VERSION "v1.6"

NS_ :

BS_:

BU_: INVCON0 VCU INVCON1 INVCON2 INVCON3 INVCON4 INVCON5

BO_ 292 VCU_INV5_06: 4 VCU
 SG_ SurgeDamperTreshold5 : 12|10@1+ (1,0) [0|1021] "Nm"  INVCON5
 SG_ SurgeDamperState5 : 0|2@1+ (1,0) [0|3] "-"  INVCON5
 SG_ SurgeDamperMaxTorque5 : 2|10@1+ (1,0) [0|1021] "Nm"  INVCON5
 SG_ SurgeDamperFactor5 : 24|8@1+ (0.03125,0) [0|7.96875] "-"  INVCON5

BO_ 291 VCU_INV4_06: 4 VCU
 SG_ SurgeDamperTreshold4 : 12|10@1+ (1,0) [0|1021] "Nm"  INVCON4
 SG_ SurgeDamperState4 : 0|2@1+ (1,0) [0|3] "-"  INVCON4
 SG_ SurgeDamperMaxTorque4 : 2|10@1+ (1,0) [0|1021] "Nm"  INVCON4
 SG_ SurgeDamperFactor4 : 24|8@1+ (0.03125,0) [0|7.96875] "-"  INVCON4

BO_ 290 VCU_INV3_06: 4 VCU
 SG_ SurgeDamperTreshold3 : 12|10@1+ (1,0) [0|1021] "Nm"  INVCON3
 SG_ SurgeDamperState3 : 0|2@1+ (1,0) [0|3] "-"  INVCON3
 SG_ SurgeDamperMaxTorque3 : 2|10@1+ (1,0) [0|1021] "Nm"  INVCON3
 SG_ SurgeDamperFactor3 : 24|8@1+ (0.03125,0) [0|7.96875] "-"  INVCON3

BO_ 289 VCU_INV2_06: 4 VCU
 SG_ SurgeDamperTreshold2 : 12|10@1+ (1,0) [0|1021] "Nm"  INVCON2
 SG_ SurgeDamperState2 : 0|2@1+ (1,0) [0|3] "-"  INVCON2
 SG_ SurgeDamperMaxTorque2 : 2|10@1+ (1,0) [0|1021] "Nm"  INVCON2
 SG_ SurgeDamperFactor2 : 24|8@1+ (0.03125,0) [0|7.96875] "-"  INVCON2

BO_ 288 VCU_INV1_06: 4 VCU
 SG_ SurgeDamperTreshold1 : 12|10@1+ (1,0) [0|1021] "Nm"  INVCON1
 SG_ SurgeDamperState1 : 0|2@1+ (1,0) [0|3] "-"  INVCON1
 SG_ SurgeDamperMaxTorque1 : 2|10@1+ (1,0) [0|1021] "Nm"  INVCON1
 SG_ SurgeDamperFactor1 : 24|8@1+ (0.03125,0) [0|7.96875] "-"  INVCON1

BO_ 1663 INV0_VCU_07: 8 INVCON0
 SG_ INV0_FailCode4 : 48|16@1+ (1,0) [0|65535] "-"  VCU
 SG_ INV0_FailCode3 : 32|16@1+ (1,0) [0|65535] "-"  VCU
 SG_ INV0_FailCode2 : 16|16@1+ (1,0) [0|65535] "-"  VCU
 SG_ INV0_FailCode1 : 0|16@1+ (1,0) [0|65535] "-"  VCU

BO_ 1668 INV5_VCU_07: 8 INVCON5
 SG_ INV5_FailCode4 : 48|16@1+ (1,0) [0|65535] "-"  VCU
 SG_ INV5_FailCode3 : 32|16@1+ (1,0) [0|65535] "-"  VCU
 SG_ INV5_FailCode2 : 16|16@1+ (1,0) [0|65535] "-"  VCU
 SG_ INV5_FailCode1 : 0|16@1+ (1,0) [0|65535] "-"  VCU

BO_ 1667 INV4_VCU_07: 8 INVCON4
 SG_ INV4_FailCode4 : 48|16@1+ (1,0) [0|65535] "-"  VCU
 SG_ INV4_FailCode3 : 32|16@1+ (1,0) [0|65535] "-"  VCU
 SG_ INV4_FailCode2 : 16|16@1+ (1,0) [0|65535] "-"  VCU
 SG_ INV4_FailCode1 : 0|16@1+ (1,0) [0|65535] "-"  VCU

BO_ 1666 INV3_VCU_07: 8 INVCON3
 SG_ INV3_FailCode4 : 48|16@1+ (1,0) [0|65535] "-"  VCU
 SG_ INV3_FailCode3 : 32|16@1+ (1,0) [0|65535] "-"  VCU
 SG_ INV3_FailCode2 : 16|16@1+ (1,0) [0|65535] "-"  VCU
 SG_ INV3_FailCode1 : 0|16@1+ (1,0) [0|65535] "-"  VCU

BO_ 1665 INV2_VCU_07: 8 INVCON2
 SG_ INV2_FailCode4 : 48|16@1+ (1,0) [0|65535] "-"  VCU
 SG_ INV2_FailCode3 : 32|16@1+ (1,0) [0|65535] "-"  VCU
 SG_ INV2_FailCode2 : 16|16@1+ (1,0) [0|65535] "-"  VCU
 SG_ INV2_FailCode1 : 0|16@1+ (1,0) [0|65535] "-"  VCU

BO_ 1664 INV1_VCU_07: 8 INVCON1
 SG_ INV1_FailCode4 : 48|16@1+ (1,0) [0|65535] "-"  VCU
 SG_ INV1_FailCode3 : 32|16@1+ (1,0) [0|65535] "-"  VCU
 SG_ INV1_FailCode2 : 16|16@1+ (1,0) [0|65535] "-"  VCU
 SG_ INV1_FailCode1 : 0|16@1+ (1,0) [0|65535] "-"  VCU

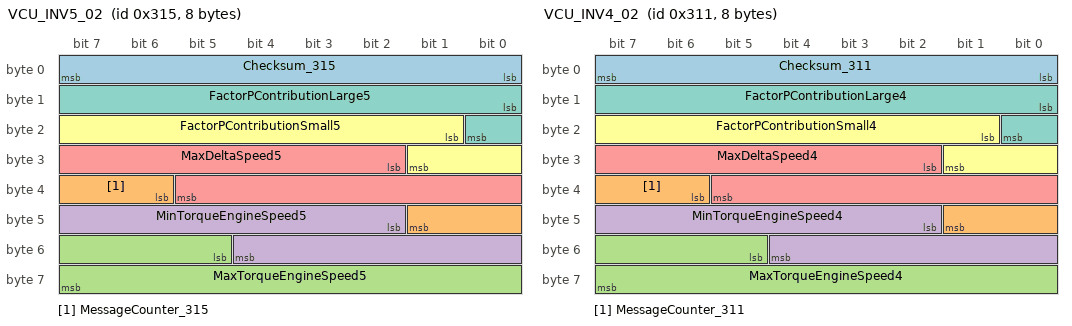
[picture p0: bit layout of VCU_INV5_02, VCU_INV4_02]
BO_ 789 VCU_INV5_02: 8 VCU
 SG_ Checksum_315 : 0|8@1+ (1,0) [0|255] "-"  INVCON5
 SG_ MessageCounter_315 : 38|4@1+ (1,0) [0|15] "-"  INVCON5
 SG_ MaxTorqueEngineSpeed5 : 53|11@1+ (1,-1023) [-1023|1022] "Nm"  INVCON5
 SG_ MinTorqueEngineSpeed5 : 42|11@1+ (1,-1023) [-1023|1022] "Nm"  INVCON5
 SG_ MaxDeltaSpeed5 : 26|12@1+ (8,-16380) [-16380|16364] "1/min"  INVCON5
 SG_ FactorPContributionSmall5 : 17|9@1+ (0.0009765625,0) [0|0.4990234375] "-"  INVCON5
 SG_ FactorPContributionLarge5 : 8|9@1+ (0.0009765625,0) [0|0.4990234375] "-"  INVCON5

BO_ 785 VCU_INV4_02: 8 VCU
 SG_ Checksum_311 : 0|8@1+ (1,0) [0|255] "-"  INVCON4
 SG_ MessageCounter_311 : 38|4@1+ (1,0) [0|15] "-"  INVCON4
 SG_ MaxTorqueEngineSpeed4 : 53|11@1+ (1,-1023) [-1023|1022] "Nm"  INVCON4
 SG_ MinTorqueEngineSpeed4 : 42|11@1+ (1,-1023) [-1023|1022] "Nm"  INVCON4
 SG_ MaxDeltaSpeed4 : 26|12@1+ (8,-16380) [-16380|16364] "1/min"  INVCON4
 SG_ FactorPContributionSmall4 : 17|9@1+ (0.0009765625,0) [0|0.4990234375] "-"  INVCON4
 SG_ FactorPContributionLarge4 : 8|9@1+ (0.0009765625,0) [0|0.4990234375] "-"  INVCON4

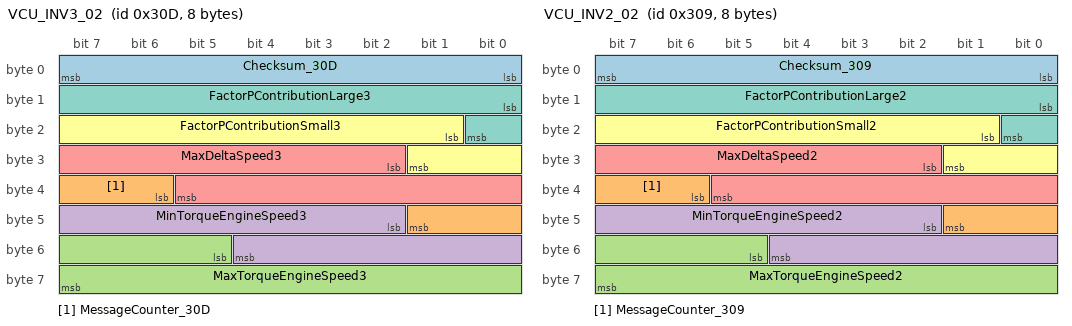
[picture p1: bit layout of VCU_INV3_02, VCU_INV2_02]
BO_ 781 VCU_INV3_02: 8 VCU
 SG_ Checksum_30D : 0|8@1+ (1,0) [0|255] "-"  INVCON3
 SG_ MessageCounter_30D : 38|4@1+ (1,0) [0|15] "-"  INVCON3
 SG_ MaxTorqueEngineSpeed3 : 53|11@1+ (1,-1023) [-1023|1022] "Nm"  INVCON3
 SG_ MinTorqueEngineSpeed3 : 42|11@1+ (1,-1023) [-1023|1022] "Nm"  INVCON3
 SG_ MaxDeltaSpeed3 : 26|12@1+ (8,-16380) [-16380|16364] "1/min"  INVCON3
 SG_ FactorPContributionSmall3 : 17|9@1+ (0.0009765625,0) [0|0.4990234375] "-"  INVCON3
 SG_ FactorPContributionLarge3 : 8|9@1+ (0.0009765625,0) [0|0.4990234375] "-"  INVCON3

BO_ 777 VCU_INV2_02: 8 VCU
 SG_ Checksum_309 : 0|8@1+ (1,0) [0|255] "-"  INVCON2
 SG_ MessageCounter_309 : 38|4@1+ (1,0) [0|15] "-"  INVCON2
 SG_ MaxTorqueEngineSpeed2 : 53|11@1+ (1,-1023) [-1023|1022] "Nm"  INVCON2
 SG_ MinTorqueEngineSpeed2 : 42|11@1+ (1,-1023) [-1023|1022] "Nm"  INVCON2
 SG_ MaxDeltaSpeed2 : 26|12@1+ (8,-16380) [-16380|16364] "1/min"  INVCON2
 SG_ FactorPContributionSmall2 : 17|9@1+ (0.0009765625,0) [0|0.4990234375] "-"  INVCON2
 SG_ FactorPContributionLarge2 : 8|9@1+ (0.0009765625,0) [0|0.4990234375] "-"  INVCON2

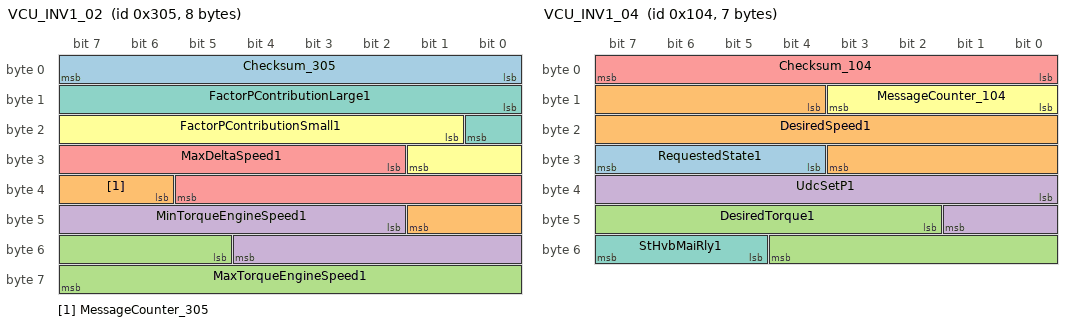
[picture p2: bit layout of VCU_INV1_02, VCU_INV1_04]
BO_ 773 VCU_INV1_02: 8 VCU
 SG_ Checksum_305 : 0|8@1+ (1,0) [0|255] "-"  INVCON1
 SG_ MessageCounter_305 : 38|4@1+ (1,0) [0|15] "-"  INVCON1
 SG_ MaxTorqueEngineSpeed1 : 53|11@1+ (1,-1023) [-1023|1022] "Nm"  INVCON1
 SG_ MinTorqueEngineSpeed1 : 42|11@1+ (1,-1023) [-1023|1022] "Nm"  INVCON1
 SG_ MaxDeltaSpeed1 : 26|12@1+ (8,-16380) [-16380|16364] "1/min"  INVCON1
 SG_ FactorPContributionSmall1 : 17|9@1+ (0.0009765625,0) [0|0.4990234375] "-"  INVCON1
 SG_ FactorPContributionLarge1 : 8|9@1+ (0.0009765625,0) [0|0.4990234375] "-"  INVCON1

BO_ 260 VCU_INV1_04: 7 VCU
 SG_ RequestedState1 : 28|4@1+ (1,0) [0|15] "-"  INVCON1
 SG_ DesiredSpeed1 : 12|16@1+ (1,-32767) [-32767|32766] "1/min"  INVCON1
 SG_ DesiredTorque1 : 42|11@1+ (1,-1023) [-1023|1022] "Nm"  INVCON1
 SG_ UdcSetP1 : 32|10@1+ (1,0) [0|1021] "V"  INVCON1
 SG_ Checksum_104 : 0|8@1+ (1,0) [0|255] "-"  INVCON1
 SG_ MessageCounter_104 : 8|4@1+ (1,0) [0|15] "-"  INVCON1
 SG_ StHvbMaiRly1 : 53|3@1+ (1,0) [0|7] "-"  INVCON1

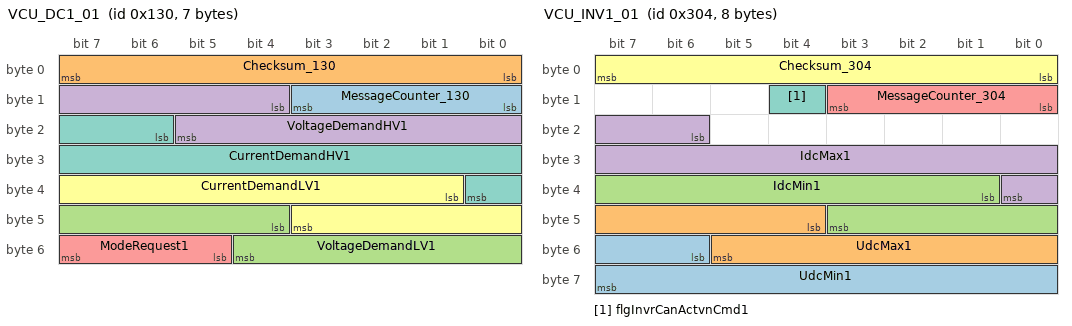
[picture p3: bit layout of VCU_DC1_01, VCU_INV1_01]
BO_ 304 VCU_DC1_01: 7 VCU
 SG_ MessageCounter_130 : 8|4@1+ (1,0) [0|15] "-"  INVCON1
 SG_ Checksum_130 : 0|8@1+ (1,0) [0|255] "-"  INVCON1
 SG_ VoltageDemandLV1 : 44|9@1+ (0.125,0) [0|63.875] "V"  INVCON1
 SG_ VoltageDemandHV1 : 12|10@1+ (1,0) [0|1021] "V"  INVCON1
 SG_ ModeRequest1 : 53|3@1+ (1,0) [0|7] "-"  INVCON1
 SG_ CurrentDemandLV1 : 33|11@1+ (1,-1023) [-1023|1022] "A"  INVCON1
 SG_ CurrentDemandHV1 : 22|11@1+ (0.0625,-64) [-64|63.8125] "A"  INVCON1

BO_ 772 VCU_INV1_01: 8 VCU
 SG_ UdcMin1 : 54|10@1+ (1,0) [0|1021] "V"  INVCON1
 SG_ UdcMax1 : 44|10@1+ (1,0) [0|1021] "V"  INVCON1
 SG_ IdcMin1 : 33|11@1+ (1,-1023) [-1023|1022] "A"  INVCON1
 SG_ IdcMax1 : 22|11@1+ (1,-1023) [-1023|1022] "A"  INVCON1
 SG_ MessageCounter_304 : 8|4@1+ (1,0) [0|15] "-"  INVCON1
 SG_ Checksum_304 : 0|8@1+ (1,0) [0|255] "-"  INVCON1
 SG_ flgInvrCanActvnCmd1 : 12|1@1+ (1,0) [0|1] "-"  INVCON1

BO_ 774 VCU_INV1_03: 8 VCU
 SG_ KI_Faktor1 : 49|15@1+ (0.0009765625,0) [0|31.9990234375] "-"  INVCON1
 SG_ MessageCounter_306 : 8|4@1+ (1,0) [0|15] "-"  INVCON1
 SG_ Checksum_306 : 0|8@1+ (1,0) [0|255] "-"  INVCON1
 SG_ MinTorqueLimit1 : 12|11@1+ (1,-1023) [-1023|1022] "Nm"  INVCON1
 SG_ MaxTorqueLimit1 : 38|11@1+ (1,-1023) [-1023|1022] "Nm"  INVCON1
 SG_ MaxTorqueGradient1 : 23|15@1+ (32,0) [0|1048480] "Nm/s"  INVCON1

BO_ 516 INV1_VCU_01: 7 INVCON1
 SG_ CurrentHV1 : 32|11@1+ (1,-1023) [-1023|1024] "A"  VCU
 SG_ OutputTorque1 : 43|11@1+ (1,-1023) [-1023|1024] "Nm"  VCU
 SG_ State1 : 12|4@1+ (1,0) [0|15] "-"  VCU
 SG_ Speed1 : 16|16@1+ (1,-32767) [-32767|32766] "1/min"  VCU
 SG_ Checksum_204 : 0|8@1+ (1,0) [0|255] "-"  VCU
 SG_ MessageCounter_204 : 8|4@1+ (1,0) [0|15] "-"  VCU

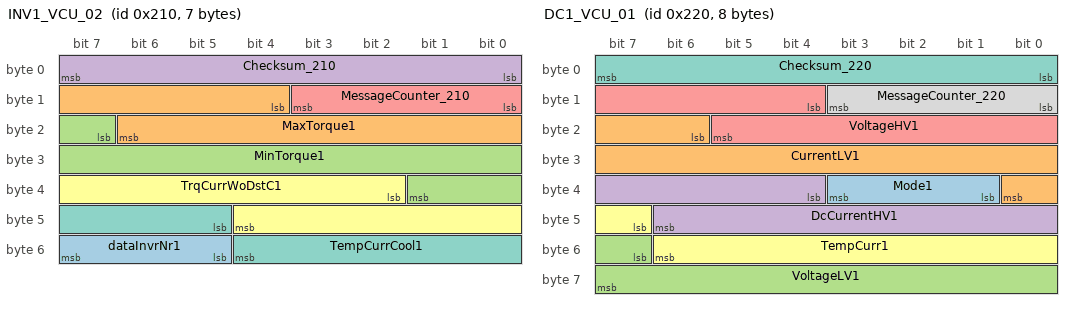
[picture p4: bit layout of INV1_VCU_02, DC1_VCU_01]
BO_ 528 INV1_VCU_02: 7 INVCON1
 SG_ dataInvrNr1 : 53|3@1+ (1,0) [0|5] ""  VCU
 SG_ MaxTorque1 : 12|11@1+ (1,-1023) [-1023|1024] "Nm"  VCU
 SG_ MinTorque1 : 23|11@1+ (1,-1023) [-1023|1024] "Nm"  VCU
 SG_ Checksum_210 : 0|8@1+ (1,0) [0|255] "-"  VCU
 SG_ MessageCounter_210 : 8|4@1+ (1,0) [0|15] "-"  VCU
 SG_ TrqCurrWoDstC1 : 34|11@1+ (1,-1023) [-1023|1024] "Nm"  VCU
 SG_ TempCurrCool1 : 45|8@1+ (1,-40) [-40|213] "°C"  VCU

BO_ 544 DC1_VCU_01: 8 INVCON1
 SG_ Mode1 : 33|3@1+ (1,0) [0|7] "-"  VCU
 SG_ CurrentLV1 : 22|11@1+ (1,-1023) [-1023|1024] "A"  VCU
 SG_ VoltageLV1 : 55|9@1+ (0.125,0) [0|63.875] "V"  VCU
 SG_ DcCurrentHV1 : 36|11@1+ (0.0625,-64) [-64|63.9375] "A"  VCU
 SG_ VoltageHV1 : 12|10@1+ (1,0) [0|1023] "V"  VCU
 SG_ TempCurr1 : 47|8@1+ (1,-40) [-40|213] "°C"  VCU
 SG_ Checksum_220 : 0|8@1+ (1,0) [0|255] "-"  VCU
 SG_ MessageCounter_220 : 8|4@1+ (1,0) [0|15] "-"  VCU

BO_ 1568 INV1_VCU_04: 6 INVCON1
 SG_ ElectricMachineTemperature1 : 16|8@1+ (1,-40) [-40|213] "°C"  VCU
 SG_ InverterTemperature1 : 24|8@1+ (1,-40) [-40|213] "°C"  VCU
 SG_ UT30Curr1 : 32|6@1+ (0.5,0) [0|31.5] "V"  VCU
 SG_ TempCurrRotor1 : 38|8@1+ (1,-40) [-40|213] "°C"  VCU
 SG_ Checksum_620 : 0|8@1+ (1,0) [0|255] "-"  VCU
 SG_ MessageCounter_620 : 8|4@1+ (1,0) [0|15] "-"  VCU

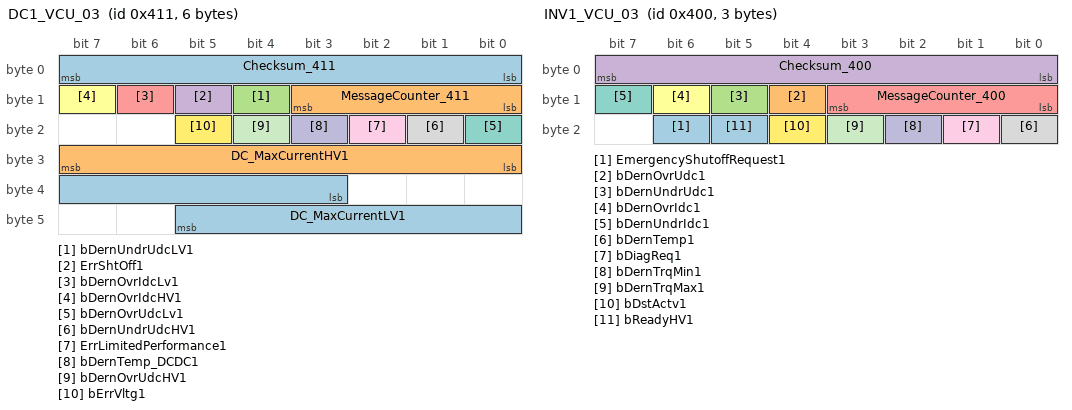
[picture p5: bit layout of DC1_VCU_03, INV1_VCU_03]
BO_ 1041 DC1_VCU_03: 6 INVCON1
 SG_ DC_MaxCurrentLV1 : 35|11@1+ (1,-1023) [-1023|1024] "A"  VCU
 SG_ DC_MaxCurrentHV1 : 24|8@1+ (0.25,0) [0|63.75] "A"  VCU
 SG_ bDernUndrUdcLV1 : 12|1@1+ (1,0) [0|1] "-"  VCU
 SG_ ErrShtOff1 : 13|1@1+ (1,0) [0|1] "-"  VCU
 SG_ bDernOvrIdcLv1 : 14|1@1+ (1,0) [0|1] "-"  VCU
 SG_ bDernOvrIdcHV1 : 15|1@1+ (1,0) [0|1] "-"  VCU
 SG_ bDernOvrUdcLv1 : 16|1@1+ (1,0) [0|1] "-"  VCU
 SG_ bDernUndrUdcHV1 : 17|1@1+ (1,0) [0|1] "-"  VCU
 SG_ ErrLimitedPerformance1 : 18|1@1+ (1,0) [0|1] "-"  VCU
 SG_ bDernTemp_DCDC1 : 19|1@1+ (1,0) [0|1] "-"  VCU
 SG_ bDernOvrUdcHV1 : 20|1@1+ (1,0) [0|1] "-"  VCU
 SG_ bErrVltg1 : 21|1@1+ (1,0) [0|1] "-"  VCU
 SG_ Checksum_411 : 0|8@1+ (1,0) [0|255] "-"  VCU
 SG_ MessageCounter_411 : 8|4@1+ (1,0) [0|15] "-"  VCU

BO_ 1024 INV1_VCU_03: 3 INVCON1
 SG_ EmergencyShutoffRequest1 : 22|1@1+ (1,0) [0|1] "-"  VCU
 SG_ bDernOvrUdc1 : 12|1@1+ (1,0) [0|1] "-"  VCU
 SG_ bDernUndrUdc1 : 13|1@1+ (1,0) [0|1] "-"  VCU
 SG_ Checksum_400 : 0|8@1+ (1,0) [0|255] "-"  VCU
 SG_ MessageCounter_400 : 8|4@1+ (1,0) [0|15] "-"  VCU
 SG_ bDernOvrIdc1 : 14|1@1+ (1,0) [0|1] "-"  VCU
 SG_ bDernUndrIdc1 : 15|1@1+ (1,0) [0|1] "-"  VCU
 SG_ bDernTemp1 : 16|1@1+ (1,0) [0|1] "-"  VCU
 SG_ bDiagReq1 : 17|1@1+ (1,0) [0|1] "-"  VCU
 SG_ bDernTrqMin1 : 18|1@1+ (1,0) [0|1] "-"  VCU
 SG_ bDernTrqMax1 : 19|1@1+ (1,0) [0|1] "-"  VCU
 SG_ bDstActv1 : 20|1@1+ (1,0) [0|1] "-"  VCU
 SG_ bReadyHV1 : 21|1@1+ (1,0) [0|1] "-"  VCU

BO_ 110 BMS_VCU_INV_01: 7 VCU
 SG_ bErrEmergencyDischargeReq : 36|1@1+ (1,0) [0|1] ""  INVCON1,INVCON2,INVCON3,INVCON5,INVCON4
 SG_ MessageCounter_6E : 8|4@1+ (1,0) [0|15] "-"  INVCON1,INVCON2,INVCON3,INVCON4,INVCON5
 SG_ Checksum_6E : 0|8@1+ (1,0) [0|255] "-"  INVCON1,INVCON2,INVCON3,INVCON4,INVCON5
 SG_ ContactorState : 48|4@1+ (1,0) [0|7] "-"  INVCON1,INVCON2,INVCON3,INVCON4,INVCON5
 SG_ Current : 12|12@1+ (0.25,-511) [-511|512.25] "A"  INVCON1,INVCON2,INVCON3,INVCON4,INVCON5
 SG_ Voltage : 24|12@1+ (0.25,0) [0|1023.25] "V"  INVCON1,INVCON2,INVCON3,INVCON4,INVCON5

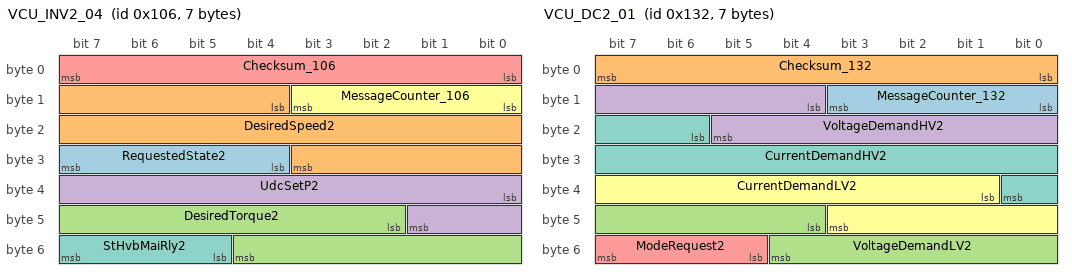
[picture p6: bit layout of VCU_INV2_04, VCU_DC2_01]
BO_ 262 VCU_INV2_04: 7 VCU
 SG_ RequestedState2 : 28|4@1+ (1,0) [0|15] "-"  INVCON2
 SG_ DesiredSpeed2 : 12|16@1+ (1,-32767) [-32767|32766] "1/min"  INVCON2
 SG_ DesiredTorque2 : 42|11@1+ (1,-1023) [-1023|1022] "Nm"  INVCON2
 SG_ UdcSetP2 : 32|10@1+ (1,0) [0|1021] "V"  INVCON2
 SG_ Checksum_106 : 0|8@1+ (1,0) [0|255] "-"  INVCON2
 SG_ MessageCounter_106 : 8|4@1+ (1,0) [0|15] "-"  INVCON2
 SG_ StHvbMaiRly2 : 53|3@1+ (1,0) [0|7] "-"  INVCON2

BO_ 306 VCU_DC2_01: 7 VCU
 SG_ MessageCounter_132 : 8|4@1+ (1,0) [0|15] "-"  INVCON2
 SG_ Checksum_132 : 0|8@1+ (1,0) [0|255] "-"  INVCON2
 SG_ VoltageDemandLV2 : 44|9@1+ (0.125,0) [0|63.875] "V"  INVCON2
 SG_ VoltageDemandHV2 : 12|10@1+ (1,0) [0|1021] "V"  INVCON2
 SG_ ModeRequest2 : 53|3@1+ (1,0) [0|7] "-"  INVCON2
 SG_ CurrentDemandLV2 : 33|11@1+ (1,-1023) [-1023|1022] "A"  INVCON2
 SG_ CurrentDemandHV2 : 22|11@1+ (0.0625,-64) [-64|63.8125] "A"  INVCON2

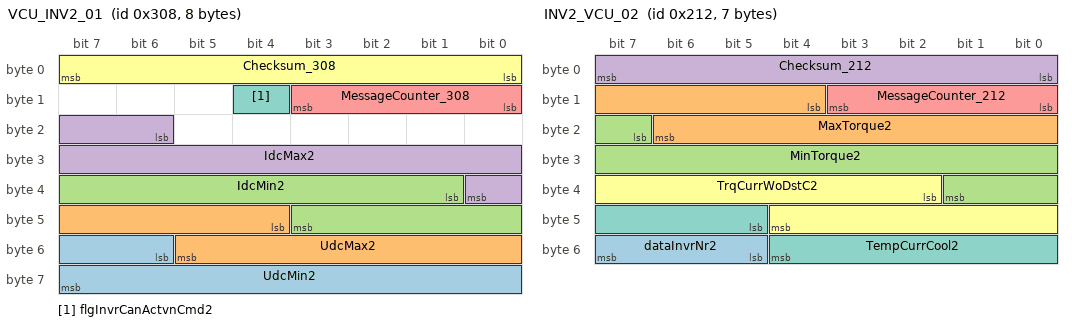
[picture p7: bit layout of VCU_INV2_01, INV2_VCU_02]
BO_ 776 VCU_INV2_01: 8 VCU
 SG_ UdcMin2 : 54|10@1+ (1,0) [0|1021] "V"  INVCON2
 SG_ UdcMax2 : 44|10@1+ (1,0) [0|1021] "V"  INVCON2
 SG_ IdcMin2 : 33|11@1+ (1,-1023) [-1023|1022] "A"  INVCON2
 SG_ IdcMax2 : 22|11@1+ (1,-1023) [-1023|1022] "A"  INVCON2
 SG_ MessageCounter_308 : 8|4@1+ (1,0) [0|15] "-"  INVCON2
 SG_ Checksum_308 : 0|8@1+ (1,0) [0|255] "-"  INVCON2
 SG_ flgInvrCanActvnCmd2 : 12|1@1+ (1,0) [0|1] "-"  INVCON2

BO_ 778 VCU_INV2_03: 8 VCU
 SG_ KI_Faktor2 : 49|15@1+ (0.0009765625,0) [0|31.9990234375] "-"  INVCON2
 SG_ MessageCounter_30A : 8|4@1+ (1,0) [0|15] "-"  INVCON2
 SG_ Checksum_30A : 0|8@1+ (1,0) [0|255] "-"  INVCON2
 SG_ MinTorqueLimit2 : 12|11@1+ (1,-1023) [-1023|1022] "Nm"  INVCON2
 SG_ MaxTorqueLimit2 : 38|11@1+ (1,-1023) [-1023|1022] "Nm"  INVCON2
 SG_ MaxTorqueGradient2 : 23|15@1+ (32,0) [0|1048480] "Nm/s"  INVCON2

BO_ 518 INV2_VCU_01: 7 INVCON2
 SG_ CurrentHV2 : 32|11@1+ (1,-1023) [-1023|1024] "A"  VCU
 SG_ OutputTorque2 : 43|11@1+ (1,-1023) [-1023|1024] "Nm"  VCU
 SG_ State2 : 12|4@1+ (1,0) [0|15] "-"  VCU
 SG_ Speed2 : 16|16@1+ (1,-32767) [-32767|32766] "1/min"  VCU
 SG_ Checksum_206 : 0|8@1+ (1,0) [0|255] "-"  VCU
 SG_ MessageCounter_206 : 8|4@1+ (1,0) [0|15] "-"  VCU

BO_ 530 INV2_VCU_02: 7 INVCON2
 SG_ dataInvrNr2 : 53|3@1+ (1,0) [0|5] ""  VCU
 SG_ MaxTorque2 : 12|11@1+ (1,-1023) [-1023|1024] "Nm"  VCU
 SG_ MinTorque2 : 23|11@1+ (1,-1023) [-1023|1024] "Nm"  VCU
 SG_ Checksum_212 : 0|8@1+ (1,0) [0|255] "-"  VCU
 SG_ MessageCounter_212 : 8|4@1+ (1,0) [0|15] "-"  VCU
 SG_ TrqCurrWoDstC2 : 34|11@1+ (1,-1023) [-1023|1024] "Nm"  VCU
 SG_ TempCurrCool2 : 45|8@1+ (1,-40) [-40|213] "°C"  VCU

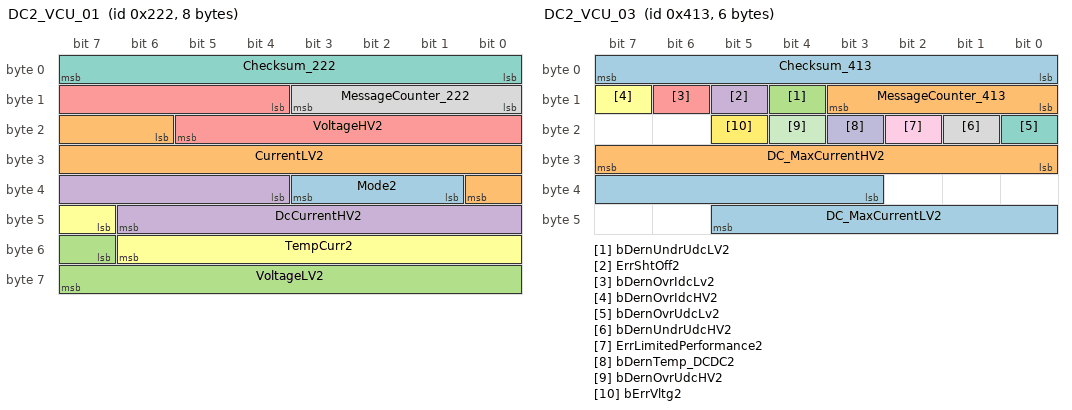
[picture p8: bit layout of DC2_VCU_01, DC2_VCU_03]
BO_ 546 DC2_VCU_01: 8 INVCON2
 SG_ Mode2 : 33|3@1+ (1,0) [0|7] "-"  VCU
 SG_ CurrentLV2 : 22|11@1+ (1,-1023) [-1023|1024] "A"  VCU
 SG_ VoltageLV2 : 55|9@1+ (0.125,0) [0|63.875] "V"  VCU
 SG_ DcCurrentHV2 : 36|11@1+ (0.0625,-64) [-64|63.9375] "A"  VCU
 SG_ VoltageHV2 : 12|10@1+ (1,0) [0|1023] "V"  VCU
 SG_ TempCurr2 : 47|8@1+ (1,-40) [-40|213] "°C"  VCU
 SG_ Checksum_222 : 0|8@1+ (1,0) [0|255] "-"  VCU
 SG_ MessageCounter_222 : 8|4@1+ (1,0) [0|15] "-"  VCU

BO_ 1570 INV2_VCU_04: 6 INVCON2
 SG_ ElectricMachineTemperature2 : 16|8@1+ (1,-40) [-40|213] "°C"  VCU
 SG_ InverterTemperature2 : 24|8@1+ (1,-40) [-40|213] "°C"  VCU
 SG_ UT30Curr2 : 32|6@1+ (0.5,0) [0|31.5] "V"  VCU
 SG_ TempCurrRotor2 : 38|8@1+ (1,-40) [-40|213] "°C"  VCU
 SG_ Checksum_622 : 0|8@1+ (1,0) [0|255] "-"  VCU
 SG_ MessageCounter_622 : 8|4@1+ (1,0) [0|15] "-"  VCU

BO_ 1043 DC2_VCU_03: 6 INVCON2
 SG_ DC_MaxCurrentLV2 : 35|11@1+ (1,-1023) [-1023|1024] "A"  VCU
 SG_ DC_MaxCurrentHV2 : 24|8@1+ (0.25,0) [0|63.75] "A"  VCU
 SG_ bDernUndrUdcLV2 : 12|1@1+ (1,0) [0|1] "-"  VCU
 SG_ ErrShtOff2 : 13|1@1+ (1,0) [0|1] "-"  VCU
 SG_ bDernOvrIdcLv2 : 14|1@1+ (1,0) [0|1] "-"  VCU
 SG_ bDernOvrIdcHV2 : 15|1@1+ (1,0) [0|1] "-"  VCU
 SG_ bDernOvrUdcLv2 : 16|1@1+ (1,0) [0|1] "-"  VCU
 SG_ bDernUndrUdcHV2 : 17|1@1+ (1,0) [0|1] "-"  VCU
 SG_ ErrLimitedPerformance2 : 18|1@1+ (1,0) [0|1] "-"  VCU
 SG_ bDernTemp_DCDC2 : 19|1@1+ (1,0) [0|1] "-"  VCU
 SG_ bDernOvrUdcHV2 : 20|1@1+ (1,0) [0|1] "-"  VCU
 SG_ bErrVltg2 : 21|1@1+ (1,0) [0|1] "-"  VCU
 SG_ Checksum_413 : 0|8@1+ (1,0) [0|255] "-"  VCU
 SG_ MessageCounter_413 : 8|4@1+ (1,0) [0|15] "-"  VCU

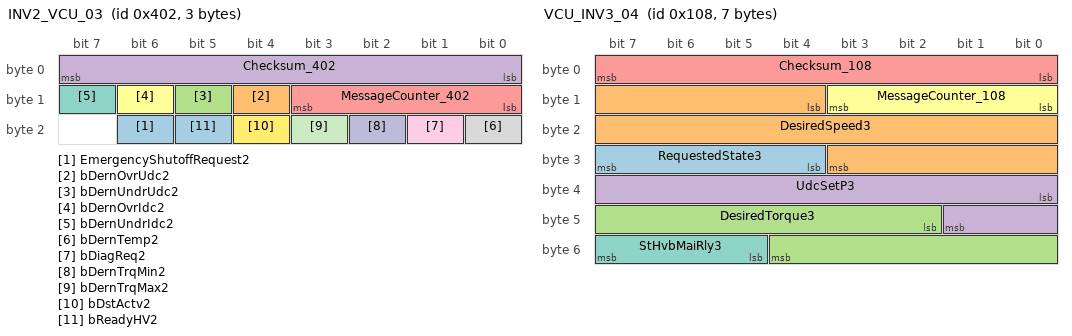
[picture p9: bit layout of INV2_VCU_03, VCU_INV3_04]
BO_ 1026 INV2_VCU_03: 3 INVCON2
 SG_ EmergencyShutoffRequest2 : 22|1@1+ (1,0) [0|1] "-"  VCU
 SG_ bDernOvrUdc2 : 12|1@1+ (1,0) [0|1] "-"  VCU
 SG_ bDernUndrUdc2 : 13|1@1+ (1,0) [0|1] "-"  VCU
 SG_ Checksum_402 : 0|8@1+ (1,0) [0|255] "-"  VCU
 SG_ MessageCounter_402 : 8|4@1+ (1,0) [0|15] "-"  VCU
 SG_ bDernOvrIdc2 : 14|1@1+ (1,0) [0|1] "-"  VCU
 SG_ bDernUndrIdc2 : 15|1@1+ (1,0) [0|1] "-"  VCU
 SG_ bDernTemp2 : 16|1@1+ (1,0) [0|1] "-"  VCU
 SG_ bDiagReq2 : 17|1@1+ (1,0) [0|1] "-"  VCU
 SG_ bDernTrqMin2 : 18|1@1+ (1,0) [0|1] "-"  VCU
 SG_ bDernTrqMax2 : 19|1@1+ (1,0) [0|1] "-"  VCU
 SG_ bDstActv2 : 20|1@1+ (1,0) [0|1] "-"  VCU
 SG_ bReadyHV2 : 21|1@1+ (1,0) [0|1] "-"  VCU

BO_ 264 VCU_INV3_04: 7 VCU
 SG_ RequestedState3 : 28|4@1+ (1,0) [0|15] "-"  INVCON3
 SG_ DesiredSpeed3 : 12|16@1+ (1,-32767) [-32767|32766] "1/min"  INVCON3
 SG_ DesiredTorque3 : 42|11@1+ (1,-1023) [-1023|1022] "Nm"  INVCON3
 SG_ UdcSetP3 : 32|10@1+ (1,0) [0|1021] "V"  INVCON3
 SG_ Checksum_108 : 0|8@1+ (1,0) [0|255] "-"  INVCON3
 SG_ MessageCounter_108 : 8|4@1+ (1,0) [0|15] "-"  INVCON3
 SG_ StHvbMaiRly3 : 53|3@1+ (1,0) [0|7] "-"  INVCON3

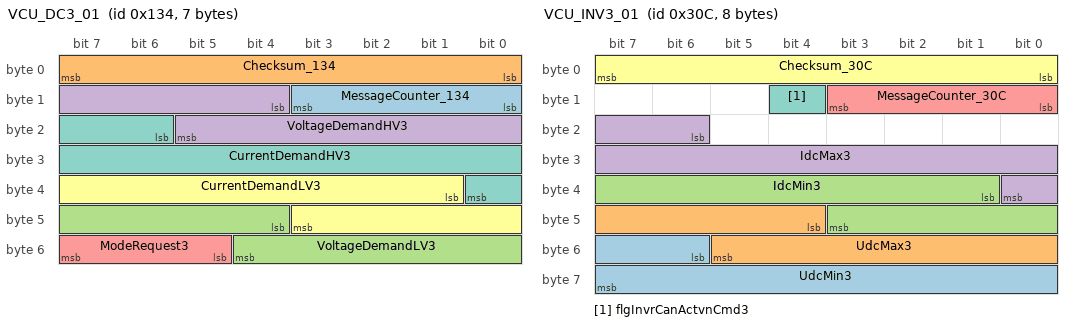
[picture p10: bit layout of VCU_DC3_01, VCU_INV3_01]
BO_ 308 VCU_DC3_01: 7 VCU
 SG_ MessageCounter_134 : 8|4@1+ (1,0) [0|15] "-"  INVCON3
 SG_ Checksum_134 : 0|8@1+ (1,0) [0|255] "-"  INVCON3
 SG_ VoltageDemandLV3 : 44|9@1+ (0.125,0) [0|63.875] "V"  INVCON3
 SG_ VoltageDemandHV3 : 12|10@1+ (1,0) [0|1021] "V"  INVCON3
 SG_ ModeRequest3 : 53|3@1+ (1,0) [0|7] "-"  INVCON3
 SG_ CurrentDemandLV3 : 33|11@1+ (1,-1023) [-1023|1022] "A"  INVCON3
 SG_ CurrentDemandHV3 : 22|11@1+ (0.0625,-64) [-64|63.8125] "A"  INVCON3

BO_ 780 VCU_INV3_01: 8 VCU
 SG_ UdcMin3 : 54|10@1+ (1,0) [0|1021] "V"  INVCON3
 SG_ UdcMax3 : 44|10@1+ (1,0) [0|1021] "V"  INVCON3
 SG_ IdcMin3 : 33|11@1+ (1,-1023) [-1023|1022] "A"  INVCON3
 SG_ IdcMax3 : 22|11@1+ (1,-1023) [-1023|1022] "A"  INVCON3
 SG_ MessageCounter_30C : 8|4@1+ (1,0) [0|15] "-"  INVCON3
 SG_ Checksum_30C : 0|8@1+ (1,0) [0|255] "-"  INVCON3
 SG_ flgInvrCanActvnCmd3 : 12|1@1+ (1,0) [0|1] "-"  INVCON3

BO_ 782 VCU_INV3_03: 8 VCU
 SG_ KI_Faktor3 : 49|15@1+ (0.0009765625,0) [0|31.9990234375] "-"  INVCON3
 SG_ MessageCounter_30E : 8|4@1+ (1,0) [0|15] "-"  INVCON3
 SG_ Checksum_30E : 0|8@1+ (1,0) [0|255] "-"  INVCON3
 SG_ MinTorqueLimit3 : 12|11@1+ (1,-1023) [-1023|1022] "Nm"  INVCON3
 SG_ MaxTorqueLimit3 : 38|11@1+ (1,-1023) [-1023|1022] "Nm"  INVCON3
 SG_ MaxTorqueGradient3 : 23|15@1+ (32,0) [0|1048480] "Nm/s"  INVCON3

BO_ 520 INV3_VCU_01: 7 INVCON3
 SG_ CurrentHV3 : 32|11@1+ (1,-1023) [-1023|1024] "A"  VCU
 SG_ OutputTorque3 : 43|11@1+ (1,-1023) [-1023|1024] "Nm"  VCU
 SG_ State3 : 12|4@1+ (1,0) [0|15] "-"  VCU
 SG_ Speed3 : 16|16@1+ (1,-32767) [-32767|32766] "1/min"  VCU
 SG_ Checksum_208 : 0|8@1+ (1,0) [0|255] "-"  VCU
 SG_ MessageCounter_208 : 8|4@1+ (1,0) [0|15] "-"  VCU

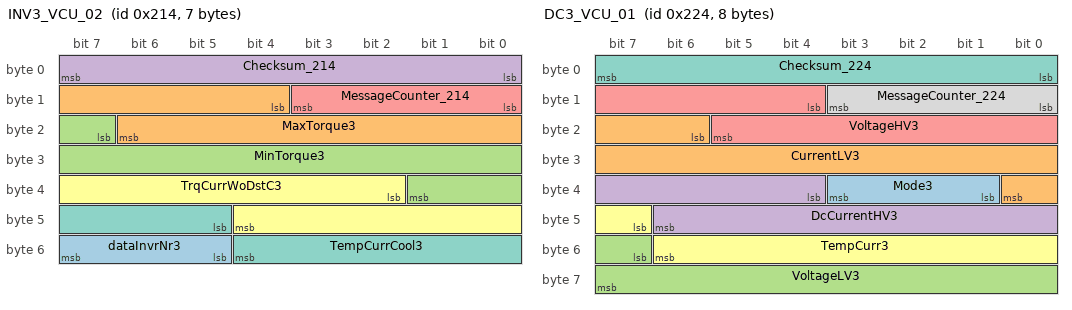
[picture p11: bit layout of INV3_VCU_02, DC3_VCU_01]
BO_ 532 INV3_VCU_02: 7 INVCON3
 SG_ dataInvrNr3 : 53|3@1+ (1,0) [0|5] ""  VCU
 SG_ MaxTorque3 : 12|11@1+ (1,-1023) [-1023|1024] "Nm"  VCU
 SG_ MinTorque3 : 23|11@1+ (1,-1023) [-1023|1024] "Nm"  VCU
 SG_ Checksum_214 : 0|8@1+ (1,0) [0|255] "-"  VCU
 SG_ MessageCounter_214 : 8|4@1+ (1,0) [0|15] "-"  VCU
 SG_ TrqCurrWoDstC3 : 34|11@1+ (1,-1023) [-1023|1024] "Nm"  VCU
 SG_ TempCurrCool3 : 45|8@1+ (1,-40) [-40|213] "°C"  VCU

BO_ 548 DC3_VCU_01: 8 INVCON3
 SG_ Mode3 : 33|3@1+ (1,0) [0|7] "-"  VCU
 SG_ CurrentLV3 : 22|11@1+ (1,-1023) [-1023|1024] "A"  VCU
 SG_ VoltageLV3 : 55|9@1+ (0.125,0) [0|63.875] "V"  VCU
 SG_ DcCurrentHV3 : 36|11@1+ (0.0625,-64) [-64|63.9375] "A"  VCU
 SG_ VoltageHV3 : 12|10@1+ (1,0) [0|1023] "V"  VCU
 SG_ TempCurr3 : 47|8@1+ (1,-40) [-40|213] "°C"  VCU
 SG_ Checksum_224 : 0|8@1+ (1,0) [0|255] "-"  VCU
 SG_ MessageCounter_224 : 8|4@1+ (1,0) [0|15] "-"  VCU

BO_ 1572 INV3_VCU_04: 6 INVCON3
 SG_ ElectricMachineTemperature3 : 16|8@1+ (1,-40) [-40|213] "°C"  VCU
 SG_ InverterTemperature3 : 24|8@1+ (1,-40) [-40|213] "°C"  VCU
 SG_ UT30Curr3 : 32|6@1+ (0.5,0) [0|31.5] "V"  VCU
 SG_ TempCurrRotor3 : 38|8@1+ (1,-40) [-40|213] "°C"  VCU
 SG_ Checksum_624 : 0|8@1+ (1,0) [0|255] "-"  VCU
 SG_ MessageCounter_624 : 8|4@1+ (1,0) [0|15] "-"  VCU

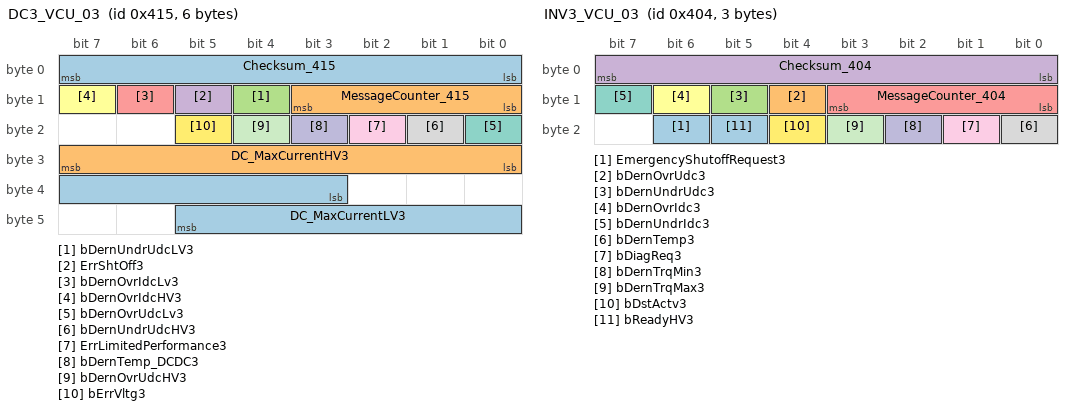
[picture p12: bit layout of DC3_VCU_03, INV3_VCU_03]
BO_ 1045 DC3_VCU_03: 6 INVCON3
 SG_ DC_MaxCurrentLV3 : 35|11@1+ (1,-1023) [-1023|1024] "A"  VCU
 SG_ DC_MaxCurrentHV3 : 24|8@1+ (0.25,0) [0|63.75] "A"  VCU
 SG_ bDernUndrUdcLV3 : 12|1@1+ (1,0) [0|1] "-"  VCU
 SG_ ErrShtOff3 : 13|1@1+ (1,0) [0|1] "-"  VCU
 SG_ bDernOvrIdcLv3 : 14|1@1+ (1,0) [0|1] "-"  VCU
 SG_ bDernOvrIdcHV3 : 15|1@1+ (1,0) [0|1] "-"  VCU
 SG_ bDernOvrUdcLv3 : 16|1@1+ (1,0) [0|1] "-"  VCU
 SG_ bDernUndrUdcHV3 : 17|1@1+ (1,0) [0|1] "-"  VCU
 SG_ ErrLimitedPerformance3 : 18|1@1+ (1,0) [0|1] "-"  VCU
 SG_ bDernTemp_DCDC3 : 19|1@1+ (1,0) [0|1] "-"  VCU
 SG_ bDernOvrUdcHV3 : 20|1@1+ (1,0) [0|1] "-"  VCU
 SG_ bErrVltg3 : 21|1@1+ (1,0) [0|1] "-"  VCU
 SG_ Checksum_415 : 0|8@1+ (1,0) [0|255] "-"  VCU
 SG_ MessageCounter_415 : 8|4@1+ (1,0) [0|15] "-"  VCU

BO_ 1028 INV3_VCU_03: 3 INVCON3
 SG_ EmergencyShutoffRequest3 : 22|1@1+ (1,0) [0|1] "-"  VCU
 SG_ bDernOvrUdc3 : 12|1@1+ (1,0) [0|1] "-"  VCU
 SG_ bDernUndrUdc3 : 13|1@1+ (1,0) [0|1] "-"  VCU
 SG_ Checksum_404 : 0|8@1+ (1,0) [0|255] "-"  VCU
 SG_ MessageCounter_404 : 8|4@1+ (1,0) [0|15] "-"  VCU
 SG_ bDernOvrIdc3 : 14|1@1+ (1,0) [0|1] "-"  VCU
 SG_ bDernUndrIdc3 : 15|1@1+ (1,0) [0|1] "-"  VCU
 SG_ bDernTemp3 : 16|1@1+ (1,0) [0|1] "-"  VCU
 SG_ bDiagReq3 : 17|1@1+ (1,0) [0|1] "-"  VCU
 SG_ bDernTrqMin3 : 18|1@1+ (1,0) [0|1] "-"  VCU
 SG_ bDernTrqMax3 : 19|1@1+ (1,0) [0|1] "-"  VCU
 SG_ bDstActv3 : 20|1@1+ (1,0) [0|1] "-"  VCU
 SG_ bReadyHV3 : 21|1@1+ (1,0) [0|1] "-"  VCU

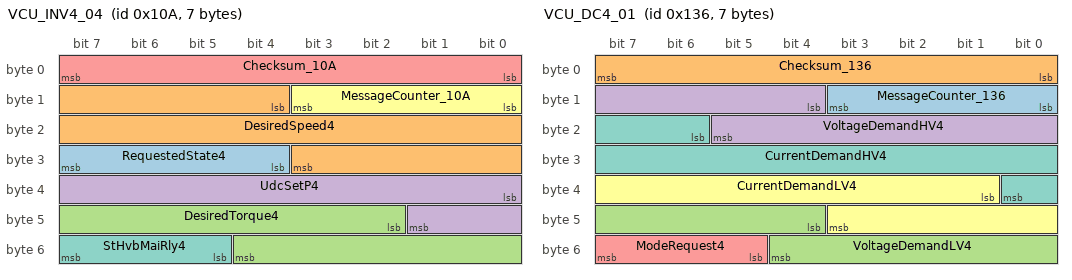
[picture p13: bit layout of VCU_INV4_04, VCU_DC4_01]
BO_ 266 VCU_INV4_04: 7 VCU
 SG_ RequestedState4 : 28|4@1+ (1,0) [0|15] "-"  INVCON4
 SG_ DesiredSpeed4 : 12|16@1+ (1,-32767) [-32767|32766] "1/min"  INVCON4
 SG_ DesiredTorque4 : 42|11@1+ (1,-1023) [-1023|1022] "Nm"  INVCON4
 SG_ UdcSetP4 : 32|10@1+ (1,0) [0|1021] "V"  INVCON4
 SG_ Checksum_10A : 0|8@1+ (1,0) [0|255] "-"  INVCON4
 SG_ MessageCounter_10A : 8|4@1+ (1,0) [0|15] "-"  INVCON4
 SG_ StHvbMaiRly4 : 53|3@1+ (1,0) [0|7] "-"  INVCON4

BO_ 310 VCU_DC4_01: 7 VCU
 SG_ MessageCounter_136 : 8|4@1+ (1,0) [0|15] "-"  INVCON4
 SG_ Checksum_136 : 0|8@1+ (1,0) [0|255] "-"  INVCON4
 SG_ VoltageDemandLV4 : 44|9@1+ (0.125,0) [0|63.875] "V"  INVCON4
 SG_ VoltageDemandHV4 : 12|10@1+ (1,0) [0|1021] "V"  INVCON4
 SG_ ModeRequest4 : 53|3@1+ (1,0) [0|7] "-"  INVCON4
 SG_ CurrentDemandLV4 : 33|11@1+ (1,-1023) [-1023|1022] "A"  INVCON4
 SG_ CurrentDemandHV4 : 22|11@1+ (0.0625,-64) [-64|63.8125] "A"  INVCON4

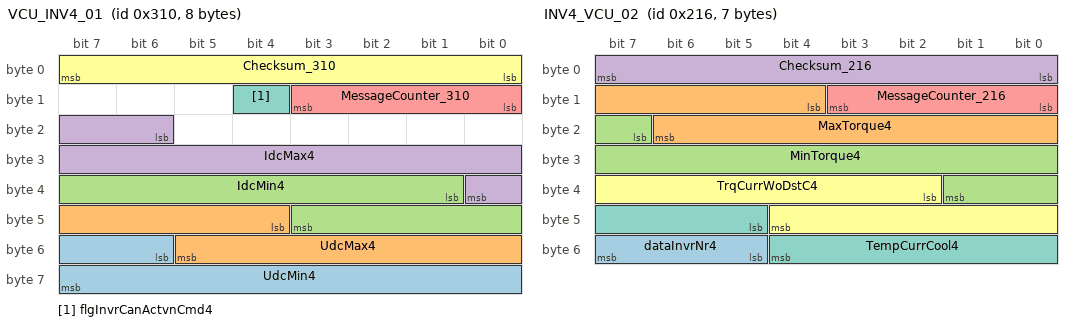
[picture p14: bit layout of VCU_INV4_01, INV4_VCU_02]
BO_ 784 VCU_INV4_01: 8 VCU
 SG_ UdcMin4 : 54|10@1+ (1,0) [0|1021] "V"  INVCON4
 SG_ UdcMax4 : 44|10@1+ (1,0) [0|1021] "V"  INVCON4
 SG_ IdcMin4 : 33|11@1+ (1,-1023) [-1023|1022] "A"  INVCON4
 SG_ IdcMax4 : 22|11@1+ (1,-1023) [-1023|1022] "A"  INVCON4
 SG_ MessageCounter_310 : 8|4@1+ (1,0) [0|15] "-"  INVCON4
 SG_ Checksum_310 : 0|8@1+ (1,0) [0|255] "-"  INVCON4
 SG_ flgInvrCanActvnCmd4 : 12|1@1+ (1,0) [0|1] "-"  INVCON4

BO_ 786 VCU_INV4_03: 8 VCU
 SG_ KI_Faktor4 : 49|15@1+ (0.0009765625,0) [0|31.9990234375] "-"  INVCON4
 SG_ MessageCounter_312 : 8|4@1+ (1,0) [0|15] "-"  INVCON4
 SG_ Checksum_312 : 0|8@1+ (1,0) [0|255] "-"  INVCON4
 SG_ MinTorqueLimit4 : 12|11@1+ (1,-1023) [-1023|1022] "Nm"  INVCON4
 SG_ MaxTorqueLimit4 : 38|11@1+ (1,-1023) [-1023|1022] "Nm"  INVCON4
 SG_ MaxTorqueGradient4 : 23|15@1+ (32,0) [0|1048480] "Nm/s"  INVCON4

BO_ 522 INV4_VCU_01: 7 INVCON4
 SG_ CurrentHV4 : 32|11@1+ (1,-1023) [-1023|1024] "A"  VCU
 SG_ OutputTorque4 : 43|11@1+ (1,-1023) [-1023|1024] "Nm"  VCU
 SG_ State4 : 12|4@1+ (1,0) [0|15] "-"  VCU
 SG_ Speed4 : 16|16@1+ (1,-32767) [-32767|32766] "1/min"  VCU
 SG_ Checksum_20A : 0|8@1+ (1,0) [0|255] "-"  VCU
 SG_ MessageCounter_20A : 8|4@1+ (1,0) [0|15] "-"  VCU

BO_ 534 INV4_VCU_02: 7 INVCON4
 SG_ dataInvrNr4 : 53|3@1+ (1,0) [0|5] ""  VCU
 SG_ MaxTorque4 : 12|11@1+ (1,-1023) [-1023|1024] "Nm"  VCU
 SG_ MinTorque4 : 23|11@1+ (1,-1023) [-1023|1024] "Nm"  VCU
 SG_ Checksum_216 : 0|8@1+ (1,0) [0|255] "-"  VCU
 SG_ MessageCounter_216 : 8|4@1+ (1,0) [0|15] "-"  VCU
 SG_ TrqCurrWoDstC4 : 34|11@1+ (1,-1023) [-1023|1024] "Nm"  VCU
 SG_ TempCurrCool4 : 45|8@1+ (1,-40) [-40|213] "°C"  VCU

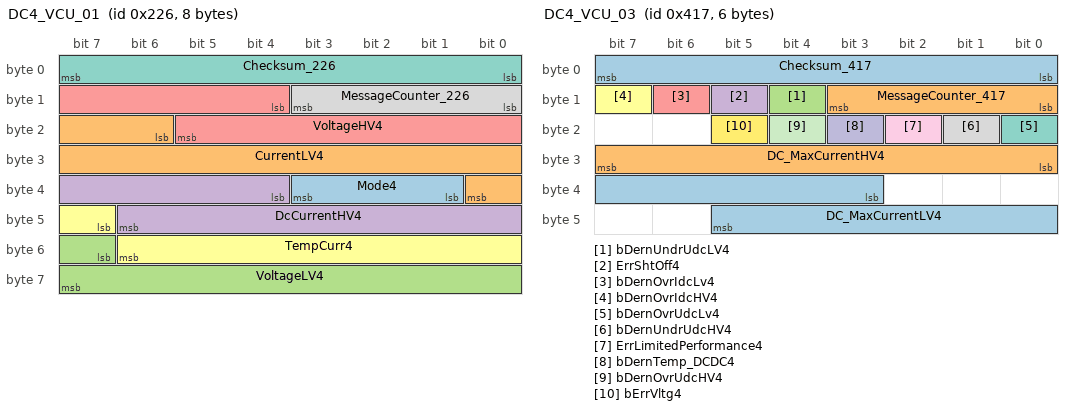
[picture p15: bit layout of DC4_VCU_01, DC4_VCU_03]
BO_ 550 DC4_VCU_01: 8 INVCON4
 SG_ Mode4 : 33|3@1+ (1,0) [0|7] "-"  VCU
 SG_ CurrentLV4 : 22|11@1+ (1,-1023) [-1023|1024] "A"  VCU
 SG_ VoltageLV4 : 55|9@1+ (0.125,0) [0|63.875] "V"  VCU
 SG_ DcCurrentHV4 : 36|11@1+ (0.0625,-64) [-64|63.9375] "A"  VCU
 SG_ VoltageHV4 : 12|10@1+ (1,0) [0|1023] "V"  VCU
 SG_ TempCurr4 : 47|8@1+ (1,-40) [-40|213] "°C"  VCU
 SG_ Checksum_226 : 0|8@1+ (1,0) [0|255] "-"  VCU
 SG_ MessageCounter_226 : 8|4@1+ (1,0) [0|15] "-"  VCU

BO_ 1574 INV4_VCU_04: 6 INVCON4
 SG_ ElectricMachineTemperature4 : 16|8@1+ (1,-40) [-40|213] "°C"  VCU
 SG_ InverterTemperature4 : 24|8@1+ (1,-40) [-40|213] "°C"  VCU
 SG_ UT30Curr4 : 32|6@1+ (0.5,0) [0|31.5] "V"  VCU
 SG_ TempCurrRotor4 : 38|8@1+ (1,-40) [-40|213] "°C"  VCU
 SG_ Checksum_626 : 0|8@1+ (1,0) [0|255] "-"  VCU
 SG_ MessageCounter_626 : 8|4@1+ (1,0) [0|15] "-"  VCU

BO_ 1047 DC4_VCU_03: 6 INVCON4
 SG_ DC_MaxCurrentLV4 : 35|11@1+ (1,-1023) [-1023|1024] "A"  VCU
 SG_ DC_MaxCurrentHV4 : 24|8@1+ (0.25,0) [0|63.75] "A"  VCU
 SG_ bDernUndrUdcLV4 : 12|1@1+ (1,0) [0|1] "-"  VCU
 SG_ ErrShtOff4 : 13|1@1+ (1,0) [0|1] "-"  VCU
 SG_ bDernOvrIdcLv4 : 14|1@1+ (1,0) [0|1] "-"  VCU
 SG_ bDernOvrIdcHV4 : 15|1@1+ (1,0) [0|1] "-"  VCU
 SG_ bDernOvrUdcLv4 : 16|1@1+ (1,0) [0|1] "-"  VCU
 SG_ bDernUndrUdcHV4 : 17|1@1+ (1,0) [0|1] "-"  VCU
 SG_ ErrLimitedPerformance4 : 18|1@1+ (1,0) [0|1] "-"  VCU
 SG_ bDernTemp_DCDC4 : 19|1@1+ (1,0) [0|1] "-"  VCU
 SG_ bDernOvrUdcHV4 : 20|1@1+ (1,0) [0|1] "-"  VCU
 SG_ bErrVltg4 : 21|1@1+ (1,0) [0|1] "-"  VCU
 SG_ Checksum_417 : 0|8@1+ (1,0) [0|255] "-"  VCU
 SG_ MessageCounter_417 : 8|4@1+ (1,0) [0|15] "-"  VCU

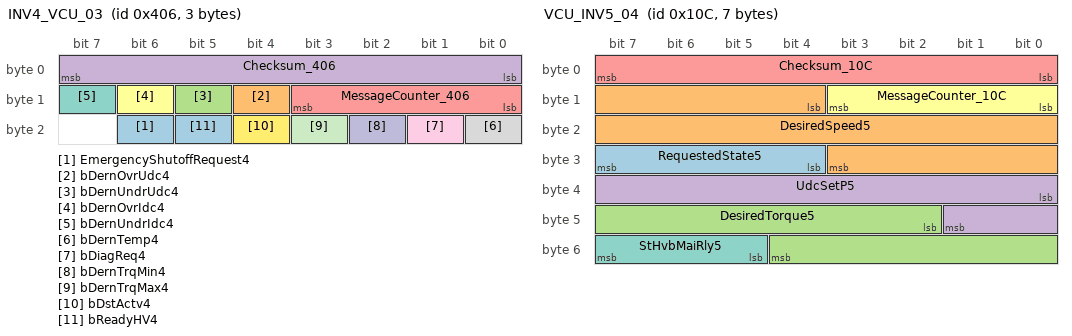
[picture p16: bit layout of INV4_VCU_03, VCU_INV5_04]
BO_ 1030 INV4_VCU_03: 3 INVCON4
 SG_ EmergencyShutoffRequest4 : 22|1@1+ (1,0) [0|1] "-"  VCU
 SG_ bDernOvrUdc4 : 12|1@1+ (1,0) [0|1] "-"  VCU
 SG_ bDernUndrUdc4 : 13|1@1+ (1,0) [0|1] "-"  VCU
 SG_ Checksum_406 : 0|8@1+ (1,0) [0|255] "-"  VCU
 SG_ MessageCounter_406 : 8|4@1+ (1,0) [0|15] "-"  VCU
 SG_ bDernOvrIdc4 : 14|1@1+ (1,0) [0|1] "-"  VCU
 SG_ bDernUndrIdc4 : 15|1@1+ (1,0) [0|1] "-"  VCU
 SG_ bDernTemp4 : 16|1@1+ (1,0) [0|1] "-"  VCU
 SG_ bDiagReq4 : 17|1@1+ (1,0) [0|1] "-"  VCU
 SG_ bDernTrqMin4 : 18|1@1+ (1,0) [0|1] "-"  VCU
 SG_ bDernTrqMax4 : 19|1@1+ (1,0) [0|1] "-"  VCU
 SG_ bDstActv4 : 20|1@1+ (1,0) [0|1] "-"  VCU
 SG_ bReadyHV4 : 21|1@1+ (1,0) [0|1] "-"  VCU

BO_ 268 VCU_INV5_04: 7 VCU
 SG_ RequestedState5 : 28|4@1+ (1,0) [0|15] "-"  INVCON5
 SG_ DesiredSpeed5 : 12|16@1+ (1,-32767) [-32767|32766] "1/min"  INVCON5
 SG_ DesiredTorque5 : 42|11@1+ (1,-1023) [-1023|1022] "Nm"  INVCON5
 SG_ UdcSetP5 : 32|10@1+ (1,0) [0|1021] "V"  INVCON5
 SG_ Checksum_10C : 0|8@1+ (1,0) [0|255] "-"  INVCON5
 SG_ MessageCounter_10C : 8|4@1+ (1,0) [0|15] "-"  INVCON5
 SG_ StHvbMaiRly5 : 53|3@1+ (1,0) [0|7] "-"  INVCON5

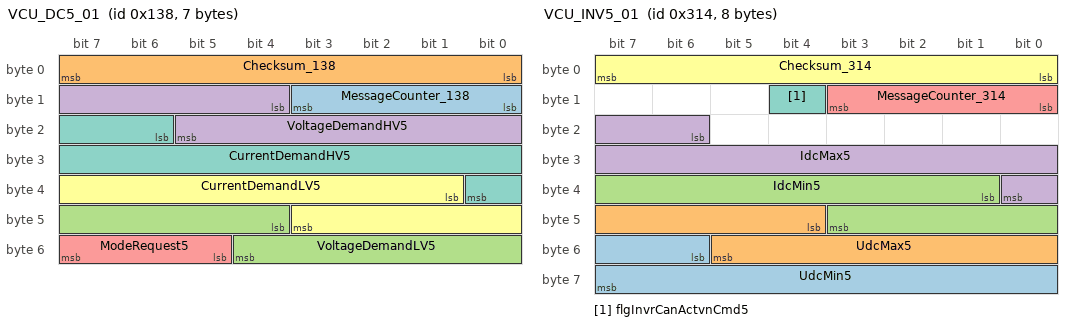
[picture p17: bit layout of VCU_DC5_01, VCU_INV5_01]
BO_ 312 VCU_DC5_01: 7 VCU
 SG_ MessageCounter_138 : 8|4@1+ (1,0) [0|15] "-"  INVCON5
 SG_ Checksum_138 : 0|8@1+ (1,0) [0|255] "-"  INVCON5
 SG_ VoltageDemandLV5 : 44|9@1+ (0.125,0) [0|63.875] "V"  INVCON5
 SG_ VoltageDemandHV5 : 12|10@1+ (1,0) [0|1021] "V"  INVCON5
 SG_ ModeRequest5 : 53|3@1+ (1,0) [0|7] "-"  INVCON5
 SG_ CurrentDemandLV5 : 33|11@1+ (1,-1023) [-1023|1022] "A"  INVCON5
 SG_ CurrentDemandHV5 : 22|11@1+ (0.0625,-64) [-64|63.8125] "A"  INVCON5

BO_ 788 VCU_INV5_01: 8 VCU
 SG_ UdcMin5 : 54|10@1+ (1,0) [0|1021] "V"  INVCON5
 SG_ UdcMax5 : 44|10@1+ (1,0) [0|1021] "V"  INVCON5
 SG_ IdcMin5 : 33|11@1+ (1,-1023) [-1023|1022] "A"  INVCON5
 SG_ IdcMax5 : 22|11@1+ (1,-1023) [-1023|1022] "A"  INVCON5
 SG_ MessageCounter_314 : 8|4@1+ (1,0) [0|15] "-"  INVCON5
 SG_ Checksum_314 : 0|8@1+ (1,0) [0|255] "-"  INVCON5
 SG_ flgInvrCanActvnCmd5 : 12|1@1+ (1,0) [0|1] "-"  INVCON5

BO_ 790 VCU_INV5_03: 8 VCU
 SG_ KI_Faktor5 : 49|15@1+ (0.0009765625,0) [0|31.9990234375] "-"  INVCON5
 SG_ MessageCounter_316 : 8|4@1+ (1,0) [0|15] "-"  INVCON5
 SG_ Checksum_316 : 0|8@1+ (1,0) [0|255] "-"  INVCON5
 SG_ MinTorqueLimit5 : 12|11@1+ (1,-1023) [-1023|1022] "Nm"  INVCON5
 SG_ MaxTorqueLimit5 : 38|11@1+ (1,-1023) [-1023|1022] "Nm"  INVCON5
 SG_ MaxTorqueGradient5 : 23|15@1+ (32,0) [0|1048480] "Nm/s"  INVCON5

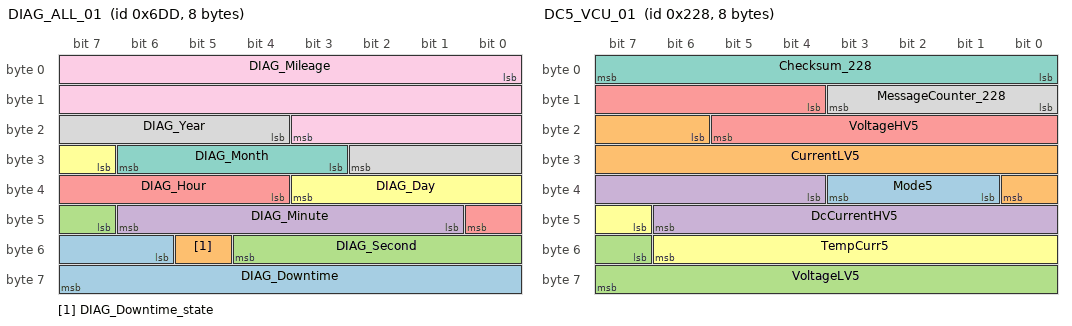
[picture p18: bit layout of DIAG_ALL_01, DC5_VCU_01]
BO_ 1757 DIAG_ALL_01: 8 VCU
 SG_ DIAG_Downtime : 54|10@1+ (32,0) [0|32736] "s"  INVCON0,INVCON1,INVCON2,INVCON3,INVCON4,INVCON5
 SG_ DIAG_Downtime_state : 53|1@1+ (1,0) [0|1] ""  INVCON0,INVCON1,INVCON2,INVCON3,INVCON4,INVCON5
 SG_ DIAG_Second : 47|6@1+ (1,0) [0|59] "s"  INVCON0,INVCON1,INVCON2,INVCON3,INVCON4,INVCON5
 SG_ DIAG_Minute : 41|6@1+ (1,0) [0|59] "min"  INVCON0,INVCON1,INVCON2,INVCON3,INVCON4,INVCON5
 SG_ DIAG_Hour : 36|5@1+ (1,0) [0|23] "h"  INVCON0,INVCON1,INVCON2,INVCON3,INVCON4,INVCON5
 SG_ DIAG_Day : 31|5@1+ (1,0) [1|31] "d"  INVCON0,INVCON1,INVCON2,INVCON3,INVCON4,INVCON5
 SG_ DIAG_Month : 27|4@1+ (1,0) [1|12] "m"  INVCON0,INVCON1,INVCON2,INVCON3,INVCON4,INVCON5
 SG_ DIAG_Year : 20|7@1+ (1,2000) [2000|2127] "y"  INVCON0,INVCON1,INVCON2,INVCON3,INVCON4,INVCON5
 SG_ DIAG_Mileage : 0|20@1+ (1,0) [0|1048575] "km"  INVCON0,INVCON1,INVCON2,INVCON3,INVCON4,INVCON5

BO_ 524 INV5_VCU_01: 7 INVCON5
 SG_ CurrentHV5 : 32|11@1+ (1,-1023) [-1023|1024] "A"  VCU
 SG_ OutputTorque5 : 43|11@1+ (1,-1023) [-1023|1024] "Nm"  VCU
 SG_ State5 : 12|4@1+ (1,0) [0|15] "-"  VCU
 SG_ Speed5 : 16|16@1+ (1,-32767) [-32767|32766] "1/min"  VCU
 SG_ Checksum_20C : 0|8@1+ (1,0) [0|255] "-"  VCU
 SG_ MessageCounter_20C : 8|4@1+ (1,0) [0|15] "-"  VCU

BO_ 536 INV5_VCU_02: 7 INVCON5
 SG_ dataInvrNr5 : 53|3@1+ (1,0) [0|5] ""  VCU
 SG_ MaxTorque5 : 12|11@1+ (1,-1023) [-1023|1024] "Nm"  VCU
 SG_ MinTorque5 : 23|11@1+ (1,-1023) [-1023|1024] "Nm"  VCU
 SG_ Checksum_218 : 0|8@1+ (1,0) [0|255] "-"  VCU
 SG_ MessageCounter_218 : 8|4@1+ (1,0) [0|15] "-"  VCU
 SG_ TrqCurrWoDstC5 : 34|11@1+ (1,-1023) [-1023|1024] "Nm"  VCU
 SG_ TempCurrCool5 : 45|8@1+ (1,-40) [-40|213] "°C"  VCU

BO_ 552 DC5_VCU_01: 8 INVCON5
 SG_ Mode5 : 33|3@1+ (1,0) [0|7] "-"  VCU
 SG_ CurrentLV5 : 22|11@1+ (1,-1023) [-1023|1024] "A"  VCU
 SG_ VoltageLV5 : 55|9@1+ (0.125,0) [0|63.875] "V"  VCU
 SG_ DcCurrentHV5 : 36|11@1+ (0.0625,-64) [-64|63.9375] "A"  VCU
 SG_ VoltageHV5 : 12|10@1+ (1,0) [0|1023] "V"  VCU
 SG_ TempCurr5 : 47|8@1+ (1,-40) [-40|213] "°C"  VCU
 SG_ Checksum_228 : 0|8@1+ (1,0) [0|255] "-"  VCU
 SG_ MessageCounter_228 : 8|4@1+ (1,0) [0|15] "-"  VCU

BO_ 1576 INV5_VCU_04: 6 INVCON5
 SG_ ElectricMachineTemperature5 : 16|8@1+ (1,-40) [-40|213] "°C"  VCU
 SG_ InverterTemperature5 : 24|8@1+ (1,-40) [-40|213] "°C"  VCU
 SG_ UT30Curr5 : 32|6@1+ (0.5,0) [0|31.5] "V"  VCU
 SG_ TempCurrRotor5 : 38|8@1+ (1,-40) [-40|213] "°C"  VCU
 SG_ Checksum_628 : 0|8@1+ (1,0) [0|255] "-"  VCU
 SG_ MessageCounter_628 : 8|4@1+ (1,0) [0|15] "-"  VCU

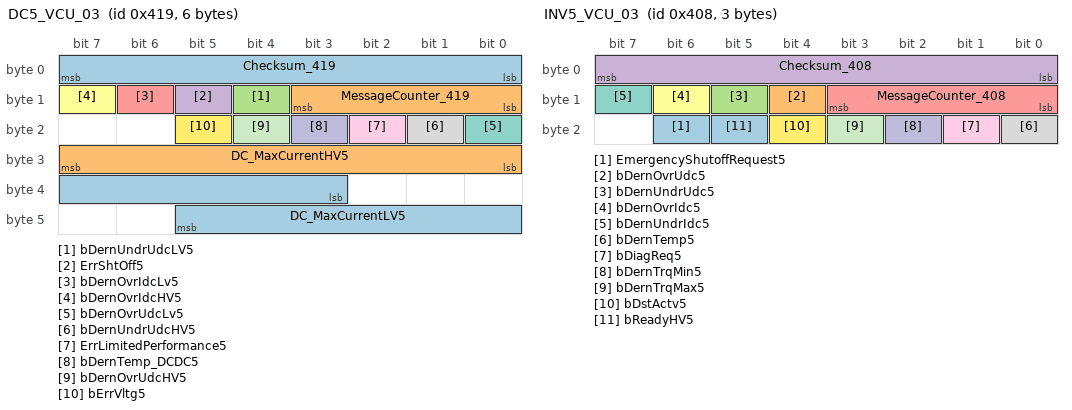
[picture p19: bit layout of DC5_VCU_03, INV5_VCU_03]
BO_ 1049 DC5_VCU_03: 6 INVCON5
 SG_ DC_MaxCurrentLV5 : 35|11@1+ (1,-1023) [-1023|1024] "A"  VCU
 SG_ DC_MaxCurrentHV5 : 24|8@1+ (0.25,0) [0|63.75] "A"  VCU
 SG_ bDernUndrUdcLV5 : 12|1@1+ (1,0) [0|1] "-"  VCU
 SG_ ErrShtOff5 : 13|1@1+ (1,0) [0|1] "-"  VCU
 SG_ bDernOvrIdcLv5 : 14|1@1+ (1,0) [0|1] "-"  VCU
 SG_ bDernOvrIdcHV5 : 15|1@1+ (1,0) [0|1] "-"  VCU
 SG_ bDernOvrUdcLv5 : 16|1@1+ (1,0) [0|1] "-"  VCU
 SG_ bDernUndrUdcHV5 : 17|1@1+ (1,0) [0|1] "-"  VCU
 SG_ ErrLimitedPerformance5 : 18|1@1+ (1,0) [0|1] "-"  VCU
 SG_ bDernTemp_DCDC5 : 19|1@1+ (1,0) [0|1] "-"  VCU
 SG_ bDernOvrUdcHV5 : 20|1@1+ (1,0) [0|1] "-"  VCU
 SG_ bErrVltg5 : 21|1@1+ (1,0) [0|1] "-"  VCU
 SG_ Checksum_419 : 0|8@1+ (1,0) [0|255] "-"  VCU
 SG_ MessageCounter_419 : 8|4@1+ (1,0) [0|15] "-"  VCU

BO_ 1032 INV5_VCU_03: 3 INVCON5
 SG_ EmergencyShutoffRequest5 : 22|1@1+ (1,0) [0|1] "-"  VCU
 SG_ bDernOvrUdc5 : 12|1@1+ (1,0) [0|1] "-"  VCU
 SG_ bDernUndrUdc5 : 13|1@1+ (1,0) [0|1] "-"  VCU
 SG_ Checksum_408 : 0|8@1+ (1,0) [0|255] "-"  VCU
 SG_ MessageCounter_408 : 8|4@1+ (1,0) [0|15] "-"  VCU
 SG_ bDernOvrIdc5 : 14|1@1+ (1,0) [0|1] "-"  VCU
 SG_ bDernUndrIdc5 : 15|1@1+ (1,0) [0|1] "-"  VCU
 SG_ bDernTemp5 : 16|1@1+ (1,0) [0|1] "-"  VCU
 SG_ bDiagReq5 : 17|1@1+ (1,0) [0|1] "-"  VCU
 SG_ bDernTrqMin5 : 18|1@1+ (1,0) [0|1] "-"  VCU
 SG_ bDernTrqMax5 : 19|1@1+ (1,0) [0|1] "-"  VCU
 SG_ bDstActv5 : 20|1@1+ (1,0) [0|1] "-"  VCU
 SG_ bReadyHV5 : 21|1@1+ (1,0) [0|1] "-"  VCU

CM_ SG_ 292 SurgeDamperTreshold5 "Threshold torque for damping control";
CM_ SG_ 292 SurgeDamperState5 "Requested surge damper state";
CM_ SG_ 292 SurgeDamperMaxTorque5 "Maximum torque active damping control";
CM_ SG_ 292 SurgeDamperFactor5 "Calculation factor for surge damper";
CM_ SG_ 291 SurgeDamperTreshold4 "Threshold torque for damping control";
CM_ SG_ 291 SurgeDamperState4 "Requested surge damper state";
CM_ SG_ 291 SurgeDamperMaxTorque4 "Maximum torque active damping control";
CM_ SG_ 291 SurgeDamperFactor4 "Calculation factor for surge damper";
CM_ SG_ 290 SurgeDamperTreshold3 "Threshold torque for damping control";
CM_ SG_ 290 SurgeDamperState3 "Requested surge damper state";
CM_ SG_ 290 SurgeDamperMaxTorque3 "Maximum torque active damping control";
CM_ SG_ 290 SurgeDamperFactor3 "Calculation factor for surge damper";
CM_ SG_ 289 SurgeDamperTreshold2 "Threshold torque for damping control";
CM_ SG_ 289 SurgeDamperState2 "Requested surge damper state";
CM_ SG_ 289 SurgeDamperMaxTorque2 "Maximum torque active damping control";
CM_ SG_ 289 SurgeDamperFactor2 "Calculation factor for surge damper";
CM_ SG_ 288 SurgeDamperTreshold1 "Threshold torque for damping control";
CM_ SG_ 288 SurgeDamperState1 "Requested surge damper state";
CM_ SG_ 288 SurgeDamperMaxTorque1 "Maximum torque active damping control";
CM_ SG_ 288 SurgeDamperFactor1 "Calculation factor for surge damper";
CM_ SG_ 1663 INV0_FailCode4 "# bit0,1:
00 => fault since last clear
01 => fault active
10, 11 => not used at the moment
# bit2-13: FaultCode-ID, as by DFES_DTCM
# bit14,15:
00 => fault-id contains a DTC
01 => fault-id contains DFC-id
10,11 => not used at the moment";
CM_ SG_ 1663 INV0_FailCode3 "# bit0,1:
00 => fault since last clear
01 => fault active
10, 11 => not used at the moment
# bit2-13: FaultCode-ID, as by DFES_DTCM
# bit14,15:
00 => fault-id contains a DTC
01 => fault-id contains DFC-id
10,11 => not used at the moment";
CM_ SG_ 1663 INV0_FailCode2 "# bit0,1:
00 => fault since last clear
01 => fault active
10, 11 => not used at the moment
# bit2-13: FaultCode-ID, as by DFES_DTCM
# bit14,15:
00 => fault-id contains a DTC
01 => fault-id contains DFC-id
10,11 => not used at the moment";
CM_ SG_ 1663 INV0_FailCode1 "# bit0,1:
00 => fault since last clear
01 => fault active
10, 11 => not used at the moment
# bit2-13: FaultCode-ID, as by DFES_DTCM
# bit14,15:
00 => fault-id contains a DTC
01 => fault-id contains DFC-id
10,11 => not used at the moment";
CM_ SG_ 1668 INV5_FailCode4 "# bit0,1:
00 => fault since last clear
01 => fault active
10, 11 => not used at the moment
# bit2-13: FaultCode-ID, as by DFES_DTCM
# bit14,15:
00 => fault-id contains a DTC
01 => fault-id contains DFC-id
10,11 => not used at the moment";
CM_ SG_ 1668 INV5_FailCode3 "# bit0,1:
00 => fault since last clear
01 => fault active
10, 11 => not used at the moment
# bit2-13: FaultCode-ID, as by DFES_DTCM
# bit14,15:
00 => fault-id contains a DTC
01 => fault-id contains DFC-id
10,11 => not used at the moment";
CM_ SG_ 1668 INV5_FailCode2 "# bit0,1:
00 => fault since last clear
01 => fault active
10, 11 => not used at the moment
# bit2-13: FaultCode-ID, as by DFES_DTCM
# bit14,15:
00 => fault-id contains a DTC
01 => fault-id contains DFC-id
10,11 => not used at the moment";
CM_ SG_ 1668 INV5_FailCode1 "# bit0,1:
00 => fault since last clear
01 => fault active
10, 11 => not used at the moment
# bit2-13: FaultCode-ID, as by DFES_DTCM
# bit14,15:
00 => fault-id contains a DTC
01 => fault-id contains DFC-id
10,11 => not used at the moment";
CM_ SG_ 1667 INV4_FailCode4 "# bit0,1:
00 => fault since last clear
01 => fault active
10, 11 => not used at the moment
# bit2-13: FaultCode-ID, as by DFES_DTCM
# bit14,15:
00 => fault-id contains a DTC
01 => fault-id contains DFC-id
10,11 => not used at the moment";
CM_ SG_ 1667 INV4_FailCode3 "# bit0,1:
00 => fault since last clear
01 => fault active
10, 11 => not used at the moment
# bit2-13: FaultCode-ID, as by DFES_DTCM
# bit14,15:
00 => fault-id contains a DTC
01 => fault-id contains DFC-id
10,11 => not used at the moment";
CM_ SG_ 1667 INV4_FailCode2 "# bit0,1:
00 => fault since last clear
01 => fault active
10, 11 => not used at the moment
# bit2-13: FaultCode-ID, as by DFES_DTCM
# bit14,15:
00 => fault-id contains a DTC
01 => fault-id contains DFC-id
10,11 => not used at the moment";
CM_ SG_ 1667 INV4_FailCode1 "# bit0,1:
00 => fault since last clear
01 => fault active
10, 11 => not used at the moment
# bit2-13: FaultCode-ID, as by DFES_DTCM
# bit14,15:
00 => fault-id contains a DTC
01 => fault-id contains DFC-id
10,11 => not used at the moment";
CM_ SG_ 1666 INV3_FailCode4 "# bit0,1:
00 => fault since last clear
01 => fault active
10, 11 => not used at the moment
# bit2-13: FaultCode-ID, as by DFES_DTCM
# bit14,15:
00 => fault-id contains a DTC
01 => fault-id contains DFC-id
10,11 => not used at the moment";
CM_ SG_ 1666 INV3_FailCode3 "# bit0,1:
00 => fault since last clear
01 => fault active
10, 11 => not used at the moment
# bit2-13: FaultCode-ID, as by DFES_DTCM
# bit14,15:
00 => fault-id contains a DTC
01 => fault-id contains DFC-id
10,11 => not used at the moment";
CM_ SG_ 1666 INV3_FailCode2 "# bit0,1:
00 => fault since last clear
01 => fault active
10, 11 => not used at the moment
# bit2-13: FaultCode-ID, as by DFES_DTCM
# bit14,15:
00 => fault-id contains a DTC
01 => fault-id contains DFC-id
10,11 => not used at the moment";
CM_ SG_ 1666 INV3_FailCode1 "# bit0,1:
00 => fault since last clear
01 => fault active
10, 11 => not used at the moment
# bit2-13: FaultCode-ID, as by DFES_DTCM
# bit14,15:
00 => fault-id contains a DTC
01 => fault-id contains DFC-id
10,11 => not used at the moment";
CM_ SG_ 1665 INV2_FailCode4 "# bit0,1:
00 => fault since last clear
01 => fault active
10, 11 => not used at the moment
# bit2-13: FaultCode-ID, as by DFES_DTCM
# bit14,15:
00 => fault-id contains a DTC
01 => fault-id contains DFC-id
10,11 => not used at the moment";
CM_ SG_ 1665 INV2_FailCode3 "# bit0,1:
00 => fault since last clear
01 => fault active
10, 11 => not used at the moment
# bit2-13: FaultCode-ID, as by DFES_DTCM
# bit14,15:
00 => fault-id contains a DTC
01 => fault-id contains DFC-id
10,11 => not used at the moment";
CM_ SG_ 1665 INV2_FailCode2 "# bit0,1:
00 => fault since last clear
01 => fault active
10, 11 => not used at the moment
# bit2-13: FaultCode-ID, as by DFES_DTCM
# bit14,15:
00 => fault-id contains a DTC
01 => fault-id contains DFC-id
10,11 => not used at the moment";
CM_ SG_ 1665 INV2_FailCode1 "# bit0,1:
00 => fault since last clear
01 => fault active
10, 11 => not used at the moment
# bit2-13: FaultCode-ID, as by DFES_DTCM
# bit14,15:
00 => fault-id contains a DTC
01 => fault-id contains DFC-id
10,11 => not used at the moment";
CM_ SG_ 1664 INV1_FailCode4 "# bit0,1:
00 => fault since last clear
01 => fault active
10, 11 => not used at the moment
# bit2-13: FaultCode-ID, as by DFES_DTCM
# bit14,15:
00 => fault-id contains a DTC
01 => fault-id contains DFC-id
10,11 => not used at the moment";
CM_ SG_ 1664 INV1_FailCode3 "# bit0,1:
00 => fault since last clear
01 => fault active
10, 11 => not used at the moment
# bit2-13: FaultCode-ID, as by DFES_DTCM
# bit14,15:
00 => fault-id contains a DTC
01 => fault-id contains DFC-id
10,11 => not used at the moment";
CM_ SG_ 1664 INV1_FailCode2 "# bit0,1:
00 => fault since last clear
01 => fault active
10, 11 => not used at the moment
# bit2-13: FaultCode-ID, as by DFES_DTCM
# bit14,15:
00 => fault-id contains a DTC
01 => fault-id contains DFC-id
10,11 => not used at the moment";
CM_ SG_ 1664 INV1_FailCode1 "# bit0,1:
00 => fault since last clear
01 => fault active
10, 11 => not used at the moment
# bit2-13: FaultCode-ID, as by DFES_DTCM
# bit14,15:
00 => fault-id contains a DTC
01 => fault-id contains DFC-id
10,11 => not used at the moment";
CM_ SG_ 789 Checksum_315 "Checksum signal for frame";
CM_ SG_ 789 MessageCounter_315 "Message counter signal for frame";
CM_ SG_ 789 MaxTorqueEngineSpeed5 "Maximum allowed torque for speed controller";
CM_ SG_ 789 MinTorqueEngineSpeed5 "Minimum allowed torque for speed controller";
CM_ SG_ 789 MaxDeltaSpeed5 "Maximum allowed speed difference";
CM_ SG_ 789 FactorPContributionSmall5 "Factor to scale contributon P Controller, small signal gain";
CM_ SG_ 789 FactorPContributionLarge5 "Factor to scale contributon P Controller, large signal gain";
CM_ SG_ 785 Checksum_311 "Checksum signal for frame";
CM_ SG_ 785 MessageCounter_311 "Message counter signal for frame";
CM_ SG_ 785 MaxTorqueEngineSpeed4 "Maximum allowed torque for speed controller";
CM_ SG_ 785 MinTorqueEngineSpeed4 "Minimum allowed torque for speed controller";
CM_ SG_ 785 MaxDeltaSpeed4 "Maximum allowed speed difference";
CM_ SG_ 785 FactorPContributionSmall4 "Factor to scale contributon P Controller, small signal gain";
CM_ SG_ 785 FactorPContributionLarge4 "Factor to scale contributon P Controller, large signal gain";
CM_ SG_ 781 Checksum_30D "Checksum signal for frame";
CM_ SG_ 781 MessageCounter_30D "Message counter signal for frame";
CM_ SG_ 781 MaxTorqueEngineSpeed3 "Maximum allowed torque for speed controller";
CM_ SG_ 781 MinTorqueEngineSpeed3 "Minimum allowed torque for speed controller";
CM_ SG_ 781 MaxDeltaSpeed3 "Maximum allowed speed difference";
CM_ SG_ 781 FactorPContributionSmall3 "Factor to scale contributon P Controller, small signal gain";
CM_ SG_ 781 FactorPContributionLarge3 "Factor to scale contributon P Controller, large signal gain";
CM_ SG_ 777 Checksum_309 "Checksum signal for frame";
CM_ SG_ 777 MessageCounter_309 "Message counter signal for frame";
CM_ SG_ 777 MaxTorqueEngineSpeed2 "Maximum allowed torque for speed controller";
CM_ SG_ 777 MinTorqueEngineSpeed2 "Minimum allowed torque for speed controller";
CM_ SG_ 777 MaxDeltaSpeed2 "Maximum allowed speed difference";
CM_ SG_ 777 FactorPContributionSmall2 "Factor to scale contributon P Controller, small signal gain";
CM_ SG_ 777 FactorPContributionLarge2 "Factor to scale contributon P Controller, large signal gain";
CM_ SG_ 773 Checksum_305 "Checksum signal for frame";
CM_ SG_ 773 MessageCounter_305 "Message counter signal for frame";
CM_ SG_ 773 MaxTorqueEngineSpeed1 "Maximum allowed torque for speed controller";
CM_ SG_ 773 MinTorqueEngineSpeed1 "Minimum allowed torque for speed controller";
CM_ SG_ 773 MaxDeltaSpeed1 "Maximum allowed speed difference";
CM_ SG_ 773 FactorPContributionSmall1 "Factor to scale contributon P Controller, small signal gain";
CM_ SG_ 773 FactorPContributionLarge1 "Factor to scale contributon P Controller, large signal gain";
CM_ SG_ 260 RequestedState1 "Request to the electric machine";
CM_ SG_ 260 DesiredSpeed1 "Desired speed electric machine";
CM_ SG_ 260 DesiredTorque1 "Desired torque electric machine";
CM_ SG_ 260 UdcSetP1 "Setpoint voltage E-Machine";
CM_ SG_ 260 Checksum_104 "Checksum signal for frame";
CM_ SG_ 260 MessageCounter_104 "Message counter signal for frame";
CM_ SG_ 260 StHvbMaiRly1 "State1 of main relay, alternative signal to ContactorState";
CM_ SG_ 304 MessageCounter_130 "Message counter signal for frame";
CM_ SG_ 304 Checksum_130 "Checksum signal for frame";
CM_ SG_ 304 VoltageDemandLV1 "Desired voltage of the DCDC converter LV side";
CM_ SG_ 304 VoltageDemandHV1 "Desired voltage of the DCDC converter HV side";
CM_ SG_ 304 ModeRequest1 "Requested State1 of the DCDC converter";
CM_ SG_ 304 CurrentDemandLV1 "Demanded current on LV side";
CM_ SG_ 304 CurrentDemandHV1 "Demanded current of DCDC converter HV side";
CM_ SG_ 772 UdcMin1 "min voltage HV";
CM_ SG_ 772 UdcMax1 "max voltage HV";
CM_ SG_ 772 IdcMin1 "max current for regenerative current";
CM_ SG_ 772 IdcMax1 "max current for motor torque";
CM_ SG_ 772 MessageCounter_304 "Message counter signal for frame";
CM_ SG_ 772 Checksum_304 "Checksum signal for frame";
CM_ SG_ 772 flgInvrCanActvnCmd1 "Activates CAN activity of inverter1";
CM_ SG_ 774 KI_Faktor1 "Integral gain Ki";
CM_ SG_ 774 MessageCounter_306 "Message counter signal for frame";
CM_ SG_ 774 Checksum_306 "Checksum signal for frame";
CM_ SG_ 774 MinTorqueLimit1 "Lower limit output torque of electric machine";
CM_ SG_ 774 MaxTorqueLimit1 "Upper limit output torque of electric machine";
CM_ SG_ 774 MaxTorqueGradient1 "Maximum change rate of the torque demand";
CM_ SG_ 516 CurrentHV1 "HV current at the DC/AC converter";
CM_ SG_ 516 OutputTorque1 "output torque which is currently provided by the electric machine";
CM_ SG_ 516 State1 "Information of the  State1 of the electric machine";
CM_ SG_ 516 Speed1 "rotational speed of electric machine";
CM_ SG_ 516 Checksum_204 "Checksum signal for frame";
CM_ SG_ 516 MessageCounter_204 "Message counter signal for frame";
CM_ SG_ 528 dataInvrNr1 "Inverter number which has been configured via UDS/BODAS";
CM_ SG_ 528 MaxTorque1 "Electric machine torque value";
CM_ SG_ 528 MinTorque1 "Total brake torque minimum";
CM_ SG_ 528 Checksum_210 "Checksum signal for frame";
CM_ SG_ 528 MessageCounter_210 "Message counter signal for frame";
CM_ SG_ 528 TrqCurrWoDstC1 "e-machine torque without part of damping control";
CM_ SG_ 528 TempCurrCool1 "temperature of Inverter1 cooling water";
CM_ SG_ 544 Mode1 "State1 DC/DC converter";
CM_ SG_ 544 CurrentLV1 "current on low voltage side";
CM_ SG_ 544 VoltageLV1 "voltage on low voltage side";
CM_ SG_ 544 DcCurrentHV1 "current of the DC/DC converter at high voltage side";
CM_ SG_ 544 VoltageHV1 "voltage at high voltage side";
CM_ SG_ 544 TempCurr1 " temperature of DCDC";
CM_ SG_ 544 Checksum_220 "Checksum signal for frame";
CM_ SG_ 544 MessageCounter_220 "Message counter signal for frame";
CM_ SG_ 1568 ElectricMachineTemperature1 "Current temperature of electric machine";
CM_ SG_ 1568 InverterTemperature1 "Current temperature of Inverter1";
CM_ SG_ 1568 UT30Curr1 "Current UT30 Voltage at Inverter1";
CM_ SG_ 1568 TempCurrRotor1 "Temperature of rotor";
CM_ SG_ 1568 Checksum_620 "Checksum signal for frame";
CM_ SG_ 1568 MessageCounter_620 "Message counter signal for frame";
CM_ SG_ 1041 DC_MaxCurrentLV1 "Maximal allowed current at low voltage side";
CM_ SG_ 1041 DC_MaxCurrentHV1 "Maximal allowed current at high voltage side";
CM_ SG_ 1041 bDernUndrUdcLV1 "Derating because of Low Voltage at LV";
CM_ SG_ 1041 ErrShtOff1 "Derating because of DCDC shutdown";
CM_ SG_ 1041 bDernOvrIdcLv1 "Derating because of high current at LV";
CM_ SG_ 1041 bDernOvrIdcHV1 "Derating because of high current at HV";
CM_ SG_ 1041 bDernOvrUdcLv1 "Derating because of error high voltage at LV";
CM_ SG_ 1041 bDernUndrUdcHV1 "Derating because of error low voltage at HV";
CM_ SG_ 1041 ErrLimitedPerformance1 "limited performance of DCDC";
CM_ SG_ 1041 bDernTemp_DCDC1 "Derating because of overtemperature DCDC";
CM_ SG_ 1041 bDernOvrUdcHV1 "Derating because of high voltage at HV";
CM_ SG_ 1041 bErrVltg1 "shutdown because of Over/Undervoltage at I/O side";
CM_ SG_ 1041 Checksum_411 "Checksum signal for frame";
CM_ SG_ 1041 MessageCounter_411 "Message counter signal for frame";
CM_ SG_ 1024 EmergencyShutoffRequest1 "Emergency shut off requested by inverter ECU";
CM_ SG_ 1024 bDernOvrUdc1 "Derating because of overvoltage HV";
CM_ SG_ 1024 bDernUndrUdc1 "Derating because of undervoltage HV";
CM_ SG_ 1024 Checksum_400 "Checksum signal for frame";
CM_ SG_ 1024 MessageCounter_400 "Message counter signal for frame";
CM_ SG_ 1024 bDernOvrIdc1 "Derating because of overcurrent Inverter1 E-machine";
CM_ SG_ 1024 bDernUndrIdc1 "Derating because of overcurrent regenerative Inverter1 E-machine";
CM_ SG_ 1024 bDernTemp1 "Derating because of overtemperature E-machine";
CM_ SG_ 1024 bDiagReq1 "Diag request for e-machine Inverter1 Calibration";
CM_ SG_ 1024 bDernTrqMin1 "Derating because of max torque regenerative";
CM_ SG_ 1024 bDernTrqMax1 "Derating because of max torque";
CM_ SG_ 1024 bDstActv1 "Surge Damping active";
CM_ SG_ 1024 bReadyHV1 "HV voltage operational";
CM_ SG_ 110 bErrEmergencyDischargeReq "Bit-Info for emergency discharge request";
CM_ SG_ 110 MessageCounter_6E "Message counter signal for frame";
CM_ SG_ 110 Checksum_6E "Checksum signal for frame";
CM_ SG_ 110 ContactorState "State of the HV contactors";
CM_ SG_ 110 Current "battery current charging / discharging";
CM_ SG_ 110 Voltage "voltage of the electric energy storage";
CM_ SG_ 262 RequestedState2 "Request to the electric machine";
CM_ SG_ 262 DesiredSpeed2 "Desired speed electric machine";
CM_ SG_ 262 DesiredTorque2 "Desired torque electric machine";
CM_ SG_ 262 UdcSetP2 "Setpoint voltage E-Machine";
CM_ SG_ 262 Checksum_106 "Checksum signal for frame";
CM_ SG_ 262 MessageCounter_106 "Message counter signal for frame";
CM_ SG_ 262 StHvbMaiRly2 "State2 of main relay, alternative signal to ContactorState";
CM_ SG_ 306 MessageCounter_132 "Message counter signal for frame";
CM_ SG_ 306 Checksum_132 "Checksum signal for frame";
CM_ SG_ 306 VoltageDemandLV2 "Desired voltage of the DCDC converter LV side";
CM_ SG_ 306 VoltageDemandHV2 "Desired voltage of the DCDC converter HV side";
CM_ SG_ 306 ModeRequest2 "Requested State2 of the DCDC converter";
CM_ SG_ 306 CurrentDemandLV2 "Demanded current on LV side";
CM_ SG_ 306 CurrentDemandHV2 "Demanded current of DCDC converter HV side";
CM_ SG_ 776 UdcMin2 "min voltage HV";
CM_ SG_ 776 UdcMax2 "max voltage HV";
CM_ SG_ 776 IdcMin2 "max current for regenerative current";
CM_ SG_ 776 IdcMax2 "max current for motor torque";
CM_ SG_ 776 MessageCounter_308 "Message counter signal for frame";
CM_ SG_ 776 Checksum_308 "Checksum signal for frame";
CM_ SG_ 776 flgInvrCanActvnCmd2 "Activates CAN activity of inverter2";
CM_ SG_ 778 KI_Faktor2 "Integral gain Ki";
CM_ SG_ 778 MessageCounter_30A "Message counter signal for frame";
CM_ SG_ 778 Checksum_30A "Checksum signal for frame";
CM_ SG_ 778 MinTorqueLimit2 "Lower limit output torque of electric machine";
CM_ SG_ 778 MaxTorqueLimit2 "Upper limit output torque of electric machine";
CM_ SG_ 778 MaxTorqueGradient2 "Maximum change rate of the torque demand";
CM_ SG_ 518 CurrentHV2 "HV current at the DC/AC converter";
CM_ SG_ 518 OutputTorque2 "output torque which is currently provided by the electric machine";
CM_ SG_ 518 State2 "Information of the  State2 of the electric machine";
CM_ SG_ 518 Speed2 "rotational speed of electric machine";
CM_ SG_ 518 Checksum_206 "Checksum signal for frame";
CM_ SG_ 518 MessageCounter_206 "Message counter signal for frame";
CM_ SG_ 530 dataInvrNr2 "Inverter number which has been configured via UDS/BODAS";
CM_ SG_ 530 MaxTorque2 "Electric machine torque value";
CM_ SG_ 530 MinTorque2 "Total brake torque minimum";
CM_ SG_ 530 Checksum_212 "Checksum signal for frame";
CM_ SG_ 530 MessageCounter_212 "Message counter signal for frame";
CM_ SG_ 530 TrqCurrWoDstC2 "e-machine torque without part of damping control";
CM_ SG_ 530 TempCurrCool2 "temperature of Inverter2 cooling water";
CM_ SG_ 546 Mode2 "State2 DC/DC converter";
CM_ SG_ 546 CurrentLV2 "current on low voltage side";
CM_ SG_ 546 VoltageLV2 "voltage on low voltage side";
CM_ SG_ 546 DcCurrentHV2 "current of the DC/DC converter at high voltage side";
CM_ SG_ 546 VoltageHV2 "voltage at high voltage side";
CM_ SG_ 546 TempCurr2 " temperature of DCDC";
CM_ SG_ 546 Checksum_222 "Checksum signal for frame";
CM_ SG_ 546 MessageCounter_222 "Message counter signal for frame";
CM_ SG_ 1570 ElectricMachineTemperature2 "Current temperature of electric machine";
CM_ SG_ 1570 InverterTemperature2 "Current temperature of Inverter2";
CM_ SG_ 1570 UT30Curr2 "Current UT30 Voltage at Inverter2";
CM_ SG_ 1570 TempCurrRotor2 "Temperature of rotor";
CM_ SG_ 1570 Checksum_622 "Checksum signal for frame";
CM_ SG_ 1570 MessageCounter_622 "Message counter signal for frame";
CM_ SG_ 1043 DC_MaxCurrentLV2 "Maximal allowed current at low voltage side";
CM_ SG_ 1043 DC_MaxCurrentHV2 "Maximal allowed current at high voltage side";
CM_ SG_ 1043 bDernUndrUdcLV2 "Derating because of Low Voltage at LV";
CM_ SG_ 1043 ErrShtOff2 "Derating because of DCDC shutdown";
CM_ SG_ 1043 bDernOvrIdcLv2 "Derating because of high current at LV";
CM_ SG_ 1043 bDernOvrIdcHV2 "Derating because of high current at HV";
CM_ SG_ 1043 bDernOvrUdcLv2 "Derating because of error high voltage at LV";
CM_ SG_ 1043 bDernUndrUdcHV2 "Derating because of error low voltage at HV";
CM_ SG_ 1043 ErrLimitedPerformance2 "limited performance of DCDC";
CM_ SG_ 1043 bDernTemp_DCDC2 "Derating because of overtemperature DCDC";
CM_ SG_ 1043 bDernOvrUdcHV2 "Derating because of high voltage at HV";
CM_ SG_ 1043 bErrVltg2 "shutdown because of Over/Undervoltage at I/O side";
CM_ SG_ 1043 Checksum_413 "Checksum signal for frame";
CM_ SG_ 1043 MessageCounter_413 "Message counter signal for frame";
CM_ SG_ 1026 EmergencyShutoffRequest2 "Emergency shut off requested by inverter ECU";
CM_ SG_ 1026 bDernOvrUdc2 "Derating because of overvoltage HV";
CM_ SG_ 1026 bDernUndrUdc2 "Derating because of undervoltage HV";
CM_ SG_ 1026 Checksum_402 "Checksum signal for frame";
CM_ SG_ 1026 MessageCounter_402 "Message counter signal for frame";
CM_ SG_ 1026 bDernOvrIdc2 "Derating because of overcurrent Inverter2 E-machine";
CM_ SG_ 1026 bDernUndrIdc2 "Derating because of overcurrent regenerative Inverter2 E-machine";
CM_ SG_ 1026 bDernTemp2 "Derating because of overtemperature E-machine";
CM_ SG_ 1026 bDiagReq2 "Diag request for e-machine Inverter2 Calibration";
CM_ SG_ 1026 bDernTrqMin2 "Derating because of max torque regenerative";
CM_ SG_ 1026 bDernTrqMax2 "Derating because of max torque";
CM_ SG_ 1026 bDstActv2 "Surge Damping active";
CM_ SG_ 1026 bReadyHV2 "HV voltage operational";
CM_ SG_ 264 RequestedState3 "Request to the electric machine";
CM_ SG_ 264 DesiredSpeed3 "Desired speed electric machine";
CM_ SG_ 264 DesiredTorque3 "Desired torque electric machine";
CM_ SG_ 264 UdcSetP3 "Setpoint voltage E-Machine";
CM_ SG_ 264 Checksum_108 "Checksum signal for frame";
CM_ SG_ 264 MessageCounter_108 "Message counter signal for frame";
CM_ SG_ 264 StHvbMaiRly3 "State3 of main relay, alternative signal to ContactorState";
CM_ SG_ 308 MessageCounter_134 "Message counter signal for frame";
CM_ SG_ 308 Checksum_134 "Checksum signal for frame";
CM_ SG_ 308 VoltageDemandLV3 "Desired voltage of the DCDC converter LV side";
CM_ SG_ 308 VoltageDemandHV3 "Desired voltage of the DCDC converter HV side";
CM_ SG_ 308 ModeRequest3 "Requested State3 of the DCDC converter";
CM_ SG_ 308 CurrentDemandLV3 "Demanded current on LV side";
CM_ SG_ 308 CurrentDemandHV3 "Demanded current of DCDC converter HV side";
CM_ SG_ 780 UdcMin3 "min voltage HV";
CM_ SG_ 780 UdcMax3 "max voltage HV";
CM_ SG_ 780 IdcMin3 "max current for regenerative current";
CM_ SG_ 780 IdcMax3 "max current for motor torque";
CM_ SG_ 780 MessageCounter_30C "Message counter signal for frame";
CM_ SG_ 780 Checksum_30C "Checksum signal for frame";
CM_ SG_ 780 flgInvrCanActvnCmd3 "Activates CAN activity of inverter3";
CM_ SG_ 782 KI_Faktor3 "Integral gain Ki";
CM_ SG_ 782 MessageCounter_30E "Message counter signal for frame";
CM_ SG_ 782 Checksum_30E "Checksum signal for frame";
CM_ SG_ 782 MinTorqueLimit3 "Lower limit output torque of electric machine";
CM_ SG_ 782 MaxTorqueLimit3 "Upper limit output torque of electric machine";
CM_ SG_ 782 MaxTorqueGradient3 "Maximum change rate of the torque demand";
CM_ SG_ 520 CurrentHV3 "HV current at the DC/AC converter";
CM_ SG_ 520 OutputTorque3 "output torque which is currently provided by the electric machine";
CM_ SG_ 520 State3 "Information of the  State3 of the electric machine";
CM_ SG_ 520 Speed3 "rotational speed of electric machine";
CM_ SG_ 520 Checksum_208 "Checksum signal for frame";
CM_ SG_ 520 MessageCounter_208 "Message counter signal for frame";
CM_ SG_ 532 dataInvrNr3 "Inverter number which has been configured via UDS/BODAS";
CM_ SG_ 532 MaxTorque3 "Electric machine torque value";
CM_ SG_ 532 MinTorque3 "Total brake torque minimum";
CM_ SG_ 532 Checksum_214 "Checksum signal for frame";
CM_ SG_ 532 MessageCounter_214 "Message counter signal for frame";
CM_ SG_ 532 TrqCurrWoDstC3 "e-machine torque without part of damping control";
CM_ SG_ 532 TempCurrCool3 "temperature of Inverter3 cooling water";
CM_ SG_ 548 Mode3 "State3 DC/DC converter";
CM_ SG_ 548 CurrentLV3 "current on low voltage side";
CM_ SG_ 548 VoltageLV3 "voltage on low voltage side";
CM_ SG_ 548 DcCurrentHV3 "current of the DC/DC converter at high voltage side";
CM_ SG_ 548 VoltageHV3 "voltage at high voltage side";
CM_ SG_ 548 TempCurr3 " temperature of DCDC";
CM_ SG_ 548 Checksum_224 "Checksum signal for frame";
CM_ SG_ 548 MessageCounter_224 "Message counter signal for frame";
CM_ SG_ 1572 ElectricMachineTemperature3 "Current temperature of electric machine";
CM_ SG_ 1572 InverterTemperature3 "Current temperature of Inverter3";
CM_ SG_ 1572 UT30Curr3 "Current UT30 Voltage at Inverter3";
CM_ SG_ 1572 TempCurrRotor3 "Temperature of rotor";
CM_ SG_ 1572 Checksum_624 "Checksum signal for frame";
CM_ SG_ 1572 MessageCounter_624 "Message counter signal for frame";
CM_ SG_ 1045 DC_MaxCurrentLV3 "Maximal allowed current at low voltage side";
CM_ SG_ 1045 DC_MaxCurrentHV3 "Maximal allowed current at high voltage side";
CM_ SG_ 1045 bDernUndrUdcLV3 "Derating because of Low Voltage at LV";
CM_ SG_ 1045 ErrShtOff3 "Derating because of DCDC shutdown";
CM_ SG_ 1045 bDernOvrIdcLv3 "Derating because of high current at LV";
CM_ SG_ 1045 bDernOvrIdcHV3 "Derating because of high current at HV";
CM_ SG_ 1045 bDernOvrUdcLv3 "Derating because of error high voltage at LV";
CM_ SG_ 1045 bDernUndrUdcHV3 "Derating because of error low voltage at HV";
CM_ SG_ 1045 ErrLimitedPerformance3 "limited performance of DCDC";
CM_ SG_ 1045 bDernTemp_DCDC3 "Derating because of overtemperature DCDC";
CM_ SG_ 1045 bDernOvrUdcHV3 "Derating because of high voltage at HV";
CM_ SG_ 1045 bErrVltg3 "shutdown because of Over/Undervoltage at I/O side";
CM_ SG_ 1045 Checksum_415 "Checksum signal for frame";
CM_ SG_ 1045 MessageCounter_415 "Message counter signal for frame";
CM_ SG_ 1028 EmergencyShutoffRequest3 "Emergency shut off requested by inverter ECU";
CM_ SG_ 1028 bDernOvrUdc3 "Derating because of overvoltage HV";
CM_ SG_ 1028 bDernUndrUdc3 "Derating because of undervoltage HV";
CM_ SG_ 1028 Checksum_404 "Checksum signal for frame";
CM_ SG_ 1028 MessageCounter_404 "Message counter signal for frame";
CM_ SG_ 1028 bDernOvrIdc3 "Derating because of overcurrent Inverter3 E-machine";
CM_ SG_ 1028 bDernUndrIdc3 "Derating because of overcurrent regenerative Inverter3 E-machine";
CM_ SG_ 1028 bDernTemp3 "Derating because of overtemperature E-machine";
CM_ SG_ 1028 bDiagReq3 "Diag request for e-machine Inverter3 Calibration";
CM_ SG_ 1028 bDernTrqMin3 "Derating because of max torque regenerative";
CM_ SG_ 1028 bDernTrqMax3 "Derating because of max torque";
CM_ SG_ 1028 bDstActv3 "Surge Damping active";
CM_ SG_ 1028 bReadyHV3 "HV voltage operational";
CM_ SG_ 266 RequestedState4 "Request to the electric machine";
CM_ SG_ 266 DesiredSpeed4 "Desired speed electric machine";
CM_ SG_ 266 DesiredTorque4 "Desired torque electric machine";
CM_ SG_ 266 UdcSetP4 "Setpoint voltage E-Machine";
CM_ SG_ 266 Checksum_10A "Checksum signal for frame";
CM_ SG_ 266 MessageCounter_10A "Message counter signal for frame";
CM_ SG_ 266 StHvbMaiRly4 "State4 of main relay, alternative signal to ContactorState";
CM_ SG_ 310 MessageCounter_136 "Message counter signal for frame";
CM_ SG_ 310 Checksum_136 "Checksum signal for frame";
CM_ SG_ 310 VoltageDemandLV4 "Desired voltage of the DCDC converter LV side";
CM_ SG_ 310 VoltageDemandHV4 "Desired voltage of the DCDC converter HV side";
CM_ SG_ 310 ModeRequest4 "Requested State4 of the DCDC converter";
CM_ SG_ 310 CurrentDemandLV4 "Demanded current on LV side";
CM_ SG_ 310 CurrentDemandHV4 "Demanded current of DCDC converter HV side";
CM_ SG_ 784 UdcMin4 "min voltage HV";
CM_ SG_ 784 UdcMax4 "max voltage HV";
CM_ SG_ 784 IdcMin4 "max current for regenerative current";
CM_ SG_ 784 IdcMax4 "max current for motor torque";
CM_ SG_ 784 MessageCounter_310 "Message counter signal for frame";
CM_ SG_ 784 Checksum_310 "Checksum signal for frame";
CM_ SG_ 784 flgInvrCanActvnCmd4 "Activates CAN activity of inverter4";
CM_ SG_ 786 KI_Faktor4 "Integral gain Ki";
CM_ SG_ 786 MessageCounter_312 "Message counter signal for frame";
CM_ SG_ 786 Checksum_312 "Checksum signal for frame";
CM_ SG_ 786 MinTorqueLimit4 "Lower limit output torque of electric machine";
CM_ SG_ 786 MaxTorqueLimit4 "Upper limit output torque of electric machine";
CM_ SG_ 786 MaxTorqueGradient4 "Maximum change rate of the torque demand";
CM_ SG_ 522 CurrentHV4 "HV current at the DC/AC converter";
CM_ SG_ 522 OutputTorque4 "output torque which is currently provided by the electric machine";
CM_ SG_ 522 State4 "Information of the  State4 of the electric machine";
CM_ SG_ 522 Speed4 "rotational speed of electric machine";
CM_ SG_ 522 Checksum_20A "Checksum signal for frame";
CM_ SG_ 522 MessageCounter_20A "Message counter signal for frame";
CM_ SG_ 534 dataInvrNr4 "Inverter number which has been configured via UDS/BODAS";
CM_ SG_ 534 MaxTorque4 "Electric machine torque value";
CM_ SG_ 534 MinTorque4 "Total brake torque minimum";
CM_ SG_ 534 Checksum_216 "Checksum signal for frame";
CM_ SG_ 534 MessageCounter_216 "Message counter signal for frame";
CM_ SG_ 534 TrqCurrWoDstC4 "e-machine torque without part of damping control";
CM_ SG_ 534 TempCurrCool4 "temperature of Inverter4 cooling water";
CM_ SG_ 550 Mode4 "State4 DC/DC converter";
CM_ SG_ 550 CurrentLV4 "current on low voltage side";
CM_ SG_ 550 VoltageLV4 "voltage on low voltage side";
CM_ SG_ 550 DcCurrentHV4 "current of the DC/DC converter at high voltage side";
CM_ SG_ 550 VoltageHV4 "voltage at high voltage side";
CM_ SG_ 550 TempCurr4 " temperature of DCDC";
CM_ SG_ 550 Checksum_226 "Checksum signal for frame";
CM_ SG_ 550 MessageCounter_226 "Message counter signal for frame";
CM_ SG_ 1574 ElectricMachineTemperature4 "Current temperature of electric machine";
CM_ SG_ 1574 InverterTemperature4 "Current temperature of Inverter4";
CM_ SG_ 1574 UT30Curr4 "Current UT30 Voltage at Inverter4";
CM_ SG_ 1574 TempCurrRotor4 "Temperature of rotor";
CM_ SG_ 1574 Checksum_626 "Checksum signal for frame";
CM_ SG_ 1574 MessageCounter_626 "Message counter signal for frame";
CM_ SG_ 1047 DC_MaxCurrentLV4 "Maximal allowed current at low voltage side";
CM_ SG_ 1047 DC_MaxCurrentHV4 "Maximal allowed current at high voltage side";
CM_ SG_ 1047 bDernUndrUdcLV4 "Derating because of Low Voltage at LV";
CM_ SG_ 1047 ErrShtOff4 "Derating because of DCDC shutdown";
CM_ SG_ 1047 bDernOvrIdcLv4 "Derating because of high current at LV";
CM_ SG_ 1047 bDernOvrIdcHV4 "Derating because of high current at HV";
CM_ SG_ 1047 bDernOvrUdcLv4 "Derating because of error high voltage at LV";
CM_ SG_ 1047 bDernUndrUdcHV4 "Derating because of error low voltage at HV";
CM_ SG_ 1047 ErrLimitedPerformance4 "limited performance of DCDC";
CM_ SG_ 1047 bDernTemp_DCDC4 "Derating because of overtemperature DCDC";
CM_ SG_ 1047 bDernOvrUdcHV4 "Derating because of high voltage at HV";
CM_ SG_ 1047 bErrVltg4 "shutdown because of Over/Undervoltage at I/O side";
CM_ SG_ 1047 Checksum_417 "Checksum signal for frame";
CM_ SG_ 1047 MessageCounter_417 "Message counter signal for frame";
CM_ SG_ 1030 EmergencyShutoffRequest4 "Emergency shut off requested by inverter ECU";
CM_ SG_ 1030 bDernOvrUdc4 "Derating because of overvoltage HV";
CM_ SG_ 1030 bDernUndrUdc4 "Derating because of undervoltage HV";
CM_ SG_ 1030 Checksum_406 "Checksum signal for frame";
CM_ SG_ 1030 MessageCounter_406 "Message counter signal for frame";
CM_ SG_ 1030 bDernOvrIdc4 "Derating because of overcurrent Inverter4 E-machine";
CM_ SG_ 1030 bDernUndrIdc4 "Derating because of overcurrent regenerative Inverter4 E-machine";
CM_ SG_ 1030 bDernTemp4 "Derating because of overtemperature E-machine";
CM_ SG_ 1030 bDiagReq4 "Diag request for e-machine Inverter4 Calibration";
CM_ SG_ 1030 bDernTrqMin4 "Derating because of max torque regenerative";
CM_ SG_ 1030 bDernTrqMax4 "Derating because of max torque";
CM_ SG_ 1030 bDstActv4 "Surge Damping active";
CM_ SG_ 1030 bReadyHV4 "HV voltage operational";
CM_ SG_ 268 RequestedState5 "Request to the electric machine";
CM_ SG_ 268 DesiredSpeed5 "Desired speed electric machine";
CM_ SG_ 268 DesiredTorque5 "Desired torque electric machine";
CM_ SG_ 268 UdcSetP5 "Setpoint voltage E-Machine";
CM_ SG_ 268 Checksum_10C "Checksum signal for frame";
CM_ SG_ 268 MessageCounter_10C "Message counter signal for frame";
CM_ SG_ 268 StHvbMaiRly5 "State5 of main relay, alternative signal to ContactorState";
CM_ SG_ 312 MessageCounter_138 "Message counter signal for frame";
CM_ SG_ 312 Checksum_138 "Checksum signal for frame";
CM_ SG_ 312 VoltageDemandLV5 "Desired voltage of the DCDC converter LV side";
CM_ SG_ 312 VoltageDemandHV5 "Desired voltage of the DCDC converter HV side";
CM_ SG_ 312 ModeRequest5 "Requested State5 of the DCDC converter";
CM_ SG_ 312 CurrentDemandLV5 "Demanded current on LV side";
CM_ SG_ 312 CurrentDemandHV5 "Demanded current of DCDC converter HV side";
CM_ SG_ 788 UdcMin5 "min voltage HV";
CM_ SG_ 788 UdcMax5 "max voltage HV";
CM_ SG_ 788 IdcMin5 "max current for regenerative current";
CM_ SG_ 788 IdcMax5 "max current for motor torque";
CM_ SG_ 788 MessageCounter_314 "Message counter signal for frame";
CM_ SG_ 788 Checksum_314 "Checksum signal for frame";
CM_ SG_ 788 flgInvrCanActvnCmd5 "Activates CAN activity of inverter5";
CM_ SG_ 790 KI_Faktor5 "Integral gain Ki";
CM_ SG_ 790 MessageCounter_316 "Message counter signal for frame";
CM_ SG_ 790 Checksum_316 "Checksum signal for frame";
CM_ SG_ 790 MinTorqueLimit5 "Lower limit output torque of electric machine";
CM_ SG_ 790 MaxTorqueLimit5 "Upper limit output torque of electric machine";
CM_ SG_ 790 MaxTorqueGradient5 "Maximum change rate of the torque demand";
CM_ SG_ 1757 DIAG_Downtime "Calculated Downtime of System (car sleep)";
CM_ SG_ 1757 DIAG_Downtime_state "state of downtime
0 -> not valid/calculated
1 -> valid";
CM_ SG_ 1757 DIAG_Second "Second";
CM_ SG_ 1757 DIAG_Minute "Minute";
CM_ SG_ 1757 DIAG_Hour "Hour";
CM_ SG_ 1757 DIAG_Day "Day";
CM_ SG_ 1757 DIAG_Month "Month";
CM_ SG_ 1757 DIAG_Year "year";
CM_ SG_ 1757 DIAG_Mileage "Mileage";
CM_ SG_ 524 CurrentHV5 "HV current at the DC/AC converter";
CM_ SG_ 524 OutputTorque5 "output torque which is currently provided by the electric machine";
CM_ SG_ 524 State5 "Information of the  State5 of the electric machine";
CM_ SG_ 524 Speed5 "rotational speed of electric machine";
CM_ SG_ 524 Checksum_20C "Checksum signal for frame";
CM_ SG_ 524 MessageCounter_20C "Message counter signal for frame";
CM_ SG_ 536 dataInvrNr5 "Inverter number which has been configured via UDS/BODAS";
CM_ SG_ 536 MaxTorque5 "Electric machine torque value";
CM_ SG_ 536 MinTorque5 "Total brake torque minimum";
CM_ SG_ 536 Checksum_218 "Checksum signal for frame";
CM_ SG_ 536 MessageCounter_218 "Message counter signal for frame";
CM_ SG_ 536 TrqCurrWoDstC5 "e-machine torque without part of damping control";
CM_ SG_ 536 TempCurrCool5 "temperature of Inverter5 cooling water";
CM_ SG_ 552 Mode5 "State5 DC/DC converter";
CM_ SG_ 552 CurrentLV5 "current on low voltage side";
CM_ SG_ 552 VoltageLV5 "voltage on low voltage side";
CM_ SG_ 552 DcCurrentHV5 "current of the DC/DC converter at high voltage side";
CM_ SG_ 552 VoltageHV5 "voltage at high voltage side";
CM_ SG_ 552 TempCurr5 " temperature of DCDC";
CM_ SG_ 552 Checksum_228 "Checksum signal for frame";
CM_ SG_ 552 MessageCounter_228 "Message counter signal for frame";
CM_ SG_ 1576 ElectricMachineTemperature5 "Current temperature of electric machine";
CM_ SG_ 1576 InverterTemperature5 "Current temperature of Inverter5";
CM_ SG_ 1576 UT30Curr5 "Current UT30 Voltage at Inverter5";
CM_ SG_ 1576 TempCurrRotor5 "Temperature of rotor";
CM_ SG_ 1576 Checksum_628 "Checksum signal for frame";
CM_ SG_ 1576 MessageCounter_628 "Message counter signal for frame";
CM_ SG_ 1049 DC_MaxCurrentLV5 "Maximal allowed current at low voltage side";
CM_ SG_ 1049 DC_MaxCurrentHV5 "Maximal allowed current at high voltage side";
CM_ SG_ 1049 bDernUndrUdcLV5 "Derating because of Low Voltage at LV";
CM_ SG_ 1049 ErrShtOff5 "Derating because of DCDC shutdown";
CM_ SG_ 1049 bDernOvrIdcLv5 "Derating because of high current at LV";
CM_ SG_ 1049 bDernOvrIdcHV5 "Derating because of high current at HV";
CM_ SG_ 1049 bDernOvrUdcLv5 "Derating because of error high voltage at LV";
CM_ SG_ 1049 bDernUndrUdcHV5 "Derating because of error low voltage at HV";
CM_ SG_ 1049 ErrLimitedPerformance5 "limited performance of DCDC";
CM_ SG_ 1049 bDernTemp_DCDC5 "Derating because of overtemperature DCDC";
CM_ SG_ 1049 bDernOvrUdcHV5 "Derating because of high voltage at HV";
CM_ SG_ 1049 bErrVltg5 "shutdown because of Over/Undervoltage at I/O side";
CM_ SG_ 1049 Checksum_419 "Checksum signal for frame";
CM_ SG_ 1049 MessageCounter_419 "Message counter signal for frame";
CM_ SG_ 1032 EmergencyShutoffRequest5 "Emergency shut off requested by inverter ECU";
CM_ SG_ 1032 bDernOvrUdc5 "Derating because of overvoltage HV";
CM_ SG_ 1032 bDernUndrUdc5 "Derating because of undervoltage HV";
CM_ SG_ 1032 Checksum_408 "Checksum signal for frame";
CM_ SG_ 1032 MessageCounter_408 "Message counter signal for frame";
CM_ SG_ 1032 bDernOvrIdc5 "Derating because of overcurrent Inverter5 E-machine";
CM_ SG_ 1032 bDernUndrIdc5 "Derating because of overcurrent regenerative Inverter5 E-machine";
CM_ SG_ 1032 bDernTemp5 "Derating because of overtemperature E-machine";
CM_ SG_ 1032 bDiagReq5 "Diag request for e-machine Inverter5 Calibration";
CM_ SG_ 1032 bDernTrqMin5 "Derating because of max torque regenerative";
CM_ SG_ 1032 bDernTrqMax5 "Derating because of max torque";
CM_ SG_ 1032 bDstActv5 "Surge Damping active";
CM_ SG_ 1032 bReadyHV5 "HV voltage operational";
BA_DEF_  "BusType" STRING ;
BA_DEF_  "BusSpeed" STRING ;
BA_DEF_  "DBName" STRING ;
BA_DEF_ BU_  "NodeLongName" STRING ;
BA_DEF_ BO_  "DiagResponse" ENUM  "No","Yes";
BA_DEF_ BO_  "DiagRequest" ENUM  "No","Yes";
BA_DEF_ BO_  "DiagState" ENUM  "No","Yes";
BA_DEF_ BO_  "GenMsgCycleTime" INT 0 65535;
BA_DEF_ BO_  "GenMsgSendType" ENUM  "Cyclic","Event","Mixed","not_used","not_used","not_used","not_used","not_used","NoMsgSendType";
BA_DEF_ BO_  "GenMsgDelayTime" INT 0 100000;
BA_DEF_ BO_  "GenMsgCycleTimeFast" INT 0 100000;
BA_DEF_ BO_  "GenMsgChkConstant" HEX 0 4095;
BA_DEF_ BO_  "MsgLongName" STRING ;
BA_DEF_ BO_  "MsgType" ENUM  "Application","NM ","NMH","TP2.0","ISO-TP ","BAP","EID";
BA_DEF_ SG_  "GenSigSendType" ENUM  "Cyclic","OnWrite","OnWriteWithRepetition","OnChange","OnChangeWithRepetition","IfActive","IfActiveWithRepetition","NoSigSendType","OnChangeAndIfActive","OnChangeAndIfActiveWithRepetition";
BA_DEF_ SG_  "GenSigFuncType" ENUM  "NoFunction","MsgCounter","CRC-8","XOR","XOR-2","DatedBit","SW-Kl15","CHK","Constant","Protocol","CRC-8-SAE_J1850";
BA_DEF_ SG_  "GenSigInactiveValue" INT 0 0;
BA_DEF_ SG_  "SigLongName" STRING ;
BA_DEF_ SG_  "GenSigStartValue" INT -2147483648 2147483647;
BA_DEF_DEF_  "BusType" "CAN";
BA_DEF_DEF_  "BusSpeed" "500k";
BA_DEF_DEF_  "DBName" "";
BA_DEF_DEF_  "NodeLongName" "";
BA_DEF_DEF_  "DiagResponse" "No";
BA_DEF_DEF_  "DiagRequest" "No";
BA_DEF_DEF_  "DiagState" "No";
BA_DEF_DEF_  "GenMsgCycleTime" 0;
BA_DEF_DEF_  "GenMsgSendType" "NoMsgSendType";
BA_DEF_DEF_  "GenMsgDelayTime" 0;
BA_DEF_DEF_  "GenMsgCycleTimeFast" 0;
BA_DEF_DEF_  "GenMsgChkConstant" 0;
BA_DEF_DEF_  "MsgLongName" "";
BA_DEF_DEF_  "MsgType" "Application";
BA_DEF_DEF_  "GenSigSendType" "Cyclic";
BA_DEF_DEF_  "GenSigFuncType" "NoFunction";
BA_DEF_DEF_  "GenSigInactiveValue" 0;
BA_DEF_DEF_  "SigLongName" "";
BA_DEF_DEF_  "GenSigStartValue" 0;
BA_ "BusSpeed" "500K";
BA_ "DBName" "OHW_EDrive_Inno";
BA_ "NodeLongName" BU_ INVCON0 "Inverter1 - INVCON 2.3";
BA_ "NodeLongName" BU_ VCU "Generic Main Controller";
BA_ "NodeLongName" BU_ INVCON1 "Inverter1 - INVCON 2.3";
BA_ "NodeLongName" BU_ INVCON2 "Inverter2 - INVCON 2.3";
BA_ "NodeLongName" BU_ INVCON3 "Inverter3 - INVCON 2.3";
BA_ "NodeLongName" BU_ INVCON4 "Inverter4 - INVCON 2.3";
BA_ "NodeLongName" BU_ INVCON5 "Inverter5 - INVCON 2.3";
BA_ "GenMsgSendType" BO_ 292 0;
BA_ "GenMsgCycleTime" BO_ 292 100;
BA_ "GenMsgSendType" BO_ 291 0;
BA_ "GenMsgCycleTime" BO_ 291 100;
BA_ "GenMsgSendType" BO_ 290 0;
BA_ "GenMsgCycleTime" BO_ 290 100;
BA_ "GenMsgSendType" BO_ 289 0;
BA_ "GenMsgCycleTime" BO_ 289 100;
BA_ "GenMsgSendType" BO_ 288 0;
BA_ "GenMsgCycleTime" BO_ 288 100;
BA_ "GenMsgCycleTime" BO_ 1663 100;
BA_ "GenMsgSendType" BO_ 1663 1;
BA_ "GenMsgCycleTime" BO_ 1668 100;
BA_ "GenMsgSendType" BO_ 1668 0;
BA_ "GenMsgCycleTime" BO_ 1667 100;
BA_ "GenMsgSendType" BO_ 1667 0;
BA_ "GenMsgCycleTime" BO_ 1666 100;
BA_ "GenMsgSendType" BO_ 1666 0;
BA_ "GenMsgCycleTime" BO_ 1665 100;
BA_ "GenMsgSendType" BO_ 1665 0;
BA_ "GenMsgCycleTime" BO_ 1664 100;
BA_ "GenMsgSendType" BO_ 1664 0;
BA_ "GenMsgCycleTime" BO_ 789 100;
BA_ "GenMsgSendType" BO_ 789 0;
BA_ "GenMsgCycleTime" BO_ 785 100;
BA_ "GenMsgSendType" BO_ 785 0;
BA_ "GenMsgCycleTime" BO_ 781 100;
BA_ "GenMsgSendType" BO_ 781 0;
BA_ "GenMsgCycleTime" BO_ 777 100;
BA_ "GenMsgSendType" BO_ 777 0;
BA_ "GenMsgCycleTime" BO_ 773 100;
BA_ "GenMsgSendType" BO_ 773 0;
BA_ "GenMsgSendType" BO_ 260 0;
BA_ "GenMsgCycleTime" BO_ 260 10;
BA_ "GenMsgSendType" BO_ 304 0;
BA_ "GenMsgCycleTime" BO_ 304 10;
BA_ "GenMsgSendType" BO_ 772 0;
BA_ "GenMsgCycleTime" BO_ 772 10;
BA_ "GenMsgSendType" BO_ 774 0;
BA_ "GenMsgCycleTime" BO_ 774 100;
BA_ "GenMsgCycleTime" BO_ 516 10;
BA_ "GenMsgSendType" BO_ 516 0;
BA_ "GenMsgCycleTime" BO_ 528 10;
BA_ "GenMsgSendType" BO_ 528 0;
BA_ "GenMsgCycleTime" BO_ 544 10;
BA_ "GenMsgSendType" BO_ 544 0;
BA_ "GenMsgCycleTime" BO_ 1568 100;
BA_ "GenMsgSendType" BO_ 1568 0;
BA_ "GenMsgCycleTime" BO_ 1041 100;
BA_ "GenMsgSendType" BO_ 1041 0;
BA_ "GenMsgCycleTime" BO_ 1024 100;
BA_ "GenMsgSendType" BO_ 1024 0;
BA_ "GenMsgCycleTime" BO_ 110 10;
BA_ "GenMsgSendType" BO_ 110 0;
BA_ "GenMsgSendType" BO_ 262 0;
BA_ "GenMsgCycleTime" BO_ 262 10;
BA_ "GenMsgSendType" BO_ 306 0;
BA_ "GenMsgCycleTime" BO_ 306 10;
BA_ "GenMsgSendType" BO_ 776 0;
BA_ "GenMsgCycleTime" BO_ 776 10;
BA_ "GenMsgSendType" BO_ 778 0;
BA_ "GenMsgCycleTime" BO_ 778 100;
BA_ "GenMsgCycleTime" BO_ 518 10;
BA_ "GenMsgSendType" BO_ 518 0;
BA_ "GenMsgCycleTime" BO_ 530 10;
BA_ "GenMsgSendType" BO_ 530 0;
BA_ "GenMsgCycleTime" BO_ 546 10;
BA_ "GenMsgSendType" BO_ 546 0;
BA_ "GenMsgCycleTime" BO_ 1570 100;
BA_ "GenMsgSendType" BO_ 1570 0;
BA_ "GenMsgCycleTime" BO_ 1043 100;
BA_ "GenMsgSendType" BO_ 1043 0;
BA_ "GenMsgCycleTime" BO_ 1026 100;
BA_ "GenMsgSendType" BO_ 1026 0;
BA_ "GenMsgSendType" BO_ 264 0;
BA_ "GenMsgCycleTime" BO_ 264 10;
BA_ "GenMsgSendType" BO_ 308 0;
BA_ "GenMsgCycleTime" BO_ 308 10;
BA_ "GenMsgSendType" BO_ 780 0;
BA_ "GenMsgCycleTime" BO_ 780 10;
BA_ "GenMsgSendType" BO_ 782 0;
BA_ "GenMsgCycleTime" BO_ 782 100;
BA_ "GenMsgCycleTime" BO_ 520 10;
BA_ "GenMsgSendType" BO_ 520 0;
BA_ "GenMsgCycleTime" BO_ 532 10;
BA_ "GenMsgSendType" BO_ 532 0;
BA_ "GenMsgCycleTime" BO_ 548 10;
BA_ "GenMsgSendType" BO_ 548 0;
BA_ "GenMsgCycleTime" BO_ 1572 100;
BA_ "GenMsgSendType" BO_ 1572 0;
BA_ "GenMsgCycleTime" BO_ 1045 100;
BA_ "GenMsgSendType" BO_ 1045 0;
BA_ "GenMsgCycleTime" BO_ 1028 100;
BA_ "GenMsgSendType" BO_ 1028 0;
BA_ "GenMsgCycleTime" BO_ 266 10;
BA_ "GenMsgSendType" BO_ 266 0;
BA_ "GenMsgCycleTime" BO_ 310 10;
BA_ "GenMsgSendType" BO_ 310 0;
BA_ "GenMsgCycleTime" BO_ 784 10;
BA_ "GenMsgSendType" BO_ 784 0;
BA_ "GenMsgCycleTime" BO_ 786 100;
BA_ "GenMsgSendType" BO_ 786 0;
BA_ "GenMsgSendType" BO_ 522 0;
BA_ "GenMsgCycleTime" BO_ 522 10;
BA_ "GenMsgSendType" BO_ 534 0;
BA_ "GenMsgCycleTime" BO_ 534 10;
BA_ "GenMsgSendType" BO_ 550 0;
BA_ "GenMsgCycleTime" BO_ 550 10;
BA_ "GenMsgSendType" BO_ 1574 0;
BA_ "GenMsgCycleTime" BO_ 1574 100;
BA_ "GenMsgSendType" BO_ 1047 0;
BA_ "GenMsgCycleTime" BO_ 1047 100;
BA_ "GenMsgSendType" BO_ 1030 0;
BA_ "GenMsgCycleTime" BO_ 1030 100;
BA_ "GenMsgSendType" BO_ 268 0;
BA_ "GenMsgCycleTime" BO_ 268 10;
BA_ "GenMsgSendType" BO_ 312 0;
BA_ "GenMsgCycleTime" BO_ 312 10;
BA_ "GenMsgSendType" BO_ 788 0;
BA_ "GenMsgCycleTime" BO_ 788 10;
BA_ "GenMsgSendType" BO_ 790 0;
BA_ "GenMsgCycleTime" BO_ 790 100;
BA_ "GenMsgCycleTime" BO_ 1757 1000;
BA_ "GenMsgSendType" BO_ 1757 0;
BA_ "GenMsgCycleTime" BO_ 524 10;
BA_ "GenMsgSendType" BO_ 524 0;
BA_ "GenMsgCycleTime" BO_ 536 10;
BA_ "GenMsgSendType" BO_ 536 0;
BA_ "GenMsgCycleTime" BO_ 552 10;
BA_ "GenMsgSendType" BO_ 552 0;
BA_ "GenMsgCycleTime" BO_ 1576 100;
BA_ "GenMsgSendType" BO_ 1576 0;
BA_ "GenMsgCycleTime" BO_ 1049 100;
BA_ "GenMsgSendType" BO_ 1049 0;
BA_ "GenMsgCycleTime" BO_ 1032 100;
BA_ "GenMsgSendType" BO_ 1032 0;
BA_ "GenSigStartValue" SG_ 292 SurgeDamperTreshold5 1022;
BA_ "GenSigStartValue" SG_ 292 SurgeDamperMaxTorque5 1022;
BA_ "GenSigStartValue" SG_ 292 SurgeDamperFactor5 254;
BA_ "GenSigStartValue" SG_ 291 SurgeDamperTreshold4 1022;
BA_ "GenSigStartValue" SG_ 291 SurgeDamperMaxTorque4 1022;
BA_ "GenSigStartValue" SG_ 291 SurgeDamperFactor4 254;
BA_ "GenSigStartValue" SG_ 290 SurgeDamperTreshold3 1022;
BA_ "GenSigStartValue" SG_ 290 SurgeDamperMaxTorque3 1022;
BA_ "GenSigStartValue" SG_ 290 SurgeDamperFactor3 254;
BA_ "GenSigStartValue" SG_ 289 SurgeDamperTreshold2 1022;
BA_ "GenSigStartValue" SG_ 289 SurgeDamperMaxTorque2 1022;
BA_ "GenSigStartValue" SG_ 289 SurgeDamperFactor2 254;
BA_ "GenSigStartValue" SG_ 288 SurgeDamperTreshold1 1022;
BA_ "GenSigStartValue" SG_ 288 SurgeDamperMaxTorque1 1022;
BA_ "GenSigStartValue" SG_ 288 SurgeDamperFactor1 254;
BA_ "GenSigFuncType" SG_ 789 Checksum_315 3;
BA_ "GenSigFuncType" SG_ 789 MessageCounter_315 1;
BA_ "GenSigStartValue" SG_ 789 MaxTorqueEngineSpeed5 2046;
BA_ "GenSigStartValue" SG_ 789 MinTorqueEngineSpeed5 2046;
BA_ "GenSigStartValue" SG_ 789 MaxDeltaSpeed5 4094;
BA_ "GenSigStartValue" SG_ 789 FactorPContributionSmall5 510;
BA_ "GenSigStartValue" SG_ 789 FactorPContributionLarge5 510;
BA_ "GenSigFuncType" SG_ 785 Checksum_311 3;
BA_ "GenSigFuncType" SG_ 785 MessageCounter_311 1;
BA_ "GenSigStartValue" SG_ 785 MaxTorqueEngineSpeed4 2046;
BA_ "GenSigStartValue" SG_ 785 MinTorqueEngineSpeed4 2046;
BA_ "GenSigStartValue" SG_ 785 MaxDeltaSpeed4 4094;
BA_ "GenSigStartValue" SG_ 785 FactorPContributionSmall4 510;
BA_ "GenSigStartValue" SG_ 785 FactorPContributionLarge4 510;
BA_ "GenSigFuncType" SG_ 781 Checksum_30D 3;
BA_ "GenSigFuncType" SG_ 781 MessageCounter_30D 1;
BA_ "GenSigStartValue" SG_ 781 MaxTorqueEngineSpeed3 2046;
BA_ "GenSigStartValue" SG_ 781 MinTorqueEngineSpeed3 2046;
BA_ "GenSigStartValue" SG_ 781 MaxDeltaSpeed3 4094;
BA_ "GenSigStartValue" SG_ 781 FactorPContributionSmall3 510;
BA_ "GenSigStartValue" SG_ 781 FactorPContributionLarge3 510;
BA_ "GenSigFuncType" SG_ 777 Checksum_309 3;
BA_ "GenSigFuncType" SG_ 777 MessageCounter_309 1;
BA_ "GenSigStartValue" SG_ 777 MaxTorqueEngineSpeed2 2046;
BA_ "GenSigStartValue" SG_ 777 MinTorqueEngineSpeed2 2046;
BA_ "GenSigStartValue" SG_ 777 MaxDeltaSpeed2 4094;
BA_ "GenSigStartValue" SG_ 777 FactorPContributionSmall2 510;
BA_ "GenSigStartValue" SG_ 777 FactorPContributionLarge2 510;
BA_ "GenSigFuncType" SG_ 773 Checksum_305 3;
BA_ "GenSigFuncType" SG_ 773 MessageCounter_305 1;
BA_ "GenSigStartValue" SG_ 773 MaxTorqueEngineSpeed1 2046;
BA_ "GenSigStartValue" SG_ 773 MinTorqueEngineSpeed1 2046;
BA_ "GenSigStartValue" SG_ 773 MaxDeltaSpeed1 4094;
BA_ "GenSigStartValue" SG_ 773 FactorPContributionSmall1 510;
BA_ "GenSigStartValue" SG_ 773 FactorPContributionLarge1 510;
BA_ "GenSigStartValue" SG_ 260 DesiredSpeed1 65534;
BA_ "GenSigStartValue" SG_ 260 DesiredTorque1 2046;
BA_ "GenSigStartValue" SG_ 260 UdcSetP1 1022;
BA_ "GenSigFuncType" SG_ 260 Checksum_104 3;
BA_ "GenSigFuncType" SG_ 260 MessageCounter_104 1;
BA_ "GenSigStartValue" SG_ 260 StHvbMaiRly1 6;
BA_ "GenSigFuncType" SG_ 304 MessageCounter_130 1;
BA_ "GenSigFuncType" SG_ 304 Checksum_130 3;
BA_ "GenSigStartValue" SG_ 304 VoltageDemandLV1 510;
BA_ "GenSigStartValue" SG_ 304 VoltageDemandHV1 1022;
BA_ "GenSigStartValue" SG_ 304 CurrentDemandLV1 2046;
BA_ "GenSigStartValue" SG_ 304 CurrentDemandHV1 2046;
BA_ "GenSigStartValue" SG_ 772 UdcMin1 1022;
BA_ "GenSigStartValue" SG_ 772 UdcMax1 1022;
BA_ "GenSigStartValue" SG_ 772 IdcMin1 2046;
BA_ "GenSigStartValue" SG_ 772 IdcMax1 2046;
BA_ "GenSigFuncType" SG_ 772 MessageCounter_304 1;
BA_ "GenSigFuncType" SG_ 772 Checksum_304 3;
BA_ "GenSigStartValue" SG_ 774 KI_Faktor1 32766;
BA_ "GenSigFuncType" SG_ 774 MessageCounter_306 1;
BA_ "GenSigFuncType" SG_ 774 Checksum_306 3;
BA_ "GenSigStartValue" SG_ 774 MinTorqueLimit1 2046;
BA_ "GenSigStartValue" SG_ 774 MaxTorqueLimit1 2046;
BA_ "GenSigStartValue" SG_ 774 MaxTorqueGradient1 32766;
BA_ "GenSigStartValue" SG_ 516 CurrentHV1 1023;
BA_ "GenSigStartValue" SG_ 516 OutputTorque1 2046;
BA_ "GenSigStartValue" SG_ 516 Speed1 65534;
BA_ "GenSigFuncType" SG_ 516 Checksum_204 3;
BA_ "GenSigFuncType" SG_ 516 MessageCounter_204 1;
BA_ "GenSigStartValue" SG_ 528 MaxTorque1 1023;
BA_ "GenSigStartValue" SG_ 528 MinTorque1 1023;
BA_ "GenSigFuncType" SG_ 528 Checksum_210 3;
BA_ "GenSigFuncType" SG_ 528 MessageCounter_210 1;
BA_ "GenSigStartValue" SG_ 528 TrqCurrWoDstC1 1023;
BA_ "GenSigStartValue" SG_ 528 TempCurrCool1 254;
BA_ "GenSigStartValue" SG_ 544 CurrentLV1 1023;
BA_ "GenSigStartValue" SG_ 544 DcCurrentHV1 1024;
BA_ "GenSigStartValue" SG_ 544 TempCurr1 254;
BA_ "GenSigFuncType" SG_ 544 Checksum_220 3;
BA_ "GenSigFuncType" SG_ 544 MessageCounter_220 1;
BA_ "GenSigStartValue" SG_ 1568 ElectricMachineTemperature1 254;
BA_ "GenSigStartValue" SG_ 1568 InverterTemperature1 254;
BA_ "GenSigStartValue" SG_ 1568 TempCurrRotor1 254;
BA_ "GenSigFuncType" SG_ 1568 Checksum_620 3;
BA_ "GenSigFuncType" SG_ 1568 MessageCounter_620 1;
BA_ "GenSigStartValue" SG_ 1041 DC_MaxCurrentLV1 1023;
BA_ "GenSigFuncType" SG_ 1041 Checksum_411 3;
BA_ "GenSigFuncType" SG_ 1041 MessageCounter_411 1;
BA_ "GenSigFuncType" SG_ 1024 Checksum_400 3;
BA_ "GenSigFuncType" SG_ 1024 MessageCounter_400 1;
BA_ "GenSigFuncType" SG_ 110 MessageCounter_6E 1;
BA_ "GenSigFuncType" SG_ 110 Checksum_6E 3;
BA_ "GenSigStartValue" SG_ 110 ContactorState 6;
BA_ "GenSigStartValue" SG_ 110 Current 4094;
BA_ "GenSigStartValue" SG_ 110 Voltage 4094;
BA_ "GenSigStartValue" SG_ 262 DesiredSpeed2 65534;
BA_ "GenSigStartValue" SG_ 262 DesiredTorque2 2046;
BA_ "GenSigStartValue" SG_ 262 UdcSetP2 1022;
BA_ "GenSigFuncType" SG_ 262 Checksum_106 3;
BA_ "GenSigFuncType" SG_ 262 MessageCounter_106 1;
BA_ "GenSigStartValue" SG_ 262 StHvbMaiRly2 6;
BA_ "GenSigFuncType" SG_ 306 MessageCounter_132 1;
BA_ "GenSigFuncType" SG_ 306 Checksum_132 3;
BA_ "GenSigStartValue" SG_ 306 VoltageDemandLV2 510;
BA_ "GenSigStartValue" SG_ 306 VoltageDemandHV2 1022;
BA_ "GenSigStartValue" SG_ 306 CurrentDemandLV2 2046;
BA_ "GenSigStartValue" SG_ 306 CurrentDemandHV2 2046;
BA_ "GenSigStartValue" SG_ 776 UdcMin2 1022;
BA_ "GenSigStartValue" SG_ 776 UdcMax2 1022;
BA_ "GenSigStartValue" SG_ 776 IdcMin2 2046;
BA_ "GenSigStartValue" SG_ 776 IdcMax2 2046;
BA_ "GenSigFuncType" SG_ 776 MessageCounter_308 1;
BA_ "GenSigFuncType" SG_ 776 Checksum_308 3;
BA_ "GenSigStartValue" SG_ 778 KI_Faktor2 32766;
BA_ "GenSigFuncType" SG_ 778 MessageCounter_30A 1;
BA_ "GenSigFuncType" SG_ 778 Checksum_30A 3;
BA_ "GenSigStartValue" SG_ 778 MinTorqueLimit2 2046;
BA_ "GenSigStartValue" SG_ 778 MaxTorqueLimit2 2046;
BA_ "GenSigStartValue" SG_ 778 MaxTorqueGradient2 32766;
BA_ "GenSigStartValue" SG_ 518 CurrentHV2 1023;
BA_ "GenSigStartValue" SG_ 518 OutputTorque2 2046;
BA_ "GenSigStartValue" SG_ 518 Speed2 65534;
BA_ "GenSigFuncType" SG_ 518 Checksum_206 3;
BA_ "GenSigFuncType" SG_ 518 MessageCounter_206 1;
BA_ "GenSigStartValue" SG_ 530 MaxTorque2 1023;
BA_ "GenSigStartValue" SG_ 530 MinTorque2 1023;
BA_ "GenSigFuncType" SG_ 530 Checksum_212 3;
BA_ "GenSigFuncType" SG_ 530 MessageCounter_212 1;
BA_ "GenSigStartValue" SG_ 530 TrqCurrWoDstC2 1023;
BA_ "GenSigStartValue" SG_ 530 TempCurrCool2 254;
BA_ "GenSigStartValue" SG_ 546 CurrentLV2 1023;
BA_ "GenSigStartValue" SG_ 546 DcCurrentHV2 1024;
BA_ "GenSigStartValue" SG_ 546 TempCurr2 254;
BA_ "GenSigFuncType" SG_ 546 Checksum_222 3;
BA_ "GenSigFuncType" SG_ 546 MessageCounter_222 1;
BA_ "GenSigStartValue" SG_ 1570 ElectricMachineTemperature2 254;
BA_ "GenSigStartValue" SG_ 1570 InverterTemperature2 254;
BA_ "GenSigStartValue" SG_ 1570 TempCurrRotor2 254;
BA_ "GenSigFuncType" SG_ 1570 Checksum_622 3;
BA_ "GenSigFuncType" SG_ 1570 MessageCounter_622 1;
BA_ "GenSigStartValue" SG_ 1043 DC_MaxCurrentLV2 1023;
BA_ "GenSigFuncType" SG_ 1043 Checksum_413 3;
BA_ "GenSigFuncType" SG_ 1043 MessageCounter_413 1;
BA_ "GenSigFuncType" SG_ 1026 Checksum_402 3;
BA_ "GenSigFuncType" SG_ 1026 MessageCounter_402 1;
BA_ "GenSigStartValue" SG_ 264 DesiredSpeed3 65534;
BA_ "GenSigStartValue" SG_ 264 DesiredTorque3 2046;
BA_ "GenSigStartValue" SG_ 264 UdcSetP3 1022;
BA_ "GenSigFuncType" SG_ 264 Checksum_108 3;
BA_ "GenSigFuncType" SG_ 264 MessageCounter_108 1;
BA_ "GenSigStartValue" SG_ 264 StHvbMaiRly3 6;
BA_ "GenSigFuncType" SG_ 308 MessageCounter_134 1;
BA_ "GenSigFuncType" SG_ 308 Checksum_134 3;
BA_ "GenSigStartValue" SG_ 308 VoltageDemandLV3 510;
BA_ "GenSigStartValue" SG_ 308 VoltageDemandHV3 1022;
BA_ "GenSigStartValue" SG_ 308 CurrentDemandLV3 2046;
BA_ "GenSigStartValue" SG_ 308 CurrentDemandHV3 2046;
BA_ "GenSigStartValue" SG_ 780 UdcMin3 1022;
BA_ "GenSigStartValue" SG_ 780 UdcMax3 1022;
BA_ "GenSigStartValue" SG_ 780 IdcMin3 2046;
BA_ "GenSigStartValue" SG_ 780 IdcMax3 2046;
BA_ "GenSigFuncType" SG_ 780 MessageCounter_30C 1;
BA_ "GenSigFuncType" SG_ 780 Checksum_30C 3;
BA_ "GenSigStartValue" SG_ 782 KI_Faktor3 32766;
BA_ "GenSigFuncType" SG_ 782 MessageCounter_30E 1;
BA_ "GenSigFuncType" SG_ 782 Checksum_30E 3;
BA_ "GenSigStartValue" SG_ 782 MinTorqueLimit3 2046;
BA_ "GenSigStartValue" SG_ 782 MaxTorqueLimit3 2046;
BA_ "GenSigStartValue" SG_ 782 MaxTorqueGradient3 32766;
BA_ "GenSigStartValue" SG_ 520 CurrentHV3 1023;
BA_ "GenSigStartValue" SG_ 520 OutputTorque3 2046;
BA_ "GenSigStartValue" SG_ 520 Speed3 65534;
BA_ "GenSigFuncType" SG_ 520 Checksum_208 3;
BA_ "GenSigFuncType" SG_ 520 MessageCounter_208 1;
BA_ "GenSigStartValue" SG_ 532 MaxTorque3 1023;
BA_ "GenSigStartValue" SG_ 532 MinTorque3 1023;
BA_ "GenSigFuncType" SG_ 532 Checksum_214 3;
BA_ "GenSigFuncType" SG_ 532 MessageCounter_214 1;
BA_ "GenSigStartValue" SG_ 532 TrqCurrWoDstC3 1023;
BA_ "GenSigStartValue" SG_ 532 TempCurrCool3 254;
BA_ "GenSigStartValue" SG_ 548 CurrentLV3 1023;
BA_ "GenSigStartValue" SG_ 548 DcCurrentHV3 1024;
BA_ "GenSigStartValue" SG_ 548 TempCurr3 254;
BA_ "GenSigFuncType" SG_ 548 Checksum_224 3;
BA_ "GenSigFuncType" SG_ 548 MessageCounter_224 1;
BA_ "GenSigStartValue" SG_ 1572 ElectricMachineTemperature3 254;
BA_ "GenSigStartValue" SG_ 1572 InverterTemperature3 254;
BA_ "GenSigStartValue" SG_ 1572 TempCurrRotor3 254;
BA_ "GenSigFuncType" SG_ 1572 Checksum_624 3;
BA_ "GenSigFuncType" SG_ 1572 MessageCounter_624 1;
BA_ "GenSigStartValue" SG_ 1045 DC_MaxCurrentLV3 1023;
BA_ "GenSigFuncType" SG_ 1045 Checksum_415 3;
BA_ "GenSigFuncType" SG_ 1045 MessageCounter_415 1;
BA_ "GenSigFuncType" SG_ 1028 Checksum_404 3;
BA_ "GenSigFuncType" SG_ 1028 MessageCounter_404 1;
BA_ "GenSigStartValue" SG_ 266 DesiredSpeed4 65534;
BA_ "GenSigStartValue" SG_ 266 DesiredTorque4 2046;
BA_ "GenSigStartValue" SG_ 266 UdcSetP4 1022;
BA_ "GenSigFuncType" SG_ 266 Checksum_10A 3;
BA_ "GenSigFuncType" SG_ 266 MessageCounter_10A 1;
BA_ "GenSigStartValue" SG_ 266 StHvbMaiRly4 6;
BA_ "GenSigFuncType" SG_ 310 MessageCounter_136 1;
BA_ "GenSigFuncType" SG_ 310 Checksum_136 3;
BA_ "GenSigStartValue" SG_ 310 VoltageDemandLV4 510;
BA_ "GenSigStartValue" SG_ 310 VoltageDemandHV4 1022;
BA_ "GenSigStartValue" SG_ 310 CurrentDemandLV4 2046;
BA_ "GenSigStartValue" SG_ 310 CurrentDemandHV4 2046;
BA_ "GenSigStartValue" SG_ 784 UdcMin4 1022;
BA_ "GenSigStartValue" SG_ 784 UdcMax4 1022;
BA_ "GenSigStartValue" SG_ 784 IdcMin4 2046;
BA_ "GenSigStartValue" SG_ 784 IdcMax4 2046;
BA_ "GenSigFuncType" SG_ 784 MessageCounter_310 1;
BA_ "GenSigFuncType" SG_ 784 Checksum_310 3;
BA_ "GenSigStartValue" SG_ 786 KI_Faktor4 32766;
BA_ "GenSigFuncType" SG_ 786 MessageCounter_312 1;
BA_ "GenSigFuncType" SG_ 786 Checksum_312 3;
BA_ "GenSigStartValue" SG_ 786 MinTorqueLimit4 2046;
BA_ "GenSigStartValue" SG_ 786 MaxTorqueLimit4 2046;
BA_ "GenSigStartValue" SG_ 786 MaxTorqueGradient4 32766;
BA_ "GenSigStartValue" SG_ 522 CurrentHV4 1023;
BA_ "GenSigStartValue" SG_ 522 OutputTorque4 2046;
BA_ "GenSigStartValue" SG_ 522 Speed4 65534;
BA_ "GenSigFuncType" SG_ 522 Checksum_20A 3;
BA_ "GenSigFuncType" SG_ 522 MessageCounter_20A 1;
BA_ "GenSigStartValue" SG_ 534 MaxTorque4 1023;
BA_ "GenSigStartValue" SG_ 534 MinTorque4 1023;
BA_ "GenSigFuncType" SG_ 534 Checksum_216 3;
BA_ "GenSigFuncType" SG_ 534 MessageCounter_216 1;
BA_ "GenSigStartValue" SG_ 534 TrqCurrWoDstC4 1023;
BA_ "GenSigStartValue" SG_ 534 TempCurrCool4 254;
BA_ "GenSigStartValue" SG_ 550 CurrentLV4 1023;
BA_ "GenSigStartValue" SG_ 550 DcCurrentHV4 1024;
BA_ "GenSigStartValue" SG_ 550 TempCurr4 254;
BA_ "GenSigFuncType" SG_ 550 Checksum_226 3;
BA_ "GenSigFuncType" SG_ 550 MessageCounter_226 1;
BA_ "GenSigStartValue" SG_ 1574 ElectricMachineTemperature4 254;
BA_ "GenSigStartValue" SG_ 1574 InverterTemperature4 254;
BA_ "GenSigStartValue" SG_ 1574 TempCurrRotor4 254;
BA_ "GenSigFuncType" SG_ 1574 Checksum_626 3;
BA_ "GenSigFuncType" SG_ 1574 MessageCounter_626 1;
BA_ "GenSigStartValue" SG_ 1047 DC_MaxCurrentLV4 1023;
BA_ "GenSigFuncType" SG_ 1047 Checksum_417 3;
BA_ "GenSigFuncType" SG_ 1047 MessageCounter_417 1;
BA_ "GenSigFuncType" SG_ 1030 Checksum_406 3;
BA_ "GenSigFuncType" SG_ 1030 MessageCounter_406 1;
BA_ "GenSigStartValue" SG_ 268 DesiredSpeed5 65534;
BA_ "GenSigStartValue" SG_ 268 DesiredTorque5 2046;
BA_ "GenSigStartValue" SG_ 268 UdcSetP5 1022;
BA_ "GenSigFuncType" SG_ 268 Checksum_10C 3;
BA_ "GenSigFuncType" SG_ 268 MessageCounter_10C 1;
BA_ "GenSigStartValue" SG_ 268 StHvbMaiRly5 6;
BA_ "GenSigFuncType" SG_ 312 MessageCounter_138 1;
BA_ "GenSigFuncType" SG_ 312 Checksum_138 3;
BA_ "GenSigStartValue" SG_ 312 VoltageDemandLV5 510;
BA_ "GenSigStartValue" SG_ 312 VoltageDemandHV5 1022;
BA_ "GenSigStartValue" SG_ 312 CurrentDemandLV5 2046;
BA_ "GenSigStartValue" SG_ 312 CurrentDemandHV5 2046;
BA_ "GenSigStartValue" SG_ 788 UdcMin5 1022;
BA_ "GenSigStartValue" SG_ 788 UdcMax5 1022;
BA_ "GenSigStartValue" SG_ 788 IdcMin5 2046;
BA_ "GenSigStartValue" SG_ 788 IdcMax5 2046;
BA_ "GenSigFuncType" SG_ 788 MessageCounter_314 1;
BA_ "GenSigFuncType" SG_ 788 Checksum_314 3;
BA_ "GenSigStartValue" SG_ 790 KI_Faktor5 32766;
BA_ "GenSigFuncType" SG_ 790 MessageCounter_316 1;
BA_ "GenSigFuncType" SG_ 790 Checksum_316 3;
BA_ "GenSigStartValue" SG_ 790 MinTorqueLimit5 2046;
BA_ "GenSigStartValue" SG_ 790 MaxTorqueLimit5 2046;
BA_ "GenSigStartValue" SG_ 790 MaxTorqueGradient5 32766;
BA_ "GenSigStartValue" SG_ 1757 DIAG_Day 1;
BA_ "GenSigStartValue" SG_ 1757 DIAG_Month 1;
BA_ "GenSigStartValue" SG_ 524 CurrentHV5 1023;
BA_ "GenSigStartValue" SG_ 524 OutputTorque5 2046;
BA_ "GenSigStartValue" SG_ 524 Speed5 65534;
BA_ "GenSigFuncType" SG_ 524 Checksum_20C 3;
BA_ "GenSigFuncType" SG_ 524 MessageCounter_20C 1;
BA_ "GenSigStartValue" SG_ 536 MaxTorque5 1023;
BA_ "GenSigStartValue" SG_ 536 MinTorque5 1023;
BA_ "GenSigFuncType" SG_ 536 Checksum_218 3;
BA_ "GenSigFuncType" SG_ 536 MessageCounter_218 1;
BA_ "GenSigStartValue" SG_ 536 TrqCurrWoDstC5 1023;
BA_ "GenSigStartValue" SG_ 536 TempCurrCool5 254;
BA_ "GenSigStartValue" SG_ 552 CurrentLV5 1023;
BA_ "GenSigStartValue" SG_ 552 DcCurrentHV5 1024;
BA_ "GenSigStartValue" SG_ 552 TempCurr5 254;
BA_ "GenSigFuncType" SG_ 552 Checksum_228 3;
BA_ "GenSigFuncType" SG_ 552 MessageCounter_228 1;
BA_ "GenSigStartValue" SG_ 1576 ElectricMachineTemperature5 254;
BA_ "GenSigStartValue" SG_ 1576 InverterTemperature5 254;
BA_ "GenSigStartValue" SG_ 1576 TempCurrRotor5 254;
BA_ "GenSigFuncType" SG_ 1576 Checksum_628 3;
BA_ "GenSigFuncType" SG_ 1576 MessageCounter_628 1;
BA_ "GenSigStartValue" SG_ 1049 DC_MaxCurrentLV5 1023;
BA_ "GenSigFuncType" SG_ 1049 Checksum_419 3;
BA_ "GenSigFuncType" SG_ 1049 MessageCounter_419 1;
BA_ "GenSigFuncType" SG_ 1032 Checksum_408 3;
BA_ "GenSigFuncType" SG_ 1032 MessageCounter_408 1;
VAL_ 292 SurgeDamperTreshold5 1023 "Error" 1022 "Init" ;
VAL_ 292 SurgeDamperState5 2 "DstC_int_ext" 1 "DstC_ext" 0 "DstC_off" ;
VAL_ 292 SurgeDamperMaxTorque5 1023 "Error" 1022 "Init" ;
VAL_ 292 SurgeDamperFactor5 255 "Error" 254 "Init" ;
VAL_ 291 SurgeDamperTreshold4 1023 "Error" 1022 "Init" ;
VAL_ 291 SurgeDamperState4 2 "DstC_int_ext" 1 "DstC_ext" 0 "DstC_off" ;
VAL_ 291 SurgeDamperMaxTorque4 1023 "Error" 1022 "Init" ;
VAL_ 291 SurgeDamperFactor4 255 "Error" 254 "Init" ;
VAL_ 290 SurgeDamperTreshold3 1023 "Error" 1022 "Init" ;
VAL_ 290 SurgeDamperState3 2 "DstC_int_ext" 1 "DstC_ext" 0 "DstC_off" ;
VAL_ 290 SurgeDamperMaxTorque3 1023 "Error" 1022 "Init" ;
VAL_ 290 SurgeDamperFactor3 255 "Error" 254 "Init" ;
VAL_ 289 SurgeDamperTreshold2 1023 "Error" 1022 "Init" ;
VAL_ 289 SurgeDamperState2 2 "DstC_int_ext" 1 "DstC_ext" 0 "DstC_off" ;
VAL_ 289 SurgeDamperMaxTorque2 1023 "Error" 1022 "Init" ;
VAL_ 289 SurgeDamperFactor2 255 "Error" 254 "Init" ;
VAL_ 288 SurgeDamperTreshold1 1023 "Error" 1022 "Init" ;
VAL_ 288 SurgeDamperState1 2 "DstC_int_ext" 1 "DstC_ext" 0 "DstC_off" ;
VAL_ 288 SurgeDamperMaxTorque1 1023 "Error" 1022 "Init" ;
VAL_ 288 SurgeDamperFactor1 255 "Error" 254 "Init" ;
VAL_ 1663 INV0_FailCode4 0 "NoError" ;
VAL_ 1663 INV0_FailCode3 0 "NoError" ;
VAL_ 1663 INV0_FailCode2 0 "NoError" ;
VAL_ 1663 INV0_FailCode1 0 "NoError" ;
VAL_ 1668 INV5_FailCode4 0 "NoError" ;
VAL_ 1668 INV5_FailCode3 0 "NoError" ;
VAL_ 1668 INV5_FailCode2 0 "NoError" ;
VAL_ 1668 INV5_FailCode1 0 "NoError" ;
VAL_ 1667 INV4_FailCode4 0 "NoError" ;
VAL_ 1667 INV4_FailCode3 0 "NoError" ;
VAL_ 1667 INV4_FailCode2 0 "NoError" ;
VAL_ 1667 INV4_FailCode1 0 "NoError" ;
VAL_ 1666 INV3_FailCode4 0 "NoError" ;
VAL_ 1666 INV3_FailCode3 0 "NoError" ;
VAL_ 1666 INV3_FailCode2 0 "NoError" ;
VAL_ 1666 INV3_FailCode1 0 "NoError" ;
VAL_ 1665 INV2_FailCode4 0 "NoError" ;
VAL_ 1665 INV2_FailCode3 0 "NoError" ;
VAL_ 1665 INV2_FailCode2 0 "NoError" ;
VAL_ 1665 INV2_FailCode1 0 "NoError" ;
VAL_ 1664 INV1_FailCode4 0 "NoError" ;
VAL_ 1664 INV1_FailCode3 0 "NoError" ;
VAL_ 1664 INV1_FailCode2 0 "NoError" ;
VAL_ 1664 INV1_FailCode1 0 "NoError" ;
VAL_ 789 Checksum_315 0 "Init" ;
VAL_ 789 MessageCounter_315 0 "Init" ;
VAL_ 789 MaxTorqueEngineSpeed5 2047 "Error" 2046 "Init" ;
VAL_ 789 MinTorqueEngineSpeed5 2047 "Error" 2046 "Init" ;
VAL_ 789 MaxDeltaSpeed5 4095 "Error" 4094 "Init" ;
VAL_ 789 FactorPContributionSmall5 511 "Error" 510 "Init" ;
VAL_ 789 FactorPContributionLarge5 511 "Error" 510 "Init" ;
VAL_ 785 Checksum_311 0 "Init" ;
VAL_ 785 MessageCounter_311 0 "Init" ;
VAL_ 785 MaxTorqueEngineSpeed4 2047 "Error" 2046 "Init" ;
VAL_ 785 MinTorqueEngineSpeed4 2047 "Error" 2046 "Init" ;
VAL_ 785 MaxDeltaSpeed4 4095 "Error" 4094 "Init" ;
VAL_ 785 FactorPContributionSmall4 511 "Error" 510 "Init" ;
VAL_ 785 FactorPContributionLarge4 511 "Error" 510 "Init" ;
VAL_ 781 Checksum_30D 0 "Init" ;
VAL_ 781 MessageCounter_30D 0 "Init" ;
VAL_ 781 MaxTorqueEngineSpeed3 2047 "Error" 2046 "Init" ;
VAL_ 781 MinTorqueEngineSpeed3 2047 "Error" 2046 "Init" ;
VAL_ 781 MaxDeltaSpeed3 4095 "Error" 4094 "Init" ;
VAL_ 781 FactorPContributionSmall3 511 "Error" 510 "Init" ;
VAL_ 781 FactorPContributionLarge3 511 "Error" 510 "Init" ;
VAL_ 777 Checksum_309 0 "Init" ;
VAL_ 777 MessageCounter_309 0 "Init" ;
VAL_ 777 MaxTorqueEngineSpeed2 2047 "Error" 2046 "Init" ;
VAL_ 777 MinTorqueEngineSpeed2 2047 "Error" 2046 "Init" ;
VAL_ 777 MaxDeltaSpeed2 4095 "Error" 4094 "Init" ;
VAL_ 777 FactorPContributionSmall2 511 "Error" 510 "Init" ;
VAL_ 777 FactorPContributionLarge2 511 "Error" 510 "Init" ;
VAL_ 773 Checksum_305 0 "Init" ;
VAL_ 773 MessageCounter_305 0 "Init" ;
VAL_ 773 MaxTorqueEngineSpeed1 2047 "Error" 2046 "Init" ;
VAL_ 773 MinTorqueEngineSpeed1 2047 "Error" 2046 "Init" ;
VAL_ 773 MaxDeltaSpeed1 4095 "Error" 4094 "Init" ;
VAL_ 773 FactorPContributionSmall1 511 "Error" 510 "Init" ;
VAL_ 773 FactorPContributionLarge1 511 "Error" 510 "Init" ;
VAL_ 260 RequestedState1 0 "Init" 3 "Standby" 4 "UdcCtrl" 5 "AlOffsetCal" 6 "nCtlExt" 7 "NCtlInt" 8 "TrqCtrl" 10 "UdcCtlBatt" 14 "Discharge" 15 "FwCtl" ;
VAL_ 260 DesiredSpeed1 65534 "Init" 65535 "Error" ;
VAL_ 260 DesiredTorque1 2047 "Error" 2046 "Init" ;
VAL_ 260 UdcSetP1 1022 "Init" 1023 "Error" ;
VAL_ 260 Checksum_104 0 "Init" ;
VAL_ 260 MessageCounter_104 0 "Init" ;
VAL_ 260 StHvbMaiRly1 0 "Opened" 1 "Closed" 2 "PreCharge" 3 "BatteryFailure" 4 "-" 5 "-" 6 "Init" 7 "Failure" ;
VAL_ 304 MessageCounter_130 0 "Init" ;
VAL_ 304 Checksum_130 0 "Init" ;
VAL_ 304 VoltageDemandLV1 510 "Init" 511 "Error" ;
VAL_ 304 VoltageDemandHV1 1022 "Init" 1023 "Error" ;
VAL_ 304 ModeRequest1 0 "OFF" 1 "Buck" ;
VAL_ 304 CurrentDemandLV1 2046 "Init" 2047 "Error" ;
VAL_ 304 CurrentDemandHV1 2046 "Init" 2047 "Error" ;
VAL_ 772 UdcMin1 1022 "Init" 1023 "Error" ;
VAL_ 772 UdcMax1 1022 "Init" 1023 "Error" ;
VAL_ 772 IdcMin1 2046 "Init" 2047 "Error" ;
VAL_ 772 IdcMax1 2046 "Init" 2047 "Error" ;
VAL_ 772 MessageCounter_304 0 "Init" ;
VAL_ 772 Checksum_304 0 "Init" ;
VAL_ 772 flgInvrCanActvnCmd1 1 "INV1 communication demand - ON" 0 "INV1 communication demand - OFF" ;
VAL_ 774 KI_Faktor1 32766 "Init" 32767 "Error" ;
VAL_ 774 MessageCounter_306 0 "Init" ;
VAL_ 774 Checksum_306 0 "Init" ;
VAL_ 774 MinTorqueLimit1 2046 "Init" 2047 "Error" ;
VAL_ 774 MaxTorqueLimit1 2046 "Init" 2047 "Error" ;
VAL_ 774 MaxTorqueGradient1 32766 "Init" 32767 "Error" ;
VAL_ 516 CurrentHV1 1023 "Init" ;
VAL_ 516 OutputTorque1 2047 "Failure" 2046 "Init" ;
VAL_ 516 State1 0 "Init" 1 "DrvInit" 3 "Standby" 4 "UdcCtl" 5 "AlOffsetCal" 6 "NCtlExt" 7 "NCtlInt" 8 "TrqCtl" 10 "UdcCtlBatt" 11 "Afterrun" 13 "Failure" 14 "Discharge" 15 "FwCtl" ;
VAL_ 516 Speed1 65534 "Init" 65535 "Error" ;
VAL_ 516 Checksum_204 0 "Init" ;
VAL_ 516 MessageCounter_204 0 "Init" ;
VAL_ 528 dataInvrNr1 5 "Inverter5" 4 "Inverter4" 3 "Inverter3" 2 "Inverter2" 1 "Inverter1" 0 "Not configured" ;
VAL_ 528 MaxTorque1 1023 "Init" ;
VAL_ 528 MinTorque1 1023 "Init" ;
VAL_ 528 Checksum_210 0 "Init" ;
VAL_ 528 MessageCounter_210 0 "Init" ;
VAL_ 528 TrqCurrWoDstC1 1023 "Init" ;
VAL_ 528 TempCurrCool1 254 "Init" 255 "Error" ;
VAL_ 544 Mode1 0 "Off" 1 "Buck" 5 "Failure" ;
VAL_ 544 CurrentLV1 1023 "Init" ;
VAL_ 544 VoltageLV1 0 "Init" ;
VAL_ 544 DcCurrentHV1 1024 "Init" ;
VAL_ 544 VoltageHV1 0 "Init" ;
VAL_ 544 TempCurr1 254 "Init" 255 "Error" ;
VAL_ 544 Checksum_220 0 "Init" ;
VAL_ 544 MessageCounter_220 0 "Init" ;
VAL_ 1568 ElectricMachineTemperature1 254 "Init" 255 "Error" ;
VAL_ 1568 InverterTemperature1 254 "Init" 255 "Error" ;
VAL_ 1568 UT30Curr1 0 "Init" ;
VAL_ 1568 TempCurrRotor1 254 "Init" 255 "Error" ;
VAL_ 1568 Checksum_620 0 "Init" ;
VAL_ 1568 MessageCounter_620 0 "Init" ;
VAL_ 1041 DC_MaxCurrentLV1 1023 "Init" ;
VAL_ 1041 DC_MaxCurrentHV1 0 "Init" ;
VAL_ 1041 bDernUndrUdcLV1 0 "Init" ;
VAL_ 1041 ErrShtOff1 0 "Init" ;
VAL_ 1041 bDernOvrIdcLv1 0 "Init" ;
VAL_ 1041 bDernOvrIdcHV1 0 "Init" ;
VAL_ 1041 bDernOvrUdcLv1 0 "Init" ;
VAL_ 1041 bDernUndrUdcHV1 0 "Init" ;
VAL_ 1041 ErrLimitedPerformance1 0 "Init" ;
VAL_ 1041 bDernTemp_DCDC1 0 "Init" ;
VAL_ 1041 bDernOvrUdcHV1 0 "Init" ;
VAL_ 1041 bErrVltg1 0 "Init" ;
VAL_ 1041 Checksum_411 0 "Init" ;
VAL_ 1041 MessageCounter_411 0 "Init" ;
VAL_ 1024 EmergencyShutoffRequest1 0 "NoShutOffRequested" 1 "ShutOffRequested" ;
VAL_ 1024 bDernOvrUdc1 0 "Init" ;
VAL_ 1024 bDernUndrUdc1 0 "Init" ;
VAL_ 1024 Checksum_400 0 "Init" ;
VAL_ 1024 MessageCounter_400 0 "Init" ;
VAL_ 1024 bDernOvrIdc1 0 "Init" ;
VAL_ 1024 bDernUndrIdc1 0 "Init" ;
VAL_ 1024 bDernTemp1 0 "Init" ;
VAL_ 1024 bDiagReq1 0 "Init" ;
VAL_ 1024 bDernTrqMin1 0 "Init" ;
VAL_ 1024 bDernTrqMax1 0 "Init" ;
VAL_ 1024 bDstActv1 0 "Init" ;
VAL_ 1024 bReadyHV1 0 "Init" ;
VAL_ 110 bErrEmergencyDischargeReq 0 "Init" ;
VAL_ 110 MessageCounter_6E 0 "Init" ;
VAL_ 110 Checksum_6E 0 "Init" ;
VAL_ 110 ContactorState 0 "HVBattCntctr_Open" 1 "HVBattCntctr_Closed" 2 "HVBattCntctr_SwitchingOn" 3 "HVBattCntctr_SwitchingOff" 6 "HVBattCntctr_Init" 7 "HVBattCntctr_Failure" ;
VAL_ 110 Current 4094 "Init" 4095 "Error" ;
VAL_ 110 Voltage 4094 "Init" 4095 "Error" ;
VAL_ 262 RequestedState2 0 "Init" 3 "Standby" 4 "UdcCtrl" 5 "AlOffsetCal" 6 "nCtlExt" 7 "NCtlInt" 8 "TrqCtrl" 10 "UdcCtlBatt" 14 "Discharge" 15 "FwCtl" ;
VAL_ 262 DesiredSpeed2 65534 "Init" 65535 "Error" ;
VAL_ 262 DesiredTorque2 2047 "Error" 2046 "Init" ;
VAL_ 262 UdcSetP2 1022 "Init" 1023 "Error" ;
VAL_ 262 Checksum_106 0 "Init" ;
VAL_ 262 MessageCounter_106 0 "Init" ;
VAL_ 262 StHvbMaiRly2 0 "Opened" 1 "Closed" 2 "PreCharge" 3 "BatteryFailure" 4 "-" 5 "-" 6 "Init" 7 "Failure" ;
VAL_ 306 MessageCounter_132 0 "Init" ;
VAL_ 306 Checksum_132 0 "Init" ;
VAL_ 306 VoltageDemandLV2 510 "Init" 511 "Error" ;
VAL_ 306 VoltageDemandHV2 1022 "Init" 1023 "Error" ;
VAL_ 306 ModeRequest2 0 "OFF" 1 "Buck" ;
VAL_ 306 CurrentDemandLV2 2046 "Init" 2047 "Error" ;
VAL_ 306 CurrentDemandHV2 2046 "Init" 2047 "Error" ;
VAL_ 776 UdcMin2 1022 "Init" 1023 "Error" ;
VAL_ 776 UdcMax2 1022 "Init" 1023 "Error" ;
VAL_ 776 IdcMin2 2046 "Init" 2047 "Error" ;
VAL_ 776 IdcMax2 2046 "Init" 2047 "Error" ;
VAL_ 776 MessageCounter_308 0 "Init" ;
VAL_ 776 Checksum_308 0 "Init" ;
VAL_ 776 flgInvrCanActvnCmd2 1 "INV2 communication demand - ON" 0 "INV2 communication demand - OFF" ;
VAL_ 778 KI_Faktor2 32766 "Init" 32767 "Error" ;
VAL_ 778 MessageCounter_30A 0 "Init" ;
VAL_ 778 Checksum_30A 0 "Init" ;
VAL_ 778 MinTorqueLimit2 2046 "Init" 2047 "Error" ;
VAL_ 778 MaxTorqueLimit2 2046 "Init" 2047 "Error" ;
VAL_ 778 MaxTorqueGradient2 32766 "Init" 32767 "Error" ;
VAL_ 518 CurrentHV2 1023 "Init" ;
VAL_ 518 OutputTorque2 2047 "Failure" 2046 "Init" ;
VAL_ 518 State2 0 "Init" 1 "DrvInit" 3 "Standby" 4 "UdcCtl" 5 "AlOffsetCal" 6 "NCtlExt" 7 "NCtlInt" 8 "TrqCtl" 10 "UdcCtlBatt" 11 "Afterrun" 13 "Failure" 14 "Discharge" 15 "FwCtl" ;
VAL_ 518 Speed2 65534 "Init" 65535 "Error" ;
VAL_ 518 Checksum_206 0 "Init" ;
VAL_ 518 MessageCounter_206 0 "Init" ;
VAL_ 530 dataInvrNr2 5 "Inverter5" 4 "Inverter4" 3 "Inverter3" 2 "Inverter2" 1 "Inverter1" 0 "Not configured" ;
VAL_ 530 MaxTorque2 1023 "Init" ;
VAL_ 530 MinTorque2 1023 "Init" ;
VAL_ 530 Checksum_212 0 "Init" ;
VAL_ 530 MessageCounter_212 0 "Init" ;
VAL_ 530 TrqCurrWoDstC2 1023 "Init" ;
VAL_ 530 TempCurrCool2 254 "Init" 255 "Error" ;
VAL_ 546 Mode2 0 "Off" 1 "Buck" 5 "Failure" ;
VAL_ 546 CurrentLV2 1023 "Init" ;
VAL_ 546 VoltageLV2 0 "Init" ;
VAL_ 546 DcCurrentHV2 1024 "Init" ;
VAL_ 546 VoltageHV2 0 "Init" ;
VAL_ 546 TempCurr2 254 "Init" 255 "Error" ;
VAL_ 546 Checksum_222 0 "Init" ;
VAL_ 546 MessageCounter_222 0 "Init" ;
VAL_ 1570 ElectricMachineTemperature2 254 "Init" 255 "Error" ;
VAL_ 1570 InverterTemperature2 254 "Init" 255 "Error" ;
VAL_ 1570 UT30Curr2 0 "Init" ;
VAL_ 1570 TempCurrRotor2 254 "Init" 255 "Error" ;
VAL_ 1570 Checksum_622 0 "Init" ;
VAL_ 1570 MessageCounter_622 0 "Init" ;
VAL_ 1043 DC_MaxCurrentLV2 1023 "Init" ;
VAL_ 1043 DC_MaxCurrentHV2 0 "Init" ;
VAL_ 1043 bDernUndrUdcLV2 0 "Init" ;
VAL_ 1043 ErrShtOff2 0 "Init" ;
VAL_ 1043 bDernOvrIdcLv2 0 "Init" ;
VAL_ 1043 bDernOvrIdcHV2 0 "Init" ;
VAL_ 1043 bDernOvrUdcLv2 0 "Init" ;
VAL_ 1043 bDernUndrUdcHV2 0 "Init" ;
VAL_ 1043 ErrLimitedPerformance2 0 "Init" ;
VAL_ 1043 bDernTemp_DCDC2 0 "Init" ;
VAL_ 1043 bDernOvrUdcHV2 0 "Init" ;
VAL_ 1043 bErrVltg2 0 "Init" ;
VAL_ 1043 Checksum_413 0 "Init" ;
VAL_ 1043 MessageCounter_413 0 "Init" ;
VAL_ 1026 EmergencyShutoffRequest2 0 "NoShutOffRequested" 1 "ShutOffRequested" ;
VAL_ 1026 bDernOvrUdc2 0 "Init" ;
VAL_ 1026 bDernUndrUdc2 0 "Init" ;
VAL_ 1026 Checksum_402 0 "Init" ;
VAL_ 1026 MessageCounter_402 0 "Init" ;
VAL_ 1026 bDernOvrIdc2 0 "Init" ;
VAL_ 1026 bDernUndrIdc2 0 "Init" ;
VAL_ 1026 bDernTemp2 0 "Init" ;
VAL_ 1026 bDiagReq2 0 "Init" ;
VAL_ 1026 bDernTrqMin2 0 "Init" ;
VAL_ 1026 bDernTrqMax2 0 "Init" ;
VAL_ 1026 bDstActv2 0 "Init" ;
VAL_ 1026 bReadyHV2 0 "Init" ;
VAL_ 264 RequestedState3 0 "Init" 3 "Standby" 4 "UdcCtrl" 5 "AlOffsetCal" 6 "nCtlExt" 7 "NCtlInt" 8 "TrqCtrl" 10 "UdcCtlBatt" 14 "Discharge" 15 "FwCtl" ;
VAL_ 264 DesiredSpeed3 65534 "Init" 65535 "Error" ;
VAL_ 264 DesiredTorque3 2047 "Error" 2046 "Init" ;
VAL_ 264 UdcSetP3 1022 "Init" 1023 "Error" ;
VAL_ 264 Checksum_108 0 "Init" ;
VAL_ 264 MessageCounter_108 0 "Init" ;
VAL_ 264 StHvbMaiRly3 0 "Opened" 1 "Closed" 2 "PreCharge" 3 "BatteryFailure" 4 "-" 5 "-" 6 "Init" 7 "Failure" ;
VAL_ 308 MessageCounter_134 0 "Init" ;
VAL_ 308 Checksum_134 0 "Init" ;
VAL_ 308 VoltageDemandLV3 510 "Init" 511 "Error" ;
VAL_ 308 VoltageDemandHV3 1022 "Init" 1023 "Error" ;
VAL_ 308 ModeRequest3 0 "OFF" 1 "Buck" ;
VAL_ 308 CurrentDemandLV3 2046 "Init" 2047 "Error" ;
VAL_ 308 CurrentDemandHV3 2046 "Init" 2047 "Error" ;
VAL_ 780 UdcMin3 1022 "Init" 1023 "Error" ;
VAL_ 780 UdcMax3 1022 "Init" 1023 "Error" ;
VAL_ 780 IdcMin3 2046 "Init" 2047 "Error" ;
VAL_ 780 IdcMax3 2046 "Init" 2047 "Error" ;
VAL_ 780 MessageCounter_30C 0 "Init" ;
VAL_ 780 Checksum_30C 0 "Init" ;
VAL_ 780 flgInvrCanActvnCmd3 1 "INV3 communication demand - ON" 0 "INV3 communication demand - OFF" ;
VAL_ 782 KI_Faktor3 32766 "Init" 32767 "Error" ;
VAL_ 782 MessageCounter_30E 0 "Init" ;
VAL_ 782 Checksum_30E 0 "Init" ;
VAL_ 782 MinTorqueLimit3 2046 "Init" 2047 "Error" ;
VAL_ 782 MaxTorqueLimit3 2046 "Init" 2047 "Error" ;
VAL_ 782 MaxTorqueGradient3 32766 "Init" 32767 "Error" ;
VAL_ 520 CurrentHV3 1023 "Init" ;
VAL_ 520 OutputTorque3 2047 "Failure" 2046 "Init" ;
VAL_ 520 State3 0 "Init" 1 "DrvInit" 3 "Standby" 4 "UdcCtl" 5 "AlOffsetCal" 6 "NCtlExt" 7 "NCtlInt" 8 "TrqCtl" 10 "UdcCtlBatt" 11 "Afterrun" 13 "Failure" 14 "Discharge" 15 "FwCtl" ;
VAL_ 520 Speed3 65534 "Init" 65535 "Error" ;
VAL_ 520 Checksum_208 0 "Init" ;
VAL_ 520 MessageCounter_208 0 "Init" ;
VAL_ 532 dataInvrNr3 5 "Inverter5" 4 "Inverter4" 3 "Inverter3" 2 "Inverter2" 1 "Inverter1" 0 "Not configured" ;
VAL_ 532 MaxTorque3 1023 "Init" ;
VAL_ 532 MinTorque3 1023 "Init" ;
VAL_ 532 Checksum_214 0 "Init" ;
VAL_ 532 MessageCounter_214 0 "Init" ;
VAL_ 532 TrqCurrWoDstC3 1023 "Init" ;
VAL_ 532 TempCurrCool3 254 "Init" 255 "Error" ;
VAL_ 548 Mode3 0 "Off" 1 "Buck" 5 "Failure" ;
VAL_ 548 CurrentLV3 1023 "Init" ;
VAL_ 548 VoltageLV3 0 "Init" ;
VAL_ 548 DcCurrentHV3 1024 "Init" ;
VAL_ 548 VoltageHV3 0 "Init" ;
VAL_ 548 TempCurr3 254 "Init" 255 "Error" ;
VAL_ 548 Checksum_224 0 "Init" ;
VAL_ 548 MessageCounter_224 0 "Init" ;
VAL_ 1572 ElectricMachineTemperature3 254 "Init" 255 "Error" ;
VAL_ 1572 InverterTemperature3 254 "Init" 255 "Error" ;
VAL_ 1572 UT30Curr3 0 "Init" ;
VAL_ 1572 TempCurrRotor3 254 "Init" 255 "Error" ;
VAL_ 1572 Checksum_624 0 "Init" ;
VAL_ 1572 MessageCounter_624 0 "Init" ;
VAL_ 1045 DC_MaxCurrentLV3 1023 "Init" ;
VAL_ 1045 DC_MaxCurrentHV3 0 "Init" ;
VAL_ 1045 bDernUndrUdcLV3 0 "Init" ;
VAL_ 1045 ErrShtOff3 0 "Init" ;
VAL_ 1045 bDernOvrIdcLv3 0 "Init" ;
VAL_ 1045 bDernOvrIdcHV3 0 "Init" ;
VAL_ 1045 bDernOvrUdcLv3 0 "Init" ;
VAL_ 1045 bDernUndrUdcHV3 0 "Init" ;
VAL_ 1045 ErrLimitedPerformance3 0 "Init" ;
VAL_ 1045 bDernTemp_DCDC3 0 "Init" ;
VAL_ 1045 bDernOvrUdcHV3 0 "Init" ;
VAL_ 1045 bErrVltg3 0 "Init" ;
VAL_ 1045 Checksum_415 0 "Init" ;
VAL_ 1045 MessageCounter_415 0 "Init" ;
VAL_ 1028 EmergencyShutoffRequest3 0 "NoShutOffRequested" 1 "ShutOffRequested" ;
VAL_ 1028 bDernOvrUdc3 0 "Init" ;
VAL_ 1028 bDernUndrUdc3 0 "Init" ;
VAL_ 1028 Checksum_404 0 "Init" ;
VAL_ 1028 MessageCounter_404 0 "Init" ;
VAL_ 1028 bDernOvrIdc3 0 "Init" ;
VAL_ 1028 bDernUndrIdc3 0 "Init" ;
VAL_ 1028 bDernTemp3 0 "Init" ;
VAL_ 1028 bDiagReq3 0 "Init" ;
VAL_ 1028 bDernTrqMin3 0 "Init" ;
VAL_ 1028 bDernTrqMax3 0 "Init" ;
VAL_ 1028 bDstActv3 0 "Init" ;
VAL_ 1028 bReadyHV3 0 "Init" ;
VAL_ 266 RequestedState4 0 "Init" 3 "Standby" 4 "UdcCtrl" 5 "AlOffsetCal" 6 "nCtlExt" 7 "NCtlInt" 8 "TrqCtrl" 10 "UdcCtlBatt" 14 "Discharge" 15 "FwCtl" ;
VAL_ 266 DesiredSpeed4 65534 "Init" 65535 "Error" ;
VAL_ 266 DesiredTorque4 2047 "Error" 2046 "Init" ;
VAL_ 266 UdcSetP4 1022 "Init" 1023 "Error" ;
VAL_ 266 Checksum_10A 0 "Init" ;
VAL_ 266 MessageCounter_10A 0 "Init" ;
VAL_ 266 StHvbMaiRly4 0 "Opened" 1 "Closed" 2 "PreCharge" 3 "BatteryFailure" 4 "-" 5 "-" 6 "Init" 7 "Failure" ;
VAL_ 310 MessageCounter_136 0 "Init" ;
VAL_ 310 Checksum_136 0 "Init" ;
VAL_ 310 VoltageDemandLV4 510 "Init" 511 "Error" ;
VAL_ 310 VoltageDemandHV4 1022 "Init" 1023 "Error" ;
VAL_ 310 ModeRequest4 0 "OFF" 1 "Buck" ;
VAL_ 310 CurrentDemandLV4 2046 "Init" 2047 "Error" ;
VAL_ 310 CurrentDemandHV4 2046 "Init" 2047 "Error" ;
VAL_ 784 UdcMin4 1022 "Init" 1023 "Error" ;
VAL_ 784 UdcMax4 1022 "Init" 1023 "Error" ;
VAL_ 784 IdcMin4 2046 "Init" 2047 "Error" ;
VAL_ 784 IdcMax4 2046 "Init" 2047 "Error" ;
VAL_ 784 MessageCounter_310 0 "Init" ;
VAL_ 784 Checksum_310 0 "Init" ;
VAL_ 784 flgInvrCanActvnCmd4 1 "INV4 communication demand - ON" 0 "INV4 communication demand - OFF" ;
VAL_ 786 KI_Faktor4 32766 "Init" 32767 "Error" ;
VAL_ 786 MessageCounter_312 0 "Init" ;
VAL_ 786 Checksum_312 0 "Init" ;
VAL_ 786 MinTorqueLimit4 2046 "Init" 2047 "Error" ;
VAL_ 786 MaxTorqueLimit4 2046 "Init" 2047 "Error" ;
VAL_ 786 MaxTorqueGradient4 32766 "Init" 32767 "Error" ;
VAL_ 522 CurrentHV4 1023 "Init" ;
VAL_ 522 OutputTorque4 2047 "Failure" 2046 "Init" ;
VAL_ 522 State4 0 "Init" 1 "DrvInit" 3 "Standby" 4 "UdcCtl" 5 "AlOffsetCal" 6 "NCtlExt" 7 "NCtlInt" 8 "TrqCtl" 10 "UdcCtlBatt" 11 "Afterrun" 13 "Failure" 14 "Discharge" 15 "FwCtl" ;
VAL_ 522 Speed4 65534 "Init" 65535 "Error" ;
VAL_ 522 Checksum_20A 0 "Init" ;
VAL_ 522 MessageCounter_20A 0 "Init" ;
VAL_ 534 dataInvrNr4 5 "Inverter5" 4 "Inverter4" 3 "Inverter3" 2 "Inverter2" 1 "Inverter1" 0 "Not configured" ;
VAL_ 534 MaxTorque4 1023 "Init" ;
VAL_ 534 MinTorque4 1023 "Init" ;
VAL_ 534 Checksum_216 0 "Init" ;
VAL_ 534 MessageCounter_216 0 "Init" ;
VAL_ 534 TrqCurrWoDstC4 1023 "Init" ;
VAL_ 534 TempCurrCool4 254 "Init" 255 "Error" ;
VAL_ 550 Mode4 0 "Off" 1 "Buck" 5 "Failure" ;
VAL_ 550 CurrentLV4 1023 "Init" ;
VAL_ 550 VoltageLV4 0 "Init" ;
VAL_ 550 DcCurrentHV4 1024 "Init" ;
VAL_ 550 VoltageHV4 0 "Init" ;
VAL_ 550 TempCurr4 254 "Init" 255 "Error" ;
VAL_ 550 Checksum_226 0 "Init" ;
VAL_ 550 MessageCounter_226 0 "Init" ;
VAL_ 1574 ElectricMachineTemperature4 254 "Init" 255 "Error" ;
VAL_ 1574 InverterTemperature4 254 "Init" 255 "Error" ;
VAL_ 1574 UT30Curr4 0 "Init" ;
VAL_ 1574 TempCurrRotor4 254 "Init" 255 "Error" ;
VAL_ 1574 Checksum_626 0 "Init" ;
VAL_ 1574 MessageCounter_626 0 "Init" ;
VAL_ 1047 DC_MaxCurrentLV4 1023 "Init" ;
VAL_ 1047 DC_MaxCurrentHV4 0 "Init" ;
VAL_ 1047 bDernUndrUdcLV4 0 "Init" ;
VAL_ 1047 ErrShtOff4 0 "Init" ;
VAL_ 1047 bDernOvrIdcLv4 0 "Init" ;
VAL_ 1047 bDernOvrIdcHV4 0 "Init" ;
VAL_ 1047 bDernOvrUdcLv4 0 "Init" ;
VAL_ 1047 bDernUndrUdcHV4 0 "Init" ;
VAL_ 1047 ErrLimitedPerformance4 0 "Init" ;
VAL_ 1047 bDernTemp_DCDC4 0 "Init" ;
VAL_ 1047 bDernOvrUdcHV4 0 "Init" ;
VAL_ 1047 bErrVltg4 0 "Init" ;
VAL_ 1047 Checksum_417 0 "Init" ;
VAL_ 1047 MessageCounter_417 0 "Init" ;
VAL_ 1030 EmergencyShutoffRequest4 0 "NoShutOffRequested" 1 "ShutOffRequested" ;
VAL_ 1030 bDernOvrUdc4 0 "Init" ;
VAL_ 1030 bDernUndrUdc4 0 "Init" ;
VAL_ 1030 Checksum_406 0 "Init" ;
VAL_ 1030 MessageCounter_406 0 "Init" ;
VAL_ 1030 bDernOvrIdc4 0 "Init" ;
VAL_ 1030 bDernUndrIdc4 0 "Init" ;
VAL_ 1030 bDernTemp4 0 "Init" ;
VAL_ 1030 bDiagReq4 0 "Init" ;
VAL_ 1030 bDernTrqMin4 0 "Init" ;
VAL_ 1030 bDernTrqMax4 0 "Init" ;
VAL_ 1030 bDstActv4 0 "Init" ;
VAL_ 1030 bReadyHV4 0 "Init" ;
VAL_ 268 RequestedState5 0 "Init" 3 "Standby" 4 "UdcCtrl" 5 "AlOffsetCal" 6 "nCtlExt" 7 "NCtlInt" 8 "TrqCtrl" 10 "UdcCtlBatt" 14 "Discharge" 15 "FwCtl" ;
VAL_ 268 DesiredSpeed5 65534 "Init" 65535 "Error" ;
VAL_ 268 DesiredTorque5 2047 "Error" 2046 "Init" ;
VAL_ 268 UdcSetP5 1022 "Init" 1023 "Error" ;
VAL_ 268 Checksum_10C 0 "Init" ;
VAL_ 268 MessageCounter_10C 0 "Init" ;
VAL_ 268 StHvbMaiRly5 0 "Opened" 1 "Closed" 2 "PreCharge" 3 "BatteryFailure" 4 "-" 5 "-" 6 "Init" 7 "Failure" ;
VAL_ 312 MessageCounter_138 0 "Init" ;
VAL_ 312 Checksum_138 0 "Init" ;
VAL_ 312 VoltageDemandLV5 510 "Init" 511 "Error" ;
VAL_ 312 VoltageDemandHV5 1022 "Init" 1023 "Error" ;
VAL_ 312 ModeRequest5 0 "OFF" 1 "Buck" ;
VAL_ 312 CurrentDemandLV5 2046 "Init" 2047 "Error" ;
VAL_ 312 CurrentDemandHV5 2046 "Init" 2047 "Error" ;
VAL_ 788 UdcMin5 1022 "Init" 1023 "Error" ;
VAL_ 788 UdcMax5 1022 "Init" 1023 "Error" ;
VAL_ 788 IdcMin5 2046 "Init" 2047 "Error" ;
VAL_ 788 IdcMax5 2046 "Init" 2047 "Error" ;
VAL_ 788 MessageCounter_314 0 "Init" ;
VAL_ 788 Checksum_314 0 "Init" ;
VAL_ 788 flgInvrCanActvnCmd5 1 "INV5 communication demand - ON" 0 "INV5 communication demand - OFF" ;
VAL_ 790 KI_Faktor5 32766 "Init" 32767 "Error" ;
VAL_ 790 MessageCounter_316 0 "Init" ;
VAL_ 790 Checksum_316 0 "Init" ;
VAL_ 790 MinTorqueLimit5 2046 "Init" 2047 "Error" ;
VAL_ 790 MaxTorqueLimit5 2046 "Init" 2047 "Error" ;
VAL_ 790 MaxTorqueGradient5 32766 "Init" 32767 "Error" ;
VAL_ 524 CurrentHV5 1023 "Init" ;
VAL_ 524 OutputTorque5 2047 "Failure" 2046 "Init" ;
VAL_ 524 State5 0 "Init" 1 "DrvInit" 3 "Standby" 4 "UdcCtl" 5 "AlOffsetCal" 6 "NCtlExt" 7 "NCtlInt" 8 "TrqCtl" 10 "UdcCtlBatt" 11 "Afterrun" 13 "Failure" 14 "Discharge" 15 "FwCtl" ;
VAL_ 524 Speed5 65534 "Init" 65535 "Error" ;
VAL_ 524 Checksum_20C 0 "Init" ;
VAL_ 524 MessageCounter_20C 0 "Init" ;
VAL_ 536 dataInvrNr5 5 "Inverter5" 4 "Inverter4" 3 "Inverter3" 2 "Inverter2" 1 "Inverter1" 0 "Not configured" ;
VAL_ 536 MaxTorque5 1023 "Init" ;
VAL_ 536 MinTorque5 1023 "Init" ;
VAL_ 536 Checksum_218 0 "Init" ;
VAL_ 536 MessageCounter_218 0 "Init" ;
VAL_ 536 TrqCurrWoDstC5 1023 "Init" ;
VAL_ 536 TempCurrCool5 254 "Init" 255 "Error" ;
VAL_ 552 Mode5 0 "Off" 1 "Buck" 5 "Failure" ;
VAL_ 552 CurrentLV5 1023 "Init" ;
VAL_ 552 VoltageLV5 0 "Init" ;
VAL_ 552 DcCurrentHV5 1024 "Init" ;
VAL_ 552 VoltageHV5 0 "Init" ;
VAL_ 552 TempCurr5 254 "Init" 255 "Error" ;
VAL_ 552 Checksum_228 0 "Init" ;
VAL_ 552 MessageCounter_228 0 "Init" ;
VAL_ 1576 ElectricMachineTemperature5 254 "Init" 255 "Error" ;
VAL_ 1576 InverterTemperature5 254 "Init" 255 "Error" ;
VAL_ 1576 UT30Curr5 0 "Init" ;
VAL_ 1576 TempCurrRotor5 254 "Init" 255 "Error" ;
VAL_ 1576 Checksum_628 0 "Init" ;
VAL_ 1576 MessageCounter_628 0 "Init" ;
VAL_ 1049 DC_MaxCurrentLV5 1023 "Init" ;
VAL_ 1049 DC_MaxCurrentHV5 0 "Init" ;
VAL_ 1049 bDernUndrUdcLV5 0 "Init" ;
VAL_ 1049 ErrShtOff5 0 "Init" ;
VAL_ 1049 bDernOvrIdcLv5 0 "Init" ;
VAL_ 1049 bDernOvrIdcHV5 0 "Init" ;
VAL_ 1049 bDernOvrUdcLv5 0 "Init" ;
VAL_ 1049 bDernUndrUdcHV5 0 "Init" ;
VAL_ 1049 ErrLimitedPerformance5 0 "Init" ;
VAL_ 1049 bDernTemp_DCDC5 0 "Init" ;
VAL_ 1049 bDernOvrUdcHV5 0 "Init" ;
VAL_ 1049 bErrVltg5 0 "Init" ;
VAL_ 1049 Checksum_419 0 "Init" ;
VAL_ 1049 MessageCounter_419 0 "Init" ;
VAL_ 1032 EmergencyShutoffRequest5 0 "NoShutOffRequested" 1 "ShutOffRequested" ;
VAL_ 1032 bDernOvrUdc5 0 "Init" ;
VAL_ 1032 bDernUndrUdc5 0 "Init" ;
VAL_ 1032 Checksum_408 0 "Init" ;
VAL_ 1032 MessageCounter_408 0 "Init" ;
VAL_ 1032 bDernOvrIdc5 0 "Init" ;
VAL_ 1032 bDernUndrIdc5 0 "Init" ;
VAL_ 1032 bDernTemp5 0 "Init" ;
VAL_ 1032 bDiagReq5 0 "Init" ;
VAL_ 1032 bDernTrqMin5 0 "Init" ;
VAL_ 1032 bDernTrqMax5 0 "Init" ;
VAL_ 1032 bDstActv5 0 "Init" ;
VAL_ 1032 bReadyHV5 0 "Init" ;
